VERSION ""

NS_ :

BS_:

BU_: SBZA_R_LS SBZA_L_LS VIS2_LS SDM_LS PEPS_LS UPA_LS PTM_LS MSM_LS HFP_LS EOCM_F_LS ECC_LS DCAC_LS CGM_LS BSM_LS BCM_LS AOS_LS
VAL_TABLE_ vt_BooleanValues 1 "true" 0 "false" ;
VAL_TABLE_ ValidityStates 1 "Invalid" 0 "Valid" ;

BO_ 3221225472 VECTOR__INDEPENDENT_SIG_MSG: 0 Vector__XXX
 SG_ ODIEDDIPC_Data11Value : 0|3@0+ (1,0) [0|7] "" Vector__XXX
 SG_ ODIEDDIPC_Data10Value : 0|3@0+ (1,0) [0|7] "" Vector__XXX
 SG_ ODIEDDIPC_Data9Value : 0|3@0+ (1,0) [0|7] "" Vector__XXX
 SG_ ODIEDDIPC_Data8Value : 0|3@0+ (1,0) [0|7] "" Vector__XXX
 SG_ ODIEDDIPC_Data7Value : 0|3@0+ (1,0) [0|7] "" Vector__XXX
 SG_ ODIEDDIPC_Data6Value : 0|3@0+ (1,0) [0|7] "" Vector__XXX
 SG_ ODIEDDIPC_Data5Value : 0|3@0+ (1,0) [0|7] "" Vector__XXX
 SG_ ODIEDDIPC_Data4Value : 0|3@0+ (1,0) [0|7] "" Vector__XXX
 SG_ ODIEDDIPC_Data3Value : 0|3@0+ (1,0) [0|7] "" Vector__XXX
 SG_ ODIEDDIPC_Data2Value : 0|3@0+ (1,0) [0|7] "" Vector__XXX
 SG_ ODIEDDIPC_Data1Value : 0|3@0+ (1,0) [0|7] "" Vector__XXX
 SG_ ODIEDDCS_FUCID : 0|8@0+ (1,0) [0|255] "" Vector__XXX
 SG_ ODIEDDCS_Data9Value : 0|3@0+ (1,0) [0|7] "" Vector__XXX
 SG_ ODIEDDCS_Data8Value : 0|3@0+ (1,0) [0|7] "" Vector__XXX
 SG_ ODIEDDCS_Data7Value : 0|3@0+ (1,0) [0|7] "" Vector__XXX
 SG_ ODIEDDCS_Data6Value : 0|3@0+ (1,0) [0|7] "" Vector__XXX
 SG_ ODIEDDCS_Data5Value : 0|3@0+ (1,0) [0|7] "" Vector__XXX
 SG_ ODIEDDCS_Data4Value : 0|3@0+ (1,0) [0|7] "" Vector__XXX
 SG_ ODIEDDCS_Data3Value : 0|3@0+ (1,0) [0|7] "" Vector__XXX
 SG_ ODIEDDCS_Data2Value : 0|3@0+ (1,0) [0|7] "" Vector__XXX
 SG_ ODIEDDCS_Data18Value : 0|3@0+ (1,0) [0|7] "" Vector__XXX
 SG_ ODIEDDCS_Data17Value : 0|3@0+ (1,0) [0|7] "" Vector__XXX
 SG_ ODIEDDCS_Data16Value : 0|3@0+ (1,0) [0|7] "" Vector__XXX
 SG_ ODIEDDCS_Data15Value : 0|3@0+ (1,0) [0|7] "" Vector__XXX
 SG_ ODIEDDCS_Data14Value : 0|3@0+ (1,0) [0|7] "" Vector__XXX
 SG_ ODIEDDCS_Data13Value : 0|3@0+ (1,0) [0|7] "" Vector__XXX
 SG_ ODIEDDCS_Data12Value : 0|3@0+ (1,0) [0|7] "" Vector__XXX
 SG_ ODIEDDCS_Data11Value : 0|3@0+ (1,0) [0|7] "" Vector__XXX
 SG_ ODIEDDCS_Data10Value : 0|3@0+ (1,0) [0|7] "" Vector__XXX
 SG_ ODIEDDCS_Data1Value : 0|3@0+ (1,0) [0|7] "" Vector__XXX
 SG_ ODIEDDIPC_FUCID : 0|8@0+ (1,0) [0|255] "" Vector__XXX
 SG_ ODIEDDIPC_Data18Value : 0|3@0+ (1,0) [0|7] "" Vector__XXX
 SG_ ODIEDDIPC_Data17Value : 0|3@0+ (1,0) [0|7] "" Vector__XXX
 SG_ ODIEDDIPC_Data16Value : 0|3@0+ (1,0) [0|7] "" Vector__XXX
 SG_ ODIEDDIPC_Data15Value : 0|3@0+ (1,0) [0|7] "" Vector__XXX
 SG_ ODIEDDIPC_Data14Value : 0|3@0+ (1,0) [0|7] "" Vector__XXX
 SG_ ODIEDDIPC_Data13Value : 0|3@0+ (1,0) [0|7] "" Vector__XXX
 SG_ ODIEDDIPC_Data12Value : 0|3@0+ (1,0) [0|7] "" Vector__XXX
 SG_ DrThrtlOvrrdDetProtVal : 0|2@0+ (1,0) [0|3] "" Vector__XXX
 SG_ IMUProtLonAccM : 0|1@0+ (1,0) [0|1] "" Vector__XXX
 SG_ ARSActAngl : 0|11@0- (0.01,0) [-10.24|10.23] "deg" Vector__XXX
 SG_ BPDAPS_BkPDrvApPV : 0|1@0+ (1,0) [0|1] "" Vector__XXX
 SG_ BPDAPS_BkPDrvApP : 0|8@0+ (75,0) [0|19125] "kPa" Vector__XXX
 SG_ DrvThrottlOvrrdDet : 0|1@0+ (1,0) [0|1] "" Vector__XXX
 SG_ OvrdrvDsblReqd : 0|1@0+ (1,0) [0|1] "" Vector__XXX

BO_ 599 USDT_Req_to_SBZA_R_LS: 8 CGM_LS
 SG_ DgnInf : 7|64@0+ (1,0) [0|1.84467440737096E+019] ""  SBZA_R_LS

BO_ 1367 UUDT_Resp_From_SBZA_R_LS: 8 SBZA_R_LS
 SG_ DgnInf_LS557 : 7|64@0+ (1,0) [0|1.84467440737096E+019] ""  CGM_LS

BO_ 1623 USDT_Resp_From_SBZA_R_LS: 8 SBZA_R_LS
 SG_ DgnInf : 7|64@0+ (1,0) [0|1.84467440737096E+019] ""  CGM_LS

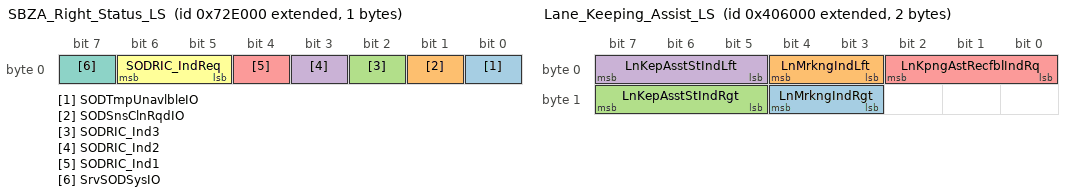
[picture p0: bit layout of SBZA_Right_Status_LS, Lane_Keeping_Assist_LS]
BO_ 2155012096 SBZA_Right_Status_LS: 1 SBZA_R_LS
 SG_ SODTmpUnavlbleIO : 0|1@0+ (1,0) [0|1] ""  SBZA_L_LS
 SG_ SODSnsClnRqdIO : 1|1@0+ (1,0) [0|1] ""  SBZA_L_LS
 SG_ SODRIC_Ind3 : 2|1@0+ (1,0) [0|1] ""  SBZA_L_LS
 SG_ SODRIC_Ind2 : 3|1@0+ (1,0) [0|1] ""  SBZA_L_LS
 SG_ SODRIC_Ind1 : 4|1@0+ (1,0) [0|1] ""  SBZA_L_LS
 SG_ SODRIC_IndReq : 6|2@0+ (1,0) [0|3] ""  SBZA_L_LS
 SG_ SrvSODSysIO : 7|1@0+ (1,0) [0|1] ""  SBZA_L_LS

BO_ 932 Temp_Diag_CAN_Resp_LS_3A4: 8 Vector__XXX
 SG_ DgnInf : 7|64@0+ (1,0) [0|1.84467440737096E+019] ""  CGM_LS

BO_ 936 Temp_Diag_CAN_Resp_LS_3A8: 8 Vector__XXX
 SG_ DgnInf : 7|64@0+ (1,0) [0|1.84467440737096E+019] ""  CGM_LS

BO_ 921 Temp_Diag_CAN_Resp_LS_399: 8 Vector__XXX
 SG_ DgnInf : 7|64@0+ (1,0) [0|1.84467440737096E+019] ""  CGM_LS

BO_ 2151702528 Lane_Keeping_Assist_LS: 2 EOCM_F_LS
 SG_ LnMrkngIndRgt : 12|2@0+ (1,0) [0|3] ""  CGM_LS
 SG_ LnMrkngIndLft : 4|2@0+ (1,0) [0|3] ""  CGM_LS
 SG_ LnKepAsstStIndRgt : 15|3@0+ (1,0) [0|7] ""  CGM_LS
 SG_ LnKepAsstStIndLft : 7|3@0+ (1,0) [0|7] ""  CGM_LS
 SG_ LnKpngAstRecfblIndRq : 2|3@0+ (1,0) [0|7] ""  CGM_LS

BO_ 2155126784 Drvr_Seat_Rearward_Movmnt_LS: 1 MSM_LS
 SG_ DrvrSetRrwrdMvmnt : 7|3@0+ (1,0) [0|7] ""  CGM_LS

BO_ 2155102208 Driver_Seat_Massage_Priority_LS: 8 MSM_LS
 SG_ DSMP_UnsdRsrvd : 56|1@0+ (1,0) [0|1] ""  CGM_LS
 SG_ DSMP_MaxDispVal : 59|3@0+ (1,0) [0|7] ""  CGM_LS
 SG_ DSMP_Type15 : 63|4@0+ (1,0) [0|15] ""  CGM_LS
 SG_ DSMP_Type14 : 51|4@0+ (1,0) [0|15] ""  CGM_LS
 SG_ DSMP_Type13 : 55|4@0+ (1,0) [0|15] ""  CGM_LS
 SG_ DSMP_Type12 : 43|4@0+ (1,0) [0|15] ""  CGM_LS
 SG_ DSMP_Type11 : 47|4@0+ (1,0) [0|15] ""  CGM_LS
 SG_ DSMP_Type10 : 35|4@0+ (1,0) [0|15] ""  CGM_LS
 SG_ DSMP_Type9 : 39|4@0+ (1,0) [0|15] ""  CGM_LS
 SG_ DSMP_Type8 : 27|4@0+ (1,0) [0|15] ""  CGM_LS
 SG_ DSMP_Type7 : 31|4@0+ (1,0) [0|15] ""  CGM_LS
 SG_ DSMP_Type6 : 19|4@0+ (1,0) [0|15] ""  CGM_LS
 SG_ DSMP_Type5 : 23|4@0+ (1,0) [0|15] ""  CGM_LS
 SG_ DSMP_Type4 : 11|4@0+ (1,0) [0|15] ""  CGM_LS
 SG_ DSMP_Type3 : 15|4@0+ (1,0) [0|15] ""  CGM_LS
 SG_ DSMP_Type2 : 3|4@0+ (1,0) [0|15] ""  CGM_LS
 SG_ DSMP_Type1 : 7|4@0+ (1,0) [0|15] ""  CGM_LS

BO_ 2155085824 Driver_Seat_Control_Disp_Stat_LS: 8 MSM_LS
 SG_ StrgColUpDwnPos : 63|8@0+ (1,0) [0|255] ""  CGM_LS
 SG_ CPMAPINFO4 : 5|1@0+ (1,0) [0|1] ""  CGM_LS
 SG_ StrgColInOutPos : 55|8@0+ (1,0) [0|255] ""  CGM_LS
 SG_ StrgColCommsFlt : 7|2@0+ (1,0) [0|3] ""  CGM_LS
 SG_ DSCDS_UnsdRsrvd : 42|3@0+ (1,0) [0|7] ""  CGM_LS
 SG_ DSCDS_DispReq : 43|1@0+ (1,0) [0|1] ""  CGM_LS
 SG_ DSCDS_DispSz : 45|2@0+ (1,0) [0|3] ""  CGM_LS
 SG_ DSCDS_CshLgAdjFdRr : 47|2@0+ (1,0) [0|3] ""  CGM_LS
 SG_ DSCDS_BkCshBlstInOt : 34|3@0+ (1,0) [0|7] ""  CGM_LS
 SG_ DSCDS_CshBlstrInOut : 36|2@0+ (1,0) [0|3] ""  CGM_LS
 SG_ DSCDS_BkBlstrInOut : 38|2@0+ (1,0) [0|3] ""  CGM_LS
 SG_ DSCDS_LmbrUDnFdRr : 25|3@0+ (1,0) [0|7] ""  CGM_LS
 SG_ DSCDS_LmbrFwdRr : 27|2@0+ (1,0) [0|3] ""  CGM_LS
 SG_ DSCDS_LmbrUpDwn : 29|2@0+ (1,0) [0|3] ""  CGM_LS
 SG_ DSCDS_UprShldrFdRr : 31|2@0+ (1,0) [0|3] ""  CGM_LS
 SG_ DSCDS_HdrstTltFwdRr : 17|2@0+ (1,0) [0|3] ""  CGM_LS
 SG_ DSCDS_HdrstWngInOt : 19|2@0+ (1,0) [0|3] ""  CGM_LS
 SG_ DSCDS_HdrstUDnFdRr : 22|3@0+ (1,0) [0|7] ""  CGM_LS
 SG_ DSCDS_HdrstFwdRrwd : 8|2@0+ (1,0) [0|3] ""  CGM_LS
 SG_ DSCDS_HdrstUpDn : 10|2@0+ (1,0) [0|3] ""  CGM_LS
 SG_ DSCDS_MassgIntsty : 13|3@0+ (1,0) [0|7] ""  CGM_LS
 SG_ DSCDS_MassgTyp : 1|4@0+ (1,0) [0|15] ""  CGM_LS
 SG_ DSCDS_Massg : 3|2@0+ (1,0) [0|3] ""  CGM_LS

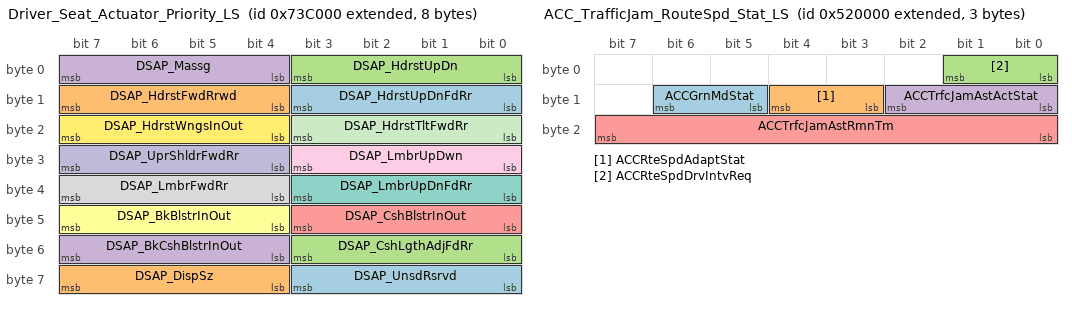
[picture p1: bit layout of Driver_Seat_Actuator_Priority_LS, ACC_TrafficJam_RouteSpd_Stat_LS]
BO_ 2155069440 Driver_Seat_Actuator_Priority_LS: 8 MSM_LS
 SG_ DSAP_UnsdRsrvd : 59|4@0+ (1,0) [0|15] ""  CGM_LS
 SG_ DSAP_DispSz : 63|4@0+ (1,0) [0|15] ""  CGM_LS
 SG_ DSAP_CshLgthAdjFdRr : 51|4@0+ (1,0) [0|15] ""  CGM_LS
 SG_ DSAP_BkCshBlstrInOut : 55|4@0+ (1,0) [0|15] ""  CGM_LS
 SG_ DSAP_CshBlstrInOut : 43|4@0+ (1,0) [0|15] ""  CGM_LS
 SG_ DSAP_BkBlstrInOut : 47|4@0+ (1,0) [0|15] ""  CGM_LS
 SG_ DSAP_LmbrUpDnFdRr : 35|4@0+ (1,0) [0|15] ""  CGM_LS
 SG_ DSAP_LmbrFwdRr : 39|4@0+ (1,0) [0|15] ""  CGM_LS
 SG_ DSAP_LmbrUpDwn : 27|4@0+ (1,0) [0|15] ""  CGM_LS
 SG_ DSAP_UprShldrFwdRr : 31|4@0+ (1,0) [0|15] ""  CGM_LS
 SG_ DSAP_HdrstTltFwdRr : 19|4@0+ (1,0) [0|15] ""  CGM_LS
 SG_ DSAP_HdrstWngsInOut : 23|4@0+ (1,0) [0|15] ""  CGM_LS
 SG_ DSAP_HdrstUpDnFdRr : 11|4@0+ (1,0) [0|15] ""  CGM_LS
 SG_ DSAP_HdrstFwdRrwd : 15|4@0+ (1,0) [0|15] ""  CGM_LS
 SG_ DSAP_HdrstUpDn : 3|4@0+ (1,0) [0|15] ""  CGM_LS
 SG_ DSAP_Massg : 7|4@0+ (1,0) [0|15] ""  CGM_LS

BO_ 2034 CCP_Data_Transmission_Object_LS: 8 VIS2_LS
 SG_ DgnInf : 7|64@0+ (1,0) [0|1.84467440737096E+019] "" Vector__XXX

BO_ 2152857600 ACC_TrafficJam_RouteSpd_Stat_LS: 3 EOCM_F_LS
 SG_ ACCGrnMdStat : 14|2@0+ (1,0) [0|3] ""  CGM_LS
 SG_ ACCRteSpdAdaptStat : 12|2@0+ (1,0) [0|3] ""  CGM_LS
 SG_ ACCRteSpdDrvIntvReq : 1|2@0+ (1,0) [0|3] ""  CGM_LS
 SG_ ACCTrfcJamAstActStat : 10|3@0+ (1,0) [0|7] ""  CGM_LS
 SG_ ACCTrfcJamAstRmnTm : 23|8@0+ (1,0) [0|255] "sec"  CGM_LS

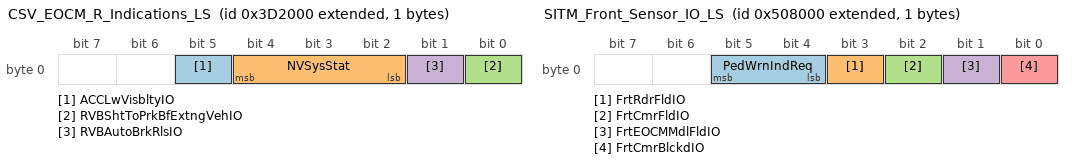
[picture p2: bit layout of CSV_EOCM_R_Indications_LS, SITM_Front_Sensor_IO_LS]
BO_ 2151489536 CSV_EOCM_R_Indications_LS: 1 EOCM_F_LS
 SG_ ACCLwVisbltyIO : 5|1@0+ (1,0) [0|1] ""  CGM_LS
 SG_ NVSysStat : 4|3@0+ (1,0) [0|7] ""  CGM_LS
 SG_ RVBShtToPrkBfExtngVehIO : 0|1@0+ (1,0) [0|1] ""  CGM_LS
 SG_ RVBAutoBrkRlsIO : 1|1@0+ (1,0) [0|1] ""  CGM_LS

BO_ 2152759296 SITM_Front_Sensor_IO_LS: 1 EOCM_F_LS
 SG_ PedWrnIndReq : 5|2@0+ (1,0) [0|3] ""  CGM_LS
 SG_ FrtRdrFldIO : 3|1@0+ (1,0) [0|1] ""  CGM_LS
 SG_ FrtCmrFldIO : 2|1@0+ (1,0) [0|1] ""  CGM_LS
 SG_ FrtEOCMMdlFldIO : 1|1@0+ (1,0) [0|1] ""  CGM_LS
 SG_ FrtCmrBlckdIO : 0|1@0+ (1,0) [0|1] ""  CGM_LS

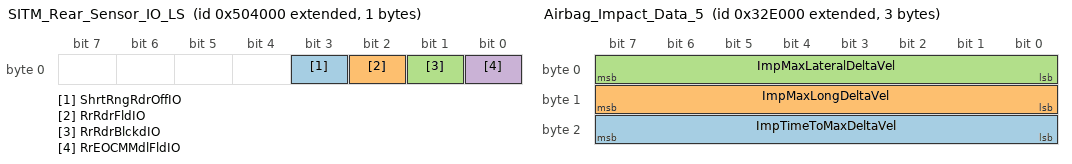
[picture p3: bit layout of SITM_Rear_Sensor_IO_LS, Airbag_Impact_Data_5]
BO_ 2152742912 SITM_Rear_Sensor_IO_LS: 1 EOCM_F_LS
 SG_ ShrtRngRdrOffIO : 3|1@0+ (1,0) [0|1] ""  CGM_LS
 SG_ RrRdrFldIO : 2|1@0+ (1,0) [0|1] ""  CGM_LS
 SG_ RrRdrBlckdIO : 1|1@0+ (1,0) [0|1] ""  CGM_LS
 SG_ RrEOCMMdlFldIO : 0|1@0+ (1,0) [0|1] ""  CGM_LS

BO_ 1591 VNMF_LS_637_SBZA_R: 8 SBZA_R_LS
 SG_ VectraSpcNWMgtD : 7|64@0+ (1,0) [0|1.84467440737096E+019] ""  SBZA_L_LS

BO_ 1355 UUDT_Resp_From_FCM_LS: 8 EOCM_F_LS
 SG_ DgnInf_LS54B : 7|64@0+ (1,0) [0|1.84467440737096E+019] ""  CGM_LS

BO_ 1611 USDT_Resp_From_FCM_LS: 8 EOCM_F_LS
 SG_ DgnInf : 7|64@0+ (1,0) [0|1.84467440737096E+019] ""  CGM_LS

BO_ 1603 USDT_Resp_From_AGC_LS: 8 DCAC_LS
 SG_ DgnInf : 7|64@0+ (1,0) [0|1.84467440737096E+019] ""  CGM_LS

BO_ 1347 UUDT_Resp_From_AGC_LS: 8 DCAC_LS
 SG_ DgnInf_LS543 : 7|64@0+ (1,0) [0|1.84467440737096E+019] ""  CGM_LS

BO_ 2154995712 Air_Conditioning_Comp_Type_LS: 1 ECC_LS
 SG_ HVHtrFldIO : 4|1@0+ (1,0) [0|1] ""  CGM_LS
 SG_ HVHtrOvrTmpIndOn : 3|1@0+ (1,0) [0|1] ""  CGM_LS

BO_ 2150817792 Airbag_Impact_Data_5: 3 SDM_LS
 SG_ ImpTimeToMaxDeltaVel : 23|8@0+ (10,0) [0|2550] "ms"  CGM_LS
 SG_ ImpMaxLongDeltaVel : 15|8@0- (1,0) [-128|127] ""  CGM_LS
 SG_ ImpMaxLateralDeltaVel : 7|8@0- (1,0) [-128|127] ""  CGM_LS

BO_ 1621 USDT_Resp_From_VIS2_LS: 8 VIS2_LS
 SG_ DgnInf : 7|64@0+ (1,0) [0|1.84467440737096E+019] ""  CGM_LS

BO_ 1365 UUDT_Resp_From_VIS2_LS: 8 VIS2_LS
 SG_ DgnInf_LS555 : 7|64@0+ (1,0) [0|1.84467440737096E+019] ""  CGM_LS

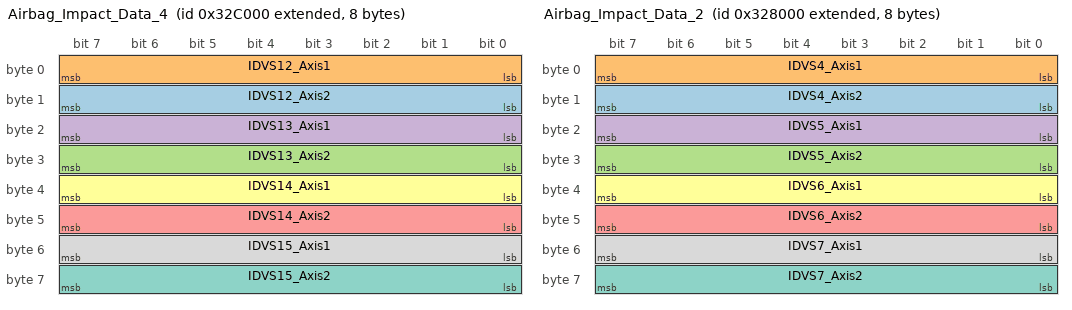
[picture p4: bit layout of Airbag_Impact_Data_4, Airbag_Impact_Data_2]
BO_ 2150809600 Airbag_Impact_Data_4: 8 SDM_LS
 SG_ IDVS12_Axis2 : 15|8@0- (1,0) [-128|127] "counts"  CGM_LS
 SG_ IDVS12_Axis1 : 7|8@0- (1,0) [-128|127] "counts"  CGM_LS
 SG_ IDVS13_Axis2 : 31|8@0- (1,0) [-128|127] "counts"  CGM_LS
 SG_ IDVS13_Axis1 : 23|8@0- (1,0) [-128|127] "counts"  CGM_LS
 SG_ IDVS14_Axis2 : 47|8@0- (1,0) [-128|127] "counts"  CGM_LS
 SG_ IDVS14_Axis1 : 39|8@0- (1,0) [-128|127] "counts"  CGM_LS
 SG_ IDVS15_Axis2 : 63|8@0- (1,0) [-128|127] "counts"  CGM_LS
 SG_ IDVS15_Axis1 : 55|8@0- (1,0) [-128|127] "counts"  CGM_LS

BO_ 2150793216 Airbag_Impact_Data_2: 8 SDM_LS
 SG_ IDVS4_Axis2 : 15|8@0- (1,0) [-128|127] "counts"  CGM_LS
 SG_ IDVS4_Axis1 : 7|8@0- (1,0) [-128|127] "counts"  CGM_LS
 SG_ IDVS5_Axis2 : 31|8@0- (1,0) [-128|127] "counts"  CGM_LS
 SG_ IDVS5_Axis1 : 23|8@0- (1,0) [-128|127] "counts"  CGM_LS
 SG_ IDVS6_Axis2 : 47|8@0- (1,0) [-128|127] "counts"  CGM_LS
 SG_ IDVS6_Axis1 : 39|8@0- (1,0) [-128|127] "counts"  CGM_LS
 SG_ IDVS7_Axis2 : 63|8@0- (1,0) [-128|127] "counts"  CGM_LS
 SG_ IDVS7_Axis1 : 55|8@0- (1,0) [-128|127] "counts"  CGM_LS

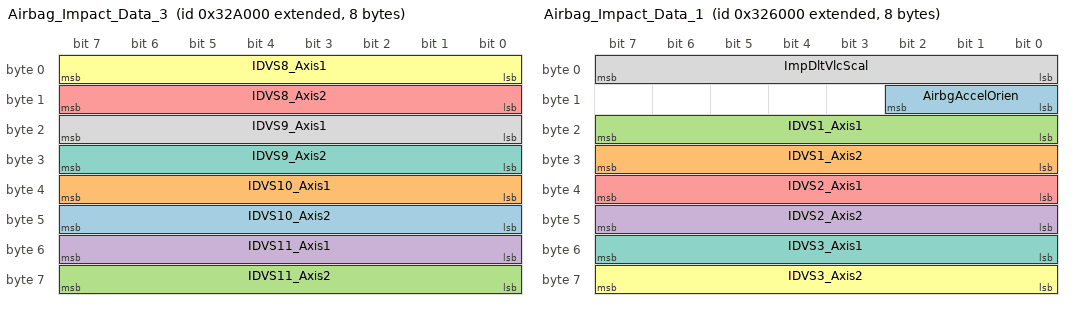
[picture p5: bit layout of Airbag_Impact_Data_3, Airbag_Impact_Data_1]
BO_ 2150801408 Airbag_Impact_Data_3: 8 SDM_LS
 SG_ IDVS10_Axis2 : 47|8@0- (1,0) [-128|127] "counts"  CGM_LS
 SG_ IDVS10_Axis1 : 39|8@0- (1,0) [-128|127] "counts"  CGM_LS
 SG_ IDVS11_Axis2 : 63|8@0- (1,0) [-128|127] "counts"  CGM_LS
 SG_ IDVS11_Axis1 : 55|8@0- (1,0) [-128|127] "counts"  CGM_LS
 SG_ IDVS8_Axis2 : 15|8@0- (1,0) [-128|127] "counts"  CGM_LS
 SG_ IDVS8_Axis1 : 7|8@0- (1,0) [-128|127] "counts"  CGM_LS
 SG_ IDVS9_Axis2 : 31|8@0- (1,0) [-128|127] "counts"  CGM_LS
 SG_ IDVS9_Axis1 : 23|8@0- (1,0) [-128|127] "counts"  CGM_LS

BO_ 2150785024 Airbag_Impact_Data_1: 8 SDM_LS
 SG_ AirbgAccelOrien : 10|3@0+ (45,0) [0|315] "deg"  CGM_LS
 SG_ IDVS1_Axis2 : 31|8@0- (1,0) [-128|127] "counts"  CGM_LS
 SG_ IDVS1_Axis1 : 23|8@0- (1,0) [-128|127] "counts"  CGM_LS
 SG_ IDVS2_Axis2 : 47|8@0- (1,0) [-128|127] "counts"  CGM_LS
 SG_ IDVS2_Axis1 : 39|8@0- (1,0) [-128|127] "counts"  CGM_LS
 SG_ IDVS3_Axis2 : 63|8@0- (1,0) [-128|127] "counts"  CGM_LS
 SG_ IDVS3_Axis1 : 55|8@0- (1,0) [-128|127] "counts"  CGM_LS
 SG_ ImpDltVlcScal : 7|8@0+ (0.00245,0.706) [0.706|1.33075] "kph/cnt"  CGM_LS

BO_ 2150825984 Airbag_Indications: 6 SDM_LS
 SG_ PdstIntdProtSysDplyd : 46|1@0+ (1,0) [0|1] ""  CGM_LS
 SG_ PdstIntdProtSysDsbld : 45|1@0+ (1,0) [0|1] ""  CGM_LS
 SG_ SrvIntdPdstProtSysIO : 44|1@0+ (1,0) [0|1] ""  CGM_LS
 SG_ FstnThrdRwRtPsStbtInR : 41|2@0+ (1,0) [0|3] ""  CGM_LS
 SG_ FstnThrdRwLtPsStbtInR : 43|2@0+ (1,0) [0|3] ""  CGM_LS
 SG_ FstnThrdRwCtPsStbtInR : 39|2@0+ (1,0) [0|3] ""  CGM_LS
 SG_ FPSIC_IndPer : 11|4@0+ (1,0) [0|15] ""  CGM_LS
 SG_ FPSIC_IO : 15|1@0+ (1,0) [0|1] ""  CGM_LS
 SG_ FPSIC_IndDtCyc : 14|3@0+ (12.5,12.5) [12.5|100] "%"  CGM_LS
 SG_ FDSIC_IndPer : 3|4@0+ (1,0) [0|15] ""  CGM_LS
 SG_ FDSIC_IO : 7|1@0+ (1,0) [0|1] ""  CGM_LS
 SG_ FDSIC_IndDC : 6|3@0+ (12.5,12.5) [12.5|100] "%"  CGM_LS
 SG_ AirbgFldIO : 35|1@0+ (1,0) [0|1] ""  CGM_LS
 SG_ SndRwStbltRdIndMd : 37|2@0+ (1,0) [0|3] ""  CGM_LS
 SG_ AirbgICIndPer : 19|4@0+ (1,0) [0|15] ""  CGM_LS
 SG_ AirbgICDutCyc : 22|3@0+ (12.5,12.5) [12.5|100] "%"  CGM_LS
 SG_ AirbgICIO : 23|1@0+ (1,0) [0|1] ""  CGM_LS
 SG_ FstnSndRwRtPsStbtInR : 29|2@0+ (1,0) [0|3] ""  CGM_LS
 SG_ FstnSndRwLtPsStbtInR : 25|2@0+ (1,0) [0|3] ""  CGM_LS
 SG_ FstnSndRwCtPsStbtInR : 27|2@0+ (1,0) [0|3] ""  CGM_LS
 SG_ FsnDrStbAuxIR : 31|2@0+ (1,0) [0|3] ""  CGM_LS
 SG_ FsnPsStbAuxIR : 34|3@0+ (1,0) [0|7] ""  CGM_LS

BO_ 1351 UUDT_Resp_From_SDM_LS: 8 SDM_LS
 SG_ DgnInf_LS547 : 7|64@0+ (1,0) [0|1.84467440737096E+019] ""  CGM_LS

BO_ 1607 USDT_Resp_From_SDM_LS: 8 SDM_LS
 SG_ DgnInf : 7|64@0+ (1,0) [0|1.84467440737096E+019] ""  CGM_LS

BO_ 1602 USDT_Resp_From_PEPS_PBSM_LS: 8 PEPS_LS
 SG_ DgnInf : 7|64@0+ (1,0) [0|1.84467440737096E+019] ""  CGM_LS

BO_ 1346 UUDT_Resp_From_PEPS_PBSM_LS: 8 PEPS_LS
 SG_ DgnInf_LS542 : 7|64@0+ (1,0) [0|1.84467440737096E+019] ""  CGM_LS

BO_ 1361 UUDT_Resp_From_ECC_HVAC_LS: 8 ECC_LS
 SG_ DgnInf_LS551 : 7|64@0+ (1,0) [0|1.84467440737096E+019] ""  CGM_LS

BO_ 1617 USDT_Resp_From_ECC_HVAC_LS: 8 ECC_LS
 SG_ DgnInf : 7|64@0+ (1,0) [0|1.84467440737096E+019] ""  CGM_LS

BO_ 1373 UUDT_Resp_From_DSM_LS: 8 MSM_LS
 SG_ DgnInf_LS55D : 7|64@0+ (1,0) [0|1.84467440737096E+019] ""  CGM_LS

BO_ 1629 USDT_Resp_From_DSM_LS: 8 MSM_LS
 SG_ DgnInf : 7|64@0+ (1,0) [0|1.84467440737096E+019] ""  CGM_LS

BO_ 602 USDT_Req_to_SBZA_L_LS: 8 CGM_LS
 SG_ DgnInf : 7|64@0+ (1,0) [0|1.84467440737096E+019] ""  SBZA_L_LS

BO_ 164 Temp_Diag_CAN_Req_LS_0A4: 8 CGM_LS
 SG_ DgnInf : 7|64@0+ (1,0) [0|1.84467440737096E+019] "" Vector__XXX

BO_ 104 Temp_Diag_CAN_Req_LS_068: 8 CGM_LS
 SG_ DgnInf : 7|64@0+ (1,0) [0|1.84467440737096E+019] "" Vector__XXX

BO_ 88 Temp_Diag_CAN_Req_LS_058: 8 CGM_LS
 SG_ DgnInf : 7|64@0+ (1,0) [0|1.84467440737096E+019] "" Vector__XXX

BO_ 168 Temp_Diag_CAN_Req_LS_0A8: 8 CGM_LS
 SG_ DgnInf : 7|64@0+ (1,0) [0|1.84467440737096E+019] "" Vector__XXX

BO_ 153 Temp_Diag_CAN_Req_LS_099: 8 CGM_LS
 SG_ DgnInf : 7|64@0+ (1,0) [0|1.84467440737096E+019] "" Vector__XXX

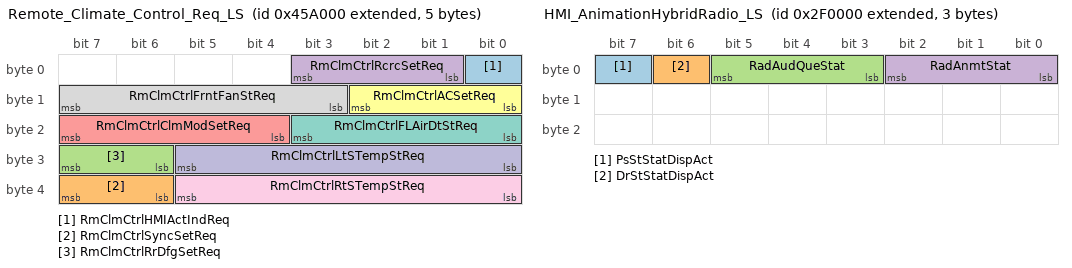
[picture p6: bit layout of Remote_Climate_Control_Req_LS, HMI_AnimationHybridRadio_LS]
BO_ 2152046592 Remote_Climate_Control_Req_LS: 5 CGM_LS
 SG_ RmClmCtrlHMIActIndReq : 0|1@0+ (1,0) [0|1] ""  ECC_LS
 SG_ RmClmCtrlSyncSetReq : 39|2@0+ (1,0) [0|3] ""  ECC_LS
 SG_ RmClmCtrlRrDfgSetReq : 31|2@0+ (1,0) [0|3] ""  ECC_LS
 SG_ RmClmCtrlRcrcSetReq : 3|3@0+ (1,0) [0|7] ""  ECC_LS
 SG_ RmClmCtrlClmModSetReq : 23|4@0+ (1,0) [0|15] ""  ECC_LS
 SG_ RmClmCtrlACSetReq : 10|3@0+ (1,0) [0|7] ""  ECC_LS
 SG_ RmClmCtrlFLAirDtStReq : 19|4@0+ (1,0) [0|15] ""  ECC_LS
 SG_ RmClmCtrlFrntFanStReq : 15|5@0+ (1,0) [0|31] ""  ECC_LS
 SG_ RmClmCtrlRtSTempStReq : 37|6@0+ (1,0) [0|63] ""  ECC_LS
 SG_ RmClmCtrlLtSTempStReq : 29|6@0+ (1,0) [0|63] ""  ECC_LS

BO_ 2032 CCP_Command_Receive_Object_LS: 8 CGM_LS
 SG_ DgnInf : 7|64@0+ (1,0) [0|1.84467440737096E+019] ""  PTM_LS,VIS2_LS

BO_ 2150563840 HMI_AnimationHybridRadio_LS: 3 CGM_LS
 SG_ PsStStatDispAct : 7|1@0+ (1,0) [0|1] "" Vector__XXX
 SG_ DrStStatDispAct : 6|1@0+ (1,0) [0|1] ""  MSM_LS
 SG_ RadAudQueStat : 5|3@0+ (1,0) [0|7] "" Vector__XXX
 SG_ RadAnmtStat : 2|3@0+ (1,0) [0|7] "" Vector__XXX

BO_ 2151948288 Driver_Drow_Det_Cst_Rqst_LS: 1 CGM_LS
 SG_ RunBrdOpMdCstStReq : 7|3@0+ (1,0) [0|7] "" Vector__XXX
 SG_ DrvDrowDetCstStRq : 2|3@0+ (1,0) [0|7] ""  VIS2_LS

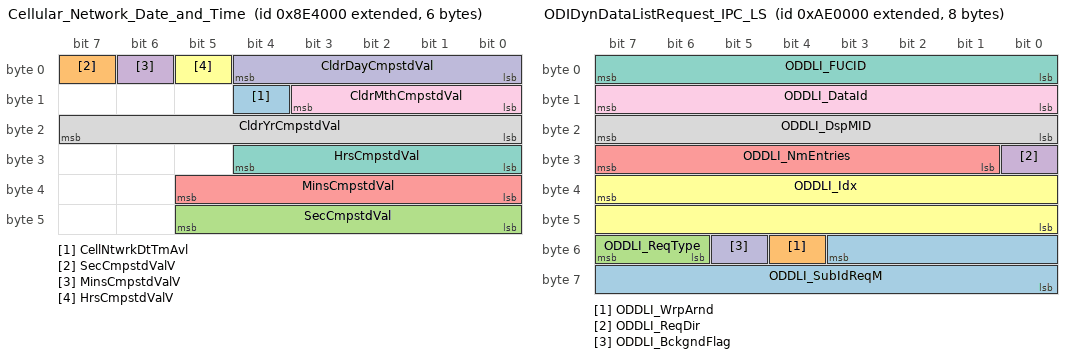
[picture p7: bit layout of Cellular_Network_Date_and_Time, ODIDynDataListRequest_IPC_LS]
BO_ 2156806144 Cellular_Network_Date_and_Time: 6 CGM_LS
 SG_ CellNtwrkDtTmAvl : 12|1@0+ (1,0) [0|1] "" Vector__XXX
 SG_ SecCmpstdValV : 7|1@0+ (1,0) [0|1] "" Vector__XXX
 SG_ SecCmpstdVal : 45|6@0+ (1,0) [0|63] "secs" Vector__XXX
 SG_ MinsCmpstdValV : 6|1@0+ (1,0) [0|1] "" Vector__XXX
 SG_ MinsCmpstdVal : 37|6@0+ (1,0) [0|63] "min" Vector__XXX
 SG_ HrsCmpstdValV : 5|1@0+ (1,0) [0|1] "" Vector__XXX
 SG_ HrsCmpstdVal : 28|5@0+ (1,0) [0|31] "h" Vector__XXX
 SG_ CldrYrCmpstdVal : 23|8@0+ (1,2000) [2000|2255] "year" Vector__XXX
 SG_ CldrMthCmpstdVal : 11|4@0+ (1,0) [0|15] ""  ECC_LS
 SG_ CldrDayCmpstdVal : 4|5@0+ (1,0) [0|31] "days"  ECC_LS

BO_ 1350 UUDT_Resp_From_ICS_LS: 8 CGM_LS
 SG_ DgnInf_LS546 : 7|64@0+ (1,0) [0|1.84467440737096E+019] ""  CGM_LS

BO_ 2158886912 ODIDynDataListRequest_IPC_LS: 8 CGM_LS
 SG_ ODDLI_SubIdReqM : 51|12@0+ (1,0) [0|4095] ""  VIS2_LS
 SG_ ODDLI_WrpArnd : 52|1@0+ (1,0) [0|1] ""  VIS2_LS
 SG_ ODDLI_ReqType : 55|2@0+ (1,0) [0|3] ""  VIS2_LS
 SG_ ODDLI_ReqDir : 24|1@0+ (1,0) [0|1] ""  VIS2_LS
 SG_ ODDLI_NmEntries : 31|7@0+ (1,0) [0|127] ""  VIS2_LS
 SG_ ODDLI_Idx : 39|16@0+ (1,0) [0|65535] ""  VIS2_LS
 SG_ ODDLI_FUCID : 7|8@0+ (1,0) [0|255] ""  VIS2_LS
 SG_ ODDLI_DspMID : 23|8@0+ (1,0) [0|255] ""  VIS2_LS
 SG_ ODDLI_DataId : 15|8@0+ (1,0) [0|255] ""  VIS2_LS
 SG_ ODDLI_BckgndFlag : 53|1@0+ (1,0) [0|1] ""  VIS2_LS

BO_ 579 USDT_Req_to_AGC_LS: 8 CGM_LS
 SG_ DgnInf : 7|64@0+ (1,0) [0|1.84467440737096E+019] ""  DCAC_LS

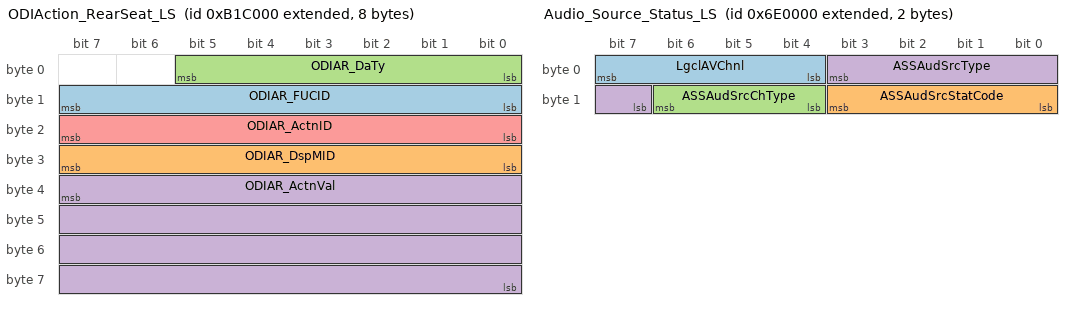
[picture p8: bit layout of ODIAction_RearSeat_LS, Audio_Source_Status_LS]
BO_ 2159132672 ODIAction_RearSeat_LS: 8 CGM_LS
 SG_ ODIAR_FUCID : 15|8@0+ (1,0) [0|255] ""  ECC_LS
 SG_ ODIAR_DspMID : 31|8@0+ (1,0) [0|255] ""  ECC_LS
 SG_ ODIAR_DaTy : 5|6@0+ (1,0) [0|63] ""  ECC_LS
 SG_ ODIAR_ActnVal : 39|32@0+ (1,0) [0|4294967295] ""  ECC_LS
 SG_ ODIAR_ActnID : 23|8@0+ (1,0) [0|255] ""  ECC_LS

BO_ 2154692608 Audio_Source_Status_LS: 2 CGM_LS
 SG_ LgclAVChnl : 7|4@0+ (1,0) [0|15] "" Vector__XXX
 SG_ ASSAudSrcStatCode : 11|4@0+ (1,0) [0|15] ""  ECC_LS
 SG_ ASSAudSrcChType : 14|3@0+ (1,0) [0|7] ""  ECC_LS
 SG_ ASSAudSrcType : 3|5@0+ (1,0) [0|31] ""  ECC_LS

BO_ 597 USDT_Req_to_VIS2_LS: 8 CGM_LS
 SG_ DgnInf : 7|64@0+ (1,0) [0|1.84467440737096E+019] ""  VIS2_LS

BO_ 1357 UUDT_Resp_From_UHP_ONS_LS: 8 CGM_LS
 SG_ DgnInf_LS54D : 7|64@0+ (1,0) [0|1.84467440737096E+019] ""  CGM_LS

BO_ 1608 USDT_Resp_From_PDIM_LS: 8 HFP_LS
 SG_ DgnInf : 7|64@0+ (1,0) [0|1.84467440737096E+019] ""  CGM_LS

BO_ 584 USDT_Req_to_PDIM_LS: 8 CGM_LS
 SG_ DgnInf : 7|64@0+ (1,0) [0|1.84467440737096E+019] ""  HFP_LS

BO_ 1352 UUDT_Resp_From_PDIM_LS: 8 CGM_LS
 SG_ DgnInf_LS548 : 7|64@0+ (1,0) [0|1.84467440737096E+019] ""  CGM_LS

BO_ 583 USDT_Req_to_SDM_LS: 8 CGM_LS
 SG_ DgnInf : 7|64@0+ (1,0) [0|1.84467440737096E+019] ""  SDM_LS

BO_ 1348 UUDT_Resp_From_RadioHead_LS: 8 CGM_LS
 SG_ DgnInf_LS544 : 7|64@0+ (1,0) [0|1.84467440737096E+019] ""  CGM_LS

BO_ 591 USDT_Req_to_PTM_STC_LS: 8 CGM_LS
 SG_ DgnInf : 7|64@0+ (1,0) [0|1.84467440737096E+019] ""  PTM_LS

BO_ 578 USDT_Req_to_PEPS_PBSM_LS: 8 CGM_LS
 SG_ DgnInf : 7|64@0+ (1,0) [0|1.84467440737096E+019] ""  PEPS_LS

BO_ 1356 UUDT_Resp_From_IPC_LS: 8 CGM_LS
 SG_ DgnInf_LS54C : 7|64@0+ (1,0) [0|1.84467440737096E+019] ""  CGM_LS

BO_ 1360 UUDT_Resp_From_HUD_LS: 8 CGM_LS
 SG_ DgnInf_LS550 : 7|64@0+ (1,0) [0|1.84467440737096E+019] ""  CGM_LS

BO_ 1616 USDT_Resp_From_HUD_LS: 8 CGM_LS
 SG_ DgnInf : 7|64@0+ (1,0) [0|1.84467440737096E+019] ""  CGM_LS

BO_ 593 USDT_Req_to_ECC_HVAC_LS: 8 CGM_LS
 SG_ DgnInf : 7|64@0+ (1,0) [0|1.84467440737096E+019] ""  ECC_LS

BO_ 605 USDT_Req_to_DSM_LS: 8 CGM_LS
 SG_ DgnInf : 7|64@0+ (1,0) [0|1.84467440737096E+019] ""  MSM_LS

BO_ 587 USDT_Req_to_FCM_LS: 8 CGM_LS
 SG_ DgnInf : 7|64@0+ (1,0) [0|1.84467440737096E+019] ""  EOCM_F_LS

BO_ 2020 USDT_Req_to_VICM_LS: 8 CGM_LS
 SG_ DgnInf : 7|64@0+ (1,0) [0|1.84467440737096E+019] ""  BSM_LS

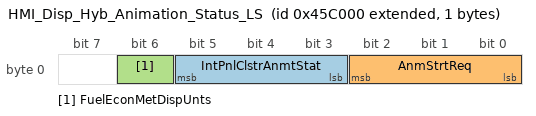
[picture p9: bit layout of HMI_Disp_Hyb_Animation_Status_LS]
BO_ 2152054784 HMI_Disp_Hyb_Animation_Status_LS: 1 CGM_LS
 SG_ IntPnlClstrAnmtStat : 5|3@0+ (1,0) [0|7] "" Vector__XXX
 SG_ AnmStrtReq : 2|3@0+ (1,0) [0|7] "" Vector__XXX
 SG_ FuelEconMetDispUnts : 6|1@0+ (1,0) [0|1] ""  BSM_LS

BO_ 2156281856 High_Volt_Bat_Time_Bsd_Req_1_LS: 7 CGM_LS
 SG_ LftmEffDtRstRqd : 18|1@0+ (1,0) [0|1] "" Vector__XXX
 SG_ HTRCsStReq : 37|3@0+ (1,0) [0|7] "" Vector__XXX
 SG_ TODCTmpImdtOvrdReq : 39|2@0+ (1,0) [0|3] ""  BSM_LS
 SG_ RtBsChrgCmplnTmPrfReq : 34|2@0+ (1,0) [0|3] ""  BSM_LS
 SG_ TONPDTR_StTmpOvrAtv : 32|2@0+ (1,0) [0|3] ""  BSM_LS
 SG_ TONPDTR_MntOfHr : 53|6@0+ (1,0) [0|63] "Minute"  BSM_LS
 SG_ TONPDTR_HrOfDy : 42|5@0+ (1,0) [0|31] "Hour"  BSM_LS
 SG_ TONPDTR_DyOfWk : 46|4@0+ (1,0) [0|15] ""  BSM_LS
 SG_ StTODChrgTmpOvrd : 7|1@0+ (1,0) [0|1] ""  BSM_LS
 SG_ HVBTBSCSR_SsnStReq : 0|2@0+ (1,0) [0|3] ""  BSM_LS
 SG_ HVBTBSCSR_SsnSlStReq : 14|3@0+ (1,0) [0|7] ""  BSM_LS
 SG_ HVBTBSCSR_SsnMthStReq : 11|4@0+ (1,0) [0|15] ""  BSM_LS
 SG_ HVBTBSCSR_SsnDayStReq : 23|5@0+ (1,0) [0|31] "day"  BSM_LS
 SG_ HVBTBCRSR_ChRtSlStReq : 27|4@0+ (1,0) [0|15] ""  BSM_LS
 SG_ HVBTBCRSR_ChRtEnblStReq : 17|2@0+ (1,0) [0|3] ""  BSM_LS
 SG_ HVBTBCRSR_ChRtDStReq : 31|4@0+ (1,0) [0|15] ""  BSM_LS
 SG_ HVBatTmBsChrgMdReq : 3|3@0+ (1,0) [0|7] ""  BSM_LS
 SG_ HVChgSyChgLvlPrfSt : 6|3@0+ (1,0) [0|7] ""  BSM_LS

BO_ 2156265472 High_Volt_Bat_Time_Bsd_Req_LS: 8 CGM_LS
 SG_ EngyUsgScrnMeasUtStat : 39|4@0+ (1,0) [0|15] ""  BSM_LS
 SG_ OffBrdHVCVehCsChRq : 35|1@0+ (1,0) [0|1] ""  BSM_LS
 SG_ PrtyChrgRq : 7|2@0+ (1,0) [0|3] ""  BSM_LS
 SG_ HVBTBRCSR_RtChSlStReq : 42|3@0+ (1,0) [0|7] ""  BSM_LS
 SG_ HVBTBRCSR_RtChSlRtStReq : 46|4@0+ (1,0) [0|15] ""  BSM_LS
 SG_ HVBTBRCSR_RtChSsnStReq : 50|2@0+ (1,0) [0|3] ""  BSM_LS
 SG_ HVBTBRCSR_RtChMHStReq : 48|6@0+ (1,0) [0|63] "min"  BSM_LS
 SG_ HVBTBRCSR_RtChHStReq : 55|5@0+ (1,0) [0|31] "hr"  BSM_LS
 SG_ HVBTBRCSR_RtChDStReq : 34|4@0+ (1,0) [0|15] ""  BSM_LS
 SG_ HVBTBRCSR_RtChSlTbRwReq : 58|3@0+ (1,0) [0|7] "rows"  BSM_LS
 SG_ HVBTBDCSRQ_DlChSlStReq : 19|4@0+ (1,0) [0|15] ""  BSM_LS
 SG_ HVBTBDCSRQ_DlChSsnStReq : 31|2@0+ (1,0) [0|3] ""  BSM_LS
 SG_ HVBTBDCSRQ_DlChMHStReq : 29|6@0+ (1,0) [0|63] "min"  BSM_LS
 SG_ HVBTBDCSRQ_DlChHStReq : 12|5@0+ (1,0) [0|31] "hr"  BSM_LS
 SG_ HVBTBDCSRQ_DlChDStReq : 23|4@0+ (1,0) [0|15] ""  BSM_LS
 SG_ ChgPwLsAlCzStRq : 5|3@0+ (1,0) [0|7] ""  BSM_LS
 SG_ ChgCdTfAlCzStRq : 2|3@0+ (1,0) [0|7] ""  BSM_LS
 SG_ ChgSysAudInCsStReq : 15|3@0+ (1,0) [0|7] ""  BSM_LS

BO_TX_BU_ 2034 : PTM_LS,VIS2_LS;
BO_TX_BU_ 1352 : HFP_LS,CGM_LS;

CM_ BU_ SBZA_R_LS "Side Blind Zone Alert Right";
CM_ BU_ SBZA_L_LS "Side Blind Zone Alert Left";
CM_ BU_ VIS2_LS "Vision Camera";
CM_ BU_ SDM_LS "Sensing Diagnostic Module";
CM_ BU_ PEPS_LS "Passive Entry Passive Start";
CM_ BU_ UPA_LS "Universal Parking Assist";
CM_ BU_ PTM_LS "Power Tailgate Module";
CM_ BU_ MSM_LS "Driver Seat Module";
CM_ BU_ HFP_LS "HVAC Faceplate";
CM_ BU_ EOCM_F_LS "External Object Control Module - Front";
CM_ BU_ ECC_LS "Electronic Climate Control";
CM_ BU_ DCAC_LS "DC-AC Power Inverter";
CM_ BU_ CGM_LS "Communication Gateway";
CM_ BU_ BSM_LS "Battery State Manager";
CM_ BU_ BCM_LS "Body Control Module and LS Side Global Architecture Gateway";
CM_ BU_ AOS_LS "Automatic Occupant Sensing";
CM_ BO_ 3221225472 "This is a message for not used signals, created by Vector CANdb++ DBC OLE DB Provider.";
CM_ SG_ 3221225472 ODIEDDIPC_Data11Value "ODI";
CM_ SG_ 3221225472 ODIEDDIPC_Data10Value "ODI";
CM_ SG_ 3221225472 ODIEDDIPC_Data9Value "ODI";
CM_ SG_ 3221225472 ODIEDDIPC_Data8Value "ODI";
CM_ SG_ 3221225472 ODIEDDIPC_Data7Value "ODI";
CM_ SG_ 3221225472 ODIEDDIPC_Data6Value "ODI";
CM_ SG_ 3221225472 ODIEDDIPC_Data5Value "ODI";
CM_ SG_ 3221225472 ODIEDDIPC_Data4Value "ODI";
CM_ SG_ 3221225472 ODIEDDIPC_Data3Value "ODI";
CM_ SG_ 3221225472 ODIEDDIPC_Data2Value "ODI";
CM_ SG_ 3221225472 ODIEDDIPC_Data1Value "ODI";
CM_ SG_ 3221225472 ODIEDDCS_FUCID "ODI - Primary ID of Functional Unit in FU Database";
CM_ SG_ 3221225472 ODIEDDCS_Data9Value "ODI";
CM_ SG_ 3221225472 ODIEDDCS_Data8Value "ODI";
CM_ SG_ 3221225472 ODIEDDCS_Data7Value "ODI";
CM_ SG_ 3221225472 ODIEDDCS_Data6Value "ODI";
CM_ SG_ 3221225472 ODIEDDCS_Data5Value "ODI";
CM_ SG_ 3221225472 ODIEDDCS_Data4Value "ODI";
CM_ SG_ 3221225472 ODIEDDCS_Data3Value "ODI";
CM_ SG_ 3221225472 ODIEDDCS_Data2Value "ODI";
CM_ SG_ 3221225472 ODIEDDCS_Data18Value "ODI";
CM_ SG_ 3221225472 ODIEDDCS_Data17Value "ODI";
CM_ SG_ 3221225472 ODIEDDCS_Data16Value "ODI";
CM_ SG_ 3221225472 ODIEDDCS_Data15Value "ODI";
CM_ SG_ 3221225472 ODIEDDCS_Data14Value "ODI";
CM_ SG_ 3221225472 ODIEDDCS_Data13Value "ODI";
CM_ SG_ 3221225472 ODIEDDCS_Data12Value "ODI";
CM_ SG_ 3221225472 ODIEDDCS_Data11Value "ODI";
CM_ SG_ 3221225472 ODIEDDCS_Data10Value "ODI";
CM_ SG_ 3221225472 ODIEDDCS_Data1Value "ODI";
CM_ SG_ 3221225472 ODIEDDIPC_FUCID "ODI - Primary ID of Functional Unit in FU Database";
CM_ SG_ 3221225472 ODIEDDIPC_Data18Value "ODI";
CM_ SG_ 3221225472 ODIEDDIPC_Data17Value "ODI";
CM_ SG_ 3221225472 ODIEDDIPC_Data16Value "ODI";
CM_ SG_ 3221225472 ODIEDDIPC_Data15Value "ODI";
CM_ SG_ 3221225472 ODIEDDIPC_Data14Value "ODI";
CM_ SG_ 3221225472 ODIEDDIPC_Data13Value "ODI";
CM_ SG_ 3221225472 ODIEDDIPC_Data12Value "ODI";
CM_ SG_ 2150785024 AirbgAccelOrien "Orientation of first accelerometer axis.  0 degrees is right side of vehicle, 90 degrees is front of vehicle.  Second axis given by adding 90 degrees to first axis.";
CM_ SG_ 2158886912 ODDLI_SubIdReqM "ODI-The number of list entries, starting at the Index, to send";
CM_ SG_ 2158886912 ODDLI_WrpArnd "ODI-Boolean that shall be set to true if the list shall wrap around.";
CM_ SG_ 2158886912 ODDLI_ReqType "ODI - Type of Request";
CM_ SG_ 2158886912 ODDLI_ReqDir "ODI-Boolean that shall be set to true if req down, set to false if set to up";
CM_ SG_ 2158886912 ODDLI_NmEntries "ODI-The number of list entries, starting at the Index, to send";
CM_ SG_ 2158886912 ODDLI_Idx "ODI-The index within the remote FU’s list at which to start sending data";
CM_ SG_ 2158886912 ODDLI_FUCID "ODI - Primary ID of Functional Unit in FU Database";
CM_ SG_ 2158886912 ODDLI_DspMID "ODI - ID that identifies the display requesting the data.  See detailed requirements in ODI GMLAN Protocol.";
CM_ SG_ 2158886912 ODDLI_DataId "ODI-Data Id for the dynamic list";
CM_ SG_ 2158886912 ODDLI_BckgndFlag "ODI-Informs FU as to priority of response.
Applies to all DataIds in the message.
$0=Immediate response required
$1=Background response";
CM_ SG_ 2159132672 ODIAR_FUCID "ODI - Primary ID of Functional Unit in FU Database";
CM_ SG_ 2159132672 ODIAR_DspMID "ODI - ID that identifies the display requesting the data.  See detailed requirements in ODI GMLAN Protocol.";
CM_ SG_ 2159132672 ODIAR_ActnVal "ODI-Integer value for Actions with values.
FUDatabase definition of Action includes ActionDataType that defines whether or not Action has a value. 
For Actions without a value, this field is always sent as 0.";
CM_ SG_ 2159132672 ODIAR_ActnID "ODI-ActionId within the FUClass";
BA_DEF_ SG_  "VNSigDiagnostic" ENUM  "No","Yes","DLCLS","DLCHS","DLCCE","DLCFO";
BA_DEF_ SG_  "VNSigUnused_4" ENUM  "No","Yes","DLCLS","DLCHS","DLCCE","DLCFO";
BA_DEF_ SG_  "VNSigIntermediate" ENUM  "No","Yes","DLCLS","DLCHS","DLCCE","DLCFO";
BA_DEF_ SG_  "VNSigParkedVehicle" ENUM  "No","Yes","DLCLS","DLCHS","DLCCE","DLCFO";
BA_DEF_ SG_  "VNSigRemoteDiagnostics" ENUM  "No","Yes","DLCLS","DLCHS","DLCCE","DLCFO";
BA_DEF_ SG_  "GenSigSendOnInit" ENUM  "Not Initialized","Application","Handler","DLCLS","DLCHS","DLCCE","DLCFO";
BA_DEF_ SG_  "GenSigSendType" ENUM  "not used","not used","not used","not used","not used","not used","not used","NoSigSendType","not used","not used","OnAnyChange","OnChangeIfActive","OnDelta","DLCLS","DLCHS","DLCCE","DLCFO";
BA_DEF_ SG_  "GenSigInactiveValue" INT 0 0;
BA_DEF_ SG_  "GenSigDeltaValue" INT 0 0;
BA_DEF_ SG_  "VNSigAllNodes" ENUM  "No","Yes","DLCLS","DLCHS","DLCCE","DLCFO";
BA_DEF_ SG_  "SignalType" STRING ;
BA_DEF_ SG_  "PacketOrder" INT 0 65535;
BA_DEF_ SG_  "SignalLongName" STRING ;
BA_DEF_ SG_  "GenSigStartValue" INT 0 65535;
BA_DEF_ SG_  "TxSignalSendOnInit" ENUM  "Not Initialized","Application","Handler";
BA_DEF_ BO_  "GenMsgILSupport" ENUM  "No","Yes","DLCLS","DLCHS","DLCCE","DLCFO";
BA_DEF_ BO_  "TpApplType" STRING ;
BA_DEF_ BO_  "Prio" INT 0 7;
BA_DEF_ BO_  "MessageSubnet" ENUM  "LS","MS","HS","CE","PE","HV","FO","S1","HE","LE","HE2","DLCLS","DLCHS","DLCCE","DLCFO","vector_leerstring";
BA_DEF_ BO_  "DiagState" ENUM  "No","Yes";
BA_DEF_ BO_  "GenMsgIlSupport" ENUM  "No","Yes";
BA_DEF_ BO_  "GenMsgStartDelayTime" INT 0 100000;
BA_DEF_ BO_  "GenMsgDelayTime" INT 0 100000;
BA_DEF_ BO_  "GenMsgCycleTime" INT 0 100000;
BA_DEF_ BO_  "GenMsgSendType" ENUM  "cyclicX","spontanX","cyclicIfActiveX","spontanWithDelay","cyclicAndSpontanX","cyclicAndSpontanWithDelay","spontanWithRepitition","cyclicIfActiveAndSpontanWD";
BA_DEF_ BO_  "DiagResponse" ENUM  "No","Yes";
BA_DEF_ BO_  "DiagRequest" ENUM  "No","Yes";
BA_DEF_ BO_  "NmMessage" ENUM  "No","Yes";
BA_DEF_ BU_  "MessageManagerUsed" ENUM  "No","Yes","DLCLS","DLCHS","DLCCE","DLCFO";
BA_DEF_ BU_  "NmNode" ENUM  "No","Yes";
BA_DEF_ BU_  "ILUsed" ENUM  "No","Yes";
BA_DEF_ BU_  "FillCharacter" HEX 0 255;
BA_DEF_ BU_  "FlashSegmentSize" INT 0 256;
BA_DEF_ BU_  "NodeLayerModules" STRING ;
BA_DEF_ BU_  "VNECURemoteDiagnostics" ENUM  "None","Activator","Remoted","Activator and Remoted","Shared Local","DLCLS","DLCHS","DLCCE","DLCFO";
BA_DEF_ BU_  "VNECUParkedVehicle" ENUM  "None","Activator","Remoted","Activator and Remoted","Shared Local","DLCLS","DLCHS","DLCCE","DLCFO";
BA_DEF_ BU_  "VNECUIntermediate" ENUM  "None","Activator","Remoted","Activator and Remoted","Shared Local","DLCLS","DLCHS","DLCCE","DLCFO";
BA_DEF_ BU_  "VNECUDiagnostic" ENUM  "None","Activator","Remoted","Activator and Remoted","Shared Local","DLCLS","DLCHS","DLCCE","DLCFO";
BA_DEF_ BU_  "VNECUAllNodes" ENUM  "None","Activator","Remoted","Activator and Remoted","Shared Local","DLCLS","DLCHS","DLCCE","DLCFO";
BA_DEF_ BU_  "VNECUPrimaryTriggering" ENUM  "None","Activated","Remoted","Activator and Remoted","Shared Local";
BA_DEF_ BU_  "VNECUInfotainment" ENUM  "None","Activator","Remoted","Activator and Remoted","Shared Local";
BA_DEF_ BU_  "ECU_Id" HEX 0 255;
BA_DEF_ BU_  "SourceId" HEX 0 253;
BA_DEF_  "VN_Diagnostic" INT 0 255;
BA_DEF_  "VN_Unused_4" INT 0 255;
BA_DEF_  "VN_Intermediate" INT 0 255;
BA_DEF_  "VN_ParkedVehicle" INT 0 255;
BA_DEF_  "VN_RemoteDiagnostics" INT 0 255;
BA_DEF_  "VN_AllNodes" INT 0 255;
BA_DEF_  "VNInitActDiagnostic" ENUM  "No","Yes","DLCLS","DLCHS","DLCCE","DLCFO";
BA_DEF_  "VNInitActPrimaryTriggering" ENUM  "No","Yes","DLCLS","DLCHS","DLCCE","DLCFO";
BA_DEF_  "VehicleArchitecture" STRING ;
BA_DEF_  "Baudrate" INT 0 1000000;
BA_DEF_  "SamplePointMin" FLOAT 0 100;
BA_DEF_  "SamplePointMax" FLOAT 0 100;
BA_DEF_  "SyncJumpWidthMin" INT 0 255;
BA_DEF_  "SyncJumpWidthMax" INT 0 255;
BA_DEF_  "VersionMonth" INT 0 255;
BA_DEF_  "BusType" STRING ;
BA_DEF_  "NmMessageCount" INT 0 32;
BA_DEF_  "NmBaseAddress" HEX 0 2032;
BA_DEF_  "NetworkType" STRING ;
BA_DEF_  "VNMFPeriodicInterval" INT 0 65535;
BA_DEF_  "BusWakeUpDelay" INT 0 65535;
BA_DEF_  "BusOffRecoveryTime" INT 0 65535;
BA_DEF_  "VN_PrimaryTriggering" INT 0 56;
BA_DEF_  "VN_Infotainment" INT 0 56;
BA_DEF_  "NodeStatusMsgID" HEX 0 536870911;
BA_DEF_  "NodeStatusMsgCycleTime" INT 0 65535;
BA_DEF_  "NodeStatusMsgTimeoutTime" INT 0 65535;
BA_DEF_  "UseGMParameterIDs" INT 0 1;
BA_DEF_  "VersionWeek" INT 0 255;
BA_DEF_  "VersionYear" INT 0 255;
BA_DEF_  "Manufacturer" ENUM  "DBAG","VAG","BMW","PAG","GM";
BA_DEF_  "NmType" STRING ;
BA_DEF_REL_ BU_SG_REL_  "GenSigSuprvResp" ENUM  "None","Notify App","Substitute Default","DLCLS","DLCHS","DLCCE","DLCFO";
BA_DEF_REL_ BU_SG_REL_  "GenSigSuprvRespSubValue" INT 0 65535;
BA_DEF_REL_ BU_SG_REL_  "GenSigRxStartValue" STRING ;
BA_DEF_REL_ BU_SG_REL_  "GenSigVDAFailResp" ENUM  "No","Yes","DLCLS","DLCHS","DLCCE","DLCFO";
BA_DEF_REL_ BU_SG_REL_  "GenSigVDAFailComment" STRING ;
BA_DEF_REL_ BU_SG_REL_  "GenSigVBitRespComment" STRING ;
BA_DEF_REL_ BU_SG_REL_  "GenSigVBitResp" ENUM  "No","Yes","DLCLS","DLCHS","DLCCE","DLCFO";
BA_DEF_REL_ BU_SG_REL_  "GenSigSuprvRespComment" STRING ;
BA_DEF_REL_ BU_SG_REL_  "GenSigTimeoutTime" INT 0 5000;
BA_DEF_DEF_  "VNSigDiagnostic" "No";
BA_DEF_DEF_  "VNSigUnused_4" "No";
BA_DEF_DEF_  "VNSigIntermediate" "No";
BA_DEF_DEF_  "VNSigParkedVehicle" "No";
BA_DEF_DEF_  "VNSigRemoteDiagnostics" "No";
BA_DEF_DEF_  "GenSigSendOnInit" "Not Initialized";
BA_DEF_DEF_  "GenSigSendType" "NoSigSendType";
BA_DEF_DEF_  "GenSigInactiveValue" 0;
BA_DEF_DEF_  "GenSigDeltaValue" 0;
BA_DEF_DEF_  "VNSigAllNodes" "No";
BA_DEF_DEF_  "SignalType" "";
BA_DEF_DEF_  "PacketOrder" 0;
BA_DEF_DEF_  "SignalLongName" "";
BA_DEF_DEF_  "GenSigStartValue" 0;
BA_DEF_DEF_  "TxSignalSendOnInit" "Not Initialized";
BA_DEF_DEF_  "GenMsgILSupport" "Yes";
BA_DEF_DEF_  "TpApplType" "";
BA_DEF_DEF_  "Prio" 0;
BA_DEF_DEF_  "MessageSubnet" "LS";
BA_DEF_DEF_  "DiagState" "No";
BA_DEF_DEF_  "GenMsgIlSupport" "Yes";
BA_DEF_DEF_  "GenMsgStartDelayTime" 0;
BA_DEF_DEF_  "GenMsgDelayTime" 0;
BA_DEF_DEF_  "GenMsgCycleTime" 0;
BA_DEF_DEF_  "GenMsgSendType" "spontanX";
BA_DEF_DEF_  "DiagResponse" "No";
BA_DEF_DEF_  "DiagRequest" "No";
BA_DEF_DEF_  "NmMessage" "No";
BA_DEF_DEF_REL_ "GenSigSuprvResp" "None";
BA_DEF_DEF_REL_ "GenSigSuprvRespSubValue" 0;
BA_DEF_DEF_REL_ "GenSigRxStartValue" "";
BA_DEF_DEF_REL_ "GenSigVDAFailResp" "No";
BA_DEF_DEF_REL_ "GenSigVDAFailComment" "";
BA_DEF_DEF_REL_ "GenSigVBitRespComment" "";
BA_DEF_DEF_REL_ "GenSigVBitResp" "No";
BA_DEF_DEF_REL_ "GenSigSuprvRespComment" "";
BA_DEF_DEF_REL_ "GenSigTimeoutTime" 0;
BA_DEF_DEF_  "MessageManagerUsed" "Yes";
BA_DEF_DEF_  "NmNode" "Yes";
BA_DEF_DEF_  "ILUsed" "Yes";
BA_DEF_DEF_  "FillCharacter" 255;
BA_DEF_DEF_  "FlashSegmentSize" 8;
BA_DEF_DEF_  "NodeLayerModules" "gmlan02.dll";
BA_DEF_DEF_  "VNECURemoteDiagnostics" "None";
BA_DEF_DEF_  "VNECUParkedVehicle" "None";
BA_DEF_DEF_  "VNECUIntermediate" "None";
BA_DEF_DEF_  "VNECUDiagnostic" "None";
BA_DEF_DEF_  "VNECUAllNodes" "None";
BA_DEF_DEF_  "VNECUPrimaryTriggering" "None";
BA_DEF_DEF_  "VNECUInfotainment" "None";
BA_DEF_DEF_  "ECU_Id" 0;
BA_DEF_DEF_  "SourceId" 0;
BA_DEF_DEF_  "VN_Diagnostic" 0;
BA_DEF_DEF_  "VN_Unused_4" 4;
BA_DEF_DEF_  "VN_Intermediate" 3;
BA_DEF_DEF_  "VN_ParkedVehicle" 6;
BA_DEF_DEF_  "VN_RemoteDiagnostics" 5;
BA_DEF_DEF_  "VN_AllNodes" 1;
BA_DEF_DEF_  "VNInitActDiagnostic" "No";
BA_DEF_DEF_  "VNInitActPrimaryTriggering" "No";
BA_DEF_DEF_  "VehicleArchitecture" "";
BA_DEF_DEF_  "Baudrate" 0;
BA_DEF_DEF_  "SamplePointMin" 0;
BA_DEF_DEF_  "SamplePointMax" 0;
BA_DEF_DEF_  "SyncJumpWidthMin" 0;
BA_DEF_DEF_  "SyncJumpWidthMax" 0;
BA_DEF_DEF_  "VersionMonth" 0;
BA_DEF_DEF_  "BusType" "";
BA_DEF_DEF_  "NmMessageCount" 32;
BA_DEF_DEF_  "NmBaseAddress" 1568;
BA_DEF_DEF_  "NetworkType" "";
BA_DEF_DEF_  "VNMFPeriodicInterval" 3000;
BA_DEF_DEF_  "BusWakeUpDelay" 100;
BA_DEF_DEF_  "BusOffRecoveryTime" 0;
BA_DEF_DEF_  "VN_PrimaryTriggering" 7;
BA_DEF_DEF_  "VN_Infotainment" 4;
BA_DEF_DEF_  "NodeStatusMsgID" 268433408;
BA_DEF_DEF_  "NodeStatusMsgCycleTime" 1200;
BA_DEF_DEF_  "NodeStatusMsgTimeoutTime" 3000;
BA_DEF_DEF_  "UseGMParameterIDs" 1;
BA_DEF_DEF_  "VersionWeek" 0;
BA_DEF_DEF_  "VersionYear" 0;
BA_DEF_DEF_  "Manufacturer" "GM";
BA_DEF_DEF_  "NmType" "GMLAN";
BA_ "VNInitActDiagnostic" 1;
BA_ "VNInitActPrimaryTriggering" 1;
BA_ "VehicleArchitecture" "GlobalA";
BA_ "Baudrate" 33333;
BA_ "SamplePointMin" 85;
BA_ "SamplePointMax" 89.48;
BA_ "SyncJumpWidthMin" 2;
BA_ "SyncJumpWidthMax" 3;
BA_ "VersionMonth" 19;
BA_ "BusType" "CAN";
BA_ "NetworkType" "Bodybus";
BA_ "BusWakeUpDelay" 70;
BA_ "BusOffRecoveryTime" 3700;
BA_ "VN_Infotainment" 2;
BA_ "NodeStatusMsgID" 335536128;
BA_ "VersionWeek" 41;
BA_ "VersionYear" 19;
BA_ "VNECUDiagnostic" BU_ SBZA_R_LS 4;
BA_ "VNECUAllNodes" BU_ SBZA_R_LS 2;
BA_ "VNECUPrimaryTriggering" BU_ SBZA_R_LS 2;
BA_ "ECU_Id" BU_ SBZA_R_LS 55;
BA_ "SourceId" BU_ SBZA_R_LS 91;
BA_ "VNECUAllNodes" BU_ SBZA_L_LS 2;
BA_ "VNECUPrimaryTriggering" BU_ SBZA_L_LS 2;
BA_ "VNECUInfotainment" BU_ SBZA_L_LS 4;
BA_ "ECU_Id" BU_ SBZA_L_LS 58;
BA_ "SourceId" BU_ SBZA_L_LS 185;
BA_ "VNECUDiagnostic" BU_ VIS2_LS 4;
BA_ "VNECUAllNodes" BU_ VIS2_LS 2;
BA_ "VNECUPrimaryTriggering" BU_ VIS2_LS 2;
BA_ "ECU_Id" BU_ VIS2_LS 53;
BA_ "SourceId" BU_ VIS2_LS 188;
BA_ "VNECUDiagnostic" BU_ SDM_LS 4;
BA_ "VNECUAllNodes" BU_ SDM_LS 2;
BA_ "VNECUPrimaryTriggering" BU_ SDM_LS 2;
BA_ "ECU_Id" BU_ SDM_LS 39;
BA_ "SourceId" BU_ SDM_LS 88;
BA_ "VNECUIntermediate" BU_ PEPS_LS 2;
BA_ "VNECUDiagnostic" BU_ PEPS_LS 4;
BA_ "VNECUAllNodes" BU_ PEPS_LS 3;
BA_ "VNECUPrimaryTriggering" BU_ PEPS_LS 2;
BA_ "ECU_Id" BU_ PEPS_LS 34;
BA_ "SourceId" BU_ PEPS_LS 175;
BA_ "VNECUDiagnostic" BU_ UPA_LS 4;
BA_ "VNECUAllNodes" BU_ UPA_LS 2;
BA_ "VNECUPrimaryTriggering" BU_ UPA_LS 2;
BA_ "ECU_Id" BU_ UPA_LS 57;
BA_ "SourceId" BU_ UPA_LS 187;
BA_ "VNECUParkedVehicle" BU_ PTM_LS 2;
BA_ "VNECUDiagnostic" BU_ PTM_LS 4;
BA_ "VNECUAllNodes" BU_ PTM_LS 3;
BA_ "VNECUPrimaryTriggering" BU_ PTM_LS 2;
BA_ "ECU_Id" BU_ PTM_LS 47;
BA_ "SourceId" BU_ PTM_LS 164;
BA_ "VNECUDiagnostic" BU_ MSM_LS 4;
BA_ "VNECUAllNodes" BU_ MSM_LS 3;
BA_ "VNECUPrimaryTriggering" BU_ MSM_LS 2;
BA_ "ECU_Id" BU_ MSM_LS 61;
BA_ "SourceId" BU_ MSM_LS 168;
BA_ "VNECUDiagnostic" BU_ HFP_LS 4;
BA_ "VNECUAllNodes" BU_ HFP_LS 2;
BA_ "VNECUPrimaryTriggering" BU_ HFP_LS 2;
BA_ "VNECUInfotainment" BU_ HFP_LS 2;
BA_ "ECU_Id" BU_ HFP_LS 40;
BA_ "SourceId" BU_ HFP_LS 104;
BA_ "VNECUDiagnostic" BU_ EOCM_F_LS 4;
BA_ "VNECUAllNodes" BU_ EOCM_F_LS 2;
BA_ "VNECUPrimaryTriggering" BU_ EOCM_F_LS 2;
BA_ "ECU_Id" BU_ EOCM_F_LS 43;
BA_ "SourceId" BU_ EOCM_F_LS 108;
BA_ "VNECUIntermediate" BU_ ECC_LS 2;
BA_ "VNECUDiagnostic" BU_ ECC_LS 4;
BA_ "VNECUAllNodes" BU_ ECC_LS 3;
BA_ "VNECUPrimaryTriggering" BU_ ECC_LS 2;
BA_ "ECU_Id" BU_ ECC_LS 49;
BA_ "SourceId" BU_ ECC_LS 153;
BA_ "VNECUDiagnostic" BU_ DCAC_LS 4;
BA_ "VNECUAllNodes" BU_ DCAC_LS 2;
BA_ "VNECUPrimaryTriggering" BU_ DCAC_LS 2;
BA_ "ECU_Id" BU_ DCAC_LS 35;
BA_ "SourceId" BU_ DCAC_LS 207;
BA_ "VNECURemoteDiagnostics" BU_ CGM_LS 2;
BA_ "VNECUParkedVehicle" BU_ CGM_LS 2;
BA_ "VNECUIntermediate" BU_ CGM_LS 2;
BA_ "VNECUDiagnostic" BU_ CGM_LS 4;
BA_ "VNECUAllNodes" BU_ CGM_LS 2;
BA_ "VNECUPrimaryTriggering" BU_ CGM_LS 2;
BA_ "VNECUInfotainment" BU_ CGM_LS 2;
BA_ "ECU_Id" BU_ CGM_LS 51;
BA_ "SourceId" BU_ CGM_LS 71;
BA_ "VNECUDiagnostic" BU_ BSM_LS 4;
BA_ "VNECUAllNodes" BU_ BSM_LS 3;
BA_ "VNECUPrimaryTriggering" BU_ BSM_LS 2;
BA_ "VNECUInfotainment" BU_ BSM_LS 2;
BA_ "ECU_Id" BU_ BSM_LS 228;
BA_ "SourceId" BU_ BSM_LS 203;
BA_ "VNECURemoteDiagnostics" BU_ BCM_LS 2;
BA_ "VNECUParkedVehicle" BU_ BCM_LS 3;
BA_ "VNECUIntermediate" BU_ BCM_LS 3;
BA_ "VNECUDiagnostic" BU_ BCM_LS 4;
BA_ "VNECUAllNodes" BU_ BCM_LS 3;
BA_ "VNECUPrimaryTriggering" BU_ BCM_LS 2;
BA_ "VNECUInfotainment" BU_ BCM_LS 2;
BA_ "ECU_Id" BU_ BCM_LS 33;
BA_ "SourceId" BU_ BCM_LS 64;
BA_ "VNECUDiagnostic" BU_ AOS_LS 4;
BA_ "VNECUAllNodes" BU_ AOS_LS 2;
BA_ "VNECUPrimaryTriggering" BU_ AOS_LS 2;
BA_ "ECU_Id" BU_ AOS_LS 37;
BA_ "SourceId" BU_ AOS_LS 89;
BA_ "DiagRequest" BO_ 599 1;
BA_ "GenMsgILSupport" BO_ 1367 0;
BA_ "TpApplType" BO_ 1367 "DiagUUDTResponse";
BA_ "DiagResponse" BO_ 1623 1;
BA_ "Prio" BO_ 2155012096 4;
BA_ "GenMsgDelayTime" BO_ 2155012096 100;
BA_ "DiagResponse" BO_ 932 1;
BA_ "DiagResponse" BO_ 936 1;
BA_ "DiagResponse" BO_ 921 1;
BA_ "Prio" BO_ 2151702528 4;
BA_ "GenMsgDelayTime" BO_ 2151702528 100;
BA_ "Prio" BO_ 2155126784 4;
BA_ "GenMsgDelayTime" BO_ 2155126784 100;
BA_ "Prio" BO_ 2155102208 4;
BA_ "GenMsgDelayTime" BO_ 2155102208 100;
BA_ "Prio" BO_ 2155085824 4;
BA_ "GenMsgDelayTime" BO_ 2155085824 100;
BA_ "Prio" BO_ 2155069440 4;
BA_ "GenMsgDelayTime" BO_ 2155069440 100;
BA_ "DiagResponse" BO_ 2034 1;
BA_ "Prio" BO_ 2152857600 4;
BA_ "GenMsgDelayTime" BO_ 2152857600 100;
BA_ "Prio" BO_ 2151489536 4;
BA_ "GenMsgDelayTime" BO_ 2151489536 100;
BA_ "Prio" BO_ 2152759296 4;
BA_ "GenMsgDelayTime" BO_ 2152759296 100;
BA_ "Prio" BO_ 2152742912 4;
BA_ "GenMsgDelayTime" BO_ 2152742912 100;
BA_ "GenMsgCycleTime" BO_ 1591 3000;
BA_ "GenMsgSendType" BO_ 1591 0;
BA_ "NmMessage" BO_ 1591 1;
BA_ "GenMsgILSupport" BO_ 1355 0;
BA_ "TpApplType" BO_ 1355 "DiagUUDTResponse";
BA_ "GenMsgILSupport" BO_ 1611 0;
BA_ "DiagResponse" BO_ 1611 1;
BA_ "DiagResponse" BO_ 1603 1;
BA_ "GenMsgILSupport" BO_ 1347 0;
BA_ "TpApplType" BO_ 1347 "DiagUUDTResponse";
BA_ "Prio" BO_ 2154995712 4;
BA_ "GenMsgDelayTime" BO_ 2154995712 100;
BA_ "Prio" BO_ 2150817792 4;
BA_ "GenMsgDelayTime" BO_ 2150817792 10;
BA_ "DiagResponse" BO_ 1621 1;
BA_ "GenMsgILSupport" BO_ 1365 0;
BA_ "TpApplType" BO_ 1365 "DiagUUDTResponse";
BA_ "Prio" BO_ 2150809600 4;
BA_ "GenMsgDelayTime" BO_ 2150809600 10;
BA_ "Prio" BO_ 2150793216 4;
BA_ "GenMsgDelayTime" BO_ 2150793216 10;
BA_ "Prio" BO_ 2150801408 4;
BA_ "GenMsgDelayTime" BO_ 2150801408 10;
BA_ "Prio" BO_ 2150785024 4;
BA_ "GenMsgDelayTime" BO_ 2150785024 10;
BA_ "Prio" BO_ 2150825984 4;
BA_ "GenMsgDelayTime" BO_ 2150825984 10;
BA_ "GenMsgILSupport" BO_ 1351 0;
BA_ "TpApplType" BO_ 1351 "DiagUUDTResponse";
BA_ "DiagResponse" BO_ 1607 1;
BA_ "DiagResponse" BO_ 1602 1;
BA_ "GenMsgILSupport" BO_ 1346 0;
BA_ "TpApplType" BO_ 1346 "DiagUUDTResponse";
BA_ "GenMsgILSupport" BO_ 1361 0;
BA_ "TpApplType" BO_ 1361 "DiagUUDTResponse";
BA_ "DiagResponse" BO_ 1617 1;
BA_ "GenMsgILSupport" BO_ 1373 0;
BA_ "TpApplType" BO_ 1373 "DiagUUDTResponse";
BA_ "DiagResponse" BO_ 1629 1;
BA_ "DiagRequest" BO_ 602 1;
BA_ "DiagRequest" BO_ 164 1;
BA_ "DiagRequest" BO_ 104 1;
BA_ "DiagRequest" BO_ 88 1;
BA_ "DiagRequest" BO_ 168 1;
BA_ "DiagRequest" BO_ 153 1;
BA_ "Prio" BO_ 2152046592 4;
BA_ "GenMsgDelayTime" BO_ 2152046592 20;
BA_ "DiagRequest" BO_ 2032 1;
BA_ "Prio" BO_ 2150563840 4;
BA_ "GenMsgDelayTime" BO_ 2150563840 100;
BA_ "Prio" BO_ 2151948288 4;
BA_ "GenMsgDelayTime" BO_ 2151948288 100;
BA_ "Prio" BO_ 2156806144 4;
BA_ "GenMsgDelayTime" BO_ 2156806144 500;
BA_ "GenMsgILSupport" BO_ 1350 0;
BA_ "TpApplType" BO_ 1350 "DiagUUDTResponse";
BA_ "Prio" BO_ 2158886912 4;
BA_ "GenMsgDelayTime" BO_ 2158886912 20;
BA_ "DiagRequest" BO_ 579 1;
BA_ "Prio" BO_ 2159132672 4;
BA_ "GenMsgDelayTime" BO_ 2159132672 20;
BA_ "Prio" BO_ 2154692608 4;
BA_ "GenMsgDelayTime" BO_ 2154692608 10;
BA_ "GenMsgCycleTime" BO_ 2154692608 1200;
BA_ "GenMsgSendType" BO_ 2154692608 0;
BA_ "DiagRequest" BO_ 597 1;
BA_ "GenMsgILSupport" BO_ 1357 0;
BA_ "TpApplType" BO_ 1357 "DiagUUDTResponse";
BA_ "DiagResponse" BO_ 1608 1;
BA_ "DiagRequest" BO_ 584 1;
BA_ "GenMsgILSupport" BO_ 1352 0;
BA_ "TpApplType" BO_ 1352 "DiagUUDTResponse";
BA_ "DiagRequest" BO_ 583 1;
BA_ "TpApplType" BO_ 1348 "DiagUUDTResponse";
BA_ "DiagRequest" BO_ 591 1;
BA_ "DiagRequest" BO_ 578 1;
BA_ "GenMsgILSupport" BO_ 1356 0;
BA_ "TpApplType" BO_ 1356 "DiagUUDTResponse";
BA_ "GenMsgILSupport" BO_ 1360 0;
BA_ "TpApplType" BO_ 1360 "DiagUUDTResponse";
BA_ "DiagResponse" BO_ 1616 1;
BA_ "DiagRequest" BO_ 593 1;
BA_ "DiagRequest" BO_ 605 1;
BA_ "GenMsgILSupport" BO_ 587 0;
BA_ "DiagRequest" BO_ 587 1;
BA_ "DiagRequest" BO_ 2020 1;
BA_ "Prio" BO_ 2152054784 4;
BA_ "GenMsgDelayTime" BO_ 2152054784 100;
BA_ "Prio" BO_ 2156281856 4;
BA_ "GenMsgDelayTime" BO_ 2156281856 100;
BA_ "Prio" BO_ 2156265472 4;
BA_ "GenMsgDelayTime" BO_ 2156265472 100;
BA_ "GenSigSendType" SG_ 3221225472 ODIEDDIPC_Data11Value 12;
BA_ "GenSigDeltaValue" SG_ 3221225472 ODIEDDIPC_Data11Value 1;
BA_ "VNSigAllNodes" SG_ 3221225472 ODIEDDIPC_Data11Value 1;
BA_ "SignalType" SG_ 3221225472 ODIEDDIPC_Data11Value "UNM";
BA_ "PacketOrder" SG_ 3221225472 ODIEDDIPC_Data11Value 11;
BA_ "SignalLongName" SG_ 3221225472 ODIEDDIPC_Data11Value "Open Display Interface Enum Dynamic Data : Data ID 11";
BA_ "GenSigSendType" SG_ 3221225472 ODIEDDIPC_Data10Value 12;
BA_ "GenSigDeltaValue" SG_ 3221225472 ODIEDDIPC_Data10Value 1;
BA_ "VNSigAllNodes" SG_ 3221225472 ODIEDDIPC_Data10Value 1;
BA_ "SignalType" SG_ 3221225472 ODIEDDIPC_Data10Value "UNM";
BA_ "PacketOrder" SG_ 3221225472 ODIEDDIPC_Data10Value 10;
BA_ "SignalLongName" SG_ 3221225472 ODIEDDIPC_Data10Value "Open Display Interface Enum Dynamic Data : Data ID 10";
BA_ "GenSigSendType" SG_ 3221225472 ODIEDDIPC_Data9Value 12;
BA_ "GenSigDeltaValue" SG_ 3221225472 ODIEDDIPC_Data9Value 1;
BA_ "VNSigAllNodes" SG_ 3221225472 ODIEDDIPC_Data9Value 1;
BA_ "SignalType" SG_ 3221225472 ODIEDDIPC_Data9Value "UNM";
BA_ "PacketOrder" SG_ 3221225472 ODIEDDIPC_Data9Value 9;
BA_ "SignalLongName" SG_ 3221225472 ODIEDDIPC_Data9Value "Open Display Interface Enum Dynamic Data : Data ID 9";
BA_ "GenSigSendType" SG_ 3221225472 ODIEDDIPC_Data8Value 12;
BA_ "GenSigDeltaValue" SG_ 3221225472 ODIEDDIPC_Data8Value 1;
BA_ "VNSigAllNodes" SG_ 3221225472 ODIEDDIPC_Data8Value 1;
BA_ "SignalType" SG_ 3221225472 ODIEDDIPC_Data8Value "UNM";
BA_ "PacketOrder" SG_ 3221225472 ODIEDDIPC_Data8Value 8;
BA_ "SignalLongName" SG_ 3221225472 ODIEDDIPC_Data8Value "Open Display Interface Enum Dynamic Data : Data ID 8";
BA_ "GenSigSendType" SG_ 3221225472 ODIEDDIPC_Data7Value 12;
BA_ "GenSigDeltaValue" SG_ 3221225472 ODIEDDIPC_Data7Value 1;
BA_ "VNSigAllNodes" SG_ 3221225472 ODIEDDIPC_Data7Value 1;
BA_ "SignalType" SG_ 3221225472 ODIEDDIPC_Data7Value "UNM";
BA_ "PacketOrder" SG_ 3221225472 ODIEDDIPC_Data7Value 7;
BA_ "SignalLongName" SG_ 3221225472 ODIEDDIPC_Data7Value "Open Display Interface Enum Dynamic Data : Data ID 7";
BA_ "GenSigSendType" SG_ 3221225472 ODIEDDIPC_Data6Value 12;
BA_ "GenSigDeltaValue" SG_ 3221225472 ODIEDDIPC_Data6Value 1;
BA_ "VNSigAllNodes" SG_ 3221225472 ODIEDDIPC_Data6Value 1;
BA_ "SignalType" SG_ 3221225472 ODIEDDIPC_Data6Value "UNM";
BA_ "PacketOrder" SG_ 3221225472 ODIEDDIPC_Data6Value 6;
BA_ "SignalLongName" SG_ 3221225472 ODIEDDIPC_Data6Value "Open Display Interface Enum Dynamic Data : Data ID 6";
BA_ "GenSigSendType" SG_ 3221225472 ODIEDDIPC_Data5Value 12;
BA_ "GenSigDeltaValue" SG_ 3221225472 ODIEDDIPC_Data5Value 1;
BA_ "VNSigAllNodes" SG_ 3221225472 ODIEDDIPC_Data5Value 1;
BA_ "SignalType" SG_ 3221225472 ODIEDDIPC_Data5Value "UNM";
BA_ "PacketOrder" SG_ 3221225472 ODIEDDIPC_Data5Value 5;
BA_ "SignalLongName" SG_ 3221225472 ODIEDDIPC_Data5Value "Open Display Interface Enum Dynamic Data : Data ID 5";
BA_ "GenSigSendType" SG_ 3221225472 ODIEDDIPC_Data4Value 12;
BA_ "GenSigDeltaValue" SG_ 3221225472 ODIEDDIPC_Data4Value 1;
BA_ "VNSigAllNodes" SG_ 3221225472 ODIEDDIPC_Data4Value 1;
BA_ "SignalType" SG_ 3221225472 ODIEDDIPC_Data4Value "UNM";
BA_ "PacketOrder" SG_ 3221225472 ODIEDDIPC_Data4Value 4;
BA_ "SignalLongName" SG_ 3221225472 ODIEDDIPC_Data4Value "Open Display Interface Enum Dynamic Data : Data ID 4";
BA_ "GenSigSendType" SG_ 3221225472 ODIEDDIPC_Data3Value 12;
BA_ "GenSigDeltaValue" SG_ 3221225472 ODIEDDIPC_Data3Value 1;
BA_ "VNSigAllNodes" SG_ 3221225472 ODIEDDIPC_Data3Value 1;
BA_ "SignalType" SG_ 3221225472 ODIEDDIPC_Data3Value "UNM";
BA_ "PacketOrder" SG_ 3221225472 ODIEDDIPC_Data3Value 3;
BA_ "SignalLongName" SG_ 3221225472 ODIEDDIPC_Data3Value "Open Display Interface Enum Dynamic Data : Data ID 3";
BA_ "GenSigSendType" SG_ 3221225472 ODIEDDIPC_Data2Value 12;
BA_ "GenSigDeltaValue" SG_ 3221225472 ODIEDDIPC_Data2Value 1;
BA_ "VNSigAllNodes" SG_ 3221225472 ODIEDDIPC_Data2Value 1;
BA_ "SignalType" SG_ 3221225472 ODIEDDIPC_Data2Value "UNM";
BA_ "PacketOrder" SG_ 3221225472 ODIEDDIPC_Data2Value 2;
BA_ "SignalLongName" SG_ 3221225472 ODIEDDIPC_Data2Value "Open Display Interface Enum Dynamic Data : Data ID 2";
BA_ "GenSigSendType" SG_ 3221225472 ODIEDDIPC_Data1Value 12;
BA_ "GenSigDeltaValue" SG_ 3221225472 ODIEDDIPC_Data1Value 1;
BA_ "VNSigAllNodes" SG_ 3221225472 ODIEDDIPC_Data1Value 1;
BA_ "SignalType" SG_ 3221225472 ODIEDDIPC_Data1Value "UNM";
BA_ "PacketOrder" SG_ 3221225472 ODIEDDIPC_Data1Value 1;
BA_ "SignalLongName" SG_ 3221225472 ODIEDDIPC_Data1Value "Open Display Interface Enum Dynamic Data : Data ID 1";
BA_ "GenSigSendOnInit" SG_ 3221225472 ODIEDDCS_FUCID 1;
BA_ "GenSigSendType" SG_ 3221225472 ODIEDDCS_FUCID 12;
BA_ "GenSigDeltaValue" SG_ 3221225472 ODIEDDCS_FUCID 1;
BA_ "VNSigAllNodes" SG_ 3221225472 ODIEDDCS_FUCID 1;
BA_ "SignalType" SG_ 3221225472 ODIEDDCS_FUCID "UNM";
BA_ "PacketOrder" SG_ 3221225472 ODIEDDCS_FUCID 19;
BA_ "SignalLongName" SG_ 3221225472 ODIEDDCS_FUCID "Open Display Interface Enum Dynamic Data : Functional Unit Class ID";
BA_ "GenSigSendOnInit" SG_ 3221225472 ODIEDDCS_Data9Value 1;
BA_ "GenSigSendType" SG_ 3221225472 ODIEDDCS_Data9Value 12;
BA_ "GenSigDeltaValue" SG_ 3221225472 ODIEDDCS_Data9Value 1;
BA_ "VNSigAllNodes" SG_ 3221225472 ODIEDDCS_Data9Value 1;
BA_ "SignalType" SG_ 3221225472 ODIEDDCS_Data9Value "UNM";
BA_ "PacketOrder" SG_ 3221225472 ODIEDDCS_Data9Value 9;
BA_ "SignalLongName" SG_ 3221225472 ODIEDDCS_Data9Value "Open Display Interface Enum Dynamic Data : Data ID 9";
BA_ "GenSigSendOnInit" SG_ 3221225472 ODIEDDCS_Data8Value 1;
BA_ "GenSigSendType" SG_ 3221225472 ODIEDDCS_Data8Value 12;
BA_ "GenSigDeltaValue" SG_ 3221225472 ODIEDDCS_Data8Value 1;
BA_ "VNSigAllNodes" SG_ 3221225472 ODIEDDCS_Data8Value 1;
BA_ "SignalType" SG_ 3221225472 ODIEDDCS_Data8Value "UNM";
BA_ "PacketOrder" SG_ 3221225472 ODIEDDCS_Data8Value 8;
BA_ "SignalLongName" SG_ 3221225472 ODIEDDCS_Data8Value "Open Display Interface Enum Dynamic Data : Data ID 8";
BA_ "GenSigSendOnInit" SG_ 3221225472 ODIEDDCS_Data7Value 1;
BA_ "GenSigSendType" SG_ 3221225472 ODIEDDCS_Data7Value 12;
BA_ "GenSigDeltaValue" SG_ 3221225472 ODIEDDCS_Data7Value 1;
BA_ "VNSigAllNodes" SG_ 3221225472 ODIEDDCS_Data7Value 1;
BA_ "SignalType" SG_ 3221225472 ODIEDDCS_Data7Value "UNM";
BA_ "PacketOrder" SG_ 3221225472 ODIEDDCS_Data7Value 7;
BA_ "SignalLongName" SG_ 3221225472 ODIEDDCS_Data7Value "Open Display Interface Enum Dynamic Data : Data ID 7";
BA_ "GenSigSendOnInit" SG_ 3221225472 ODIEDDCS_Data6Value 1;
BA_ "GenSigSendType" SG_ 3221225472 ODIEDDCS_Data6Value 12;
BA_ "GenSigDeltaValue" SG_ 3221225472 ODIEDDCS_Data6Value 1;
BA_ "VNSigAllNodes" SG_ 3221225472 ODIEDDCS_Data6Value 1;
BA_ "SignalType" SG_ 3221225472 ODIEDDCS_Data6Value "UNM";
BA_ "PacketOrder" SG_ 3221225472 ODIEDDCS_Data6Value 6;
BA_ "SignalLongName" SG_ 3221225472 ODIEDDCS_Data6Value "Open Display Interface Enum Dynamic Data : Data ID 6";
BA_ "GenSigSendOnInit" SG_ 3221225472 ODIEDDCS_Data5Value 1;
BA_ "GenSigSendType" SG_ 3221225472 ODIEDDCS_Data5Value 12;
BA_ "GenSigDeltaValue" SG_ 3221225472 ODIEDDCS_Data5Value 1;
BA_ "VNSigAllNodes" SG_ 3221225472 ODIEDDCS_Data5Value 1;
BA_ "SignalType" SG_ 3221225472 ODIEDDCS_Data5Value "UNM";
BA_ "PacketOrder" SG_ 3221225472 ODIEDDCS_Data5Value 5;
BA_ "SignalLongName" SG_ 3221225472 ODIEDDCS_Data5Value "Open Display Interface Enum Dynamic Data : Data ID 5";
BA_ "GenSigSendOnInit" SG_ 3221225472 ODIEDDCS_Data4Value 1;
BA_ "GenSigSendType" SG_ 3221225472 ODIEDDCS_Data4Value 12;
BA_ "GenSigDeltaValue" SG_ 3221225472 ODIEDDCS_Data4Value 1;
BA_ "VNSigAllNodes" SG_ 3221225472 ODIEDDCS_Data4Value 1;
BA_ "SignalType" SG_ 3221225472 ODIEDDCS_Data4Value "UNM";
BA_ "PacketOrder" SG_ 3221225472 ODIEDDCS_Data4Value 4;
BA_ "SignalLongName" SG_ 3221225472 ODIEDDCS_Data4Value "Open Display Interface Enum Dynamic Data : Data ID 4";
BA_ "GenSigSendOnInit" SG_ 3221225472 ODIEDDCS_Data3Value 1;
BA_ "GenSigSendType" SG_ 3221225472 ODIEDDCS_Data3Value 12;
BA_ "GenSigDeltaValue" SG_ 3221225472 ODIEDDCS_Data3Value 1;
BA_ "VNSigAllNodes" SG_ 3221225472 ODIEDDCS_Data3Value 1;
BA_ "SignalType" SG_ 3221225472 ODIEDDCS_Data3Value "UNM";
BA_ "PacketOrder" SG_ 3221225472 ODIEDDCS_Data3Value 3;
BA_ "SignalLongName" SG_ 3221225472 ODIEDDCS_Data3Value "Open Display Interface Enum Dynamic Data : Data ID 3";
BA_ "GenSigSendOnInit" SG_ 3221225472 ODIEDDCS_Data2Value 1;
BA_ "GenSigSendType" SG_ 3221225472 ODIEDDCS_Data2Value 12;
BA_ "GenSigDeltaValue" SG_ 3221225472 ODIEDDCS_Data2Value 1;
BA_ "VNSigAllNodes" SG_ 3221225472 ODIEDDCS_Data2Value 1;
BA_ "SignalType" SG_ 3221225472 ODIEDDCS_Data2Value "UNM";
BA_ "PacketOrder" SG_ 3221225472 ODIEDDCS_Data2Value 2;
BA_ "SignalLongName" SG_ 3221225472 ODIEDDCS_Data2Value "Open Display Interface Enum Dynamic Data : Data ID 2";
BA_ "GenSigSendOnInit" SG_ 3221225472 ODIEDDCS_Data18Value 1;
BA_ "GenSigSendType" SG_ 3221225472 ODIEDDCS_Data18Value 12;
BA_ "GenSigDeltaValue" SG_ 3221225472 ODIEDDCS_Data18Value 1;
BA_ "VNSigAllNodes" SG_ 3221225472 ODIEDDCS_Data18Value 1;
BA_ "SignalType" SG_ 3221225472 ODIEDDCS_Data18Value "UNM";
BA_ "PacketOrder" SG_ 3221225472 ODIEDDCS_Data18Value 18;
BA_ "SignalLongName" SG_ 3221225472 ODIEDDCS_Data18Value "Open Display Interface Enum Dynamic Data : Data ID 18";
BA_ "GenSigSendOnInit" SG_ 3221225472 ODIEDDCS_Data17Value 1;
BA_ "GenSigSendType" SG_ 3221225472 ODIEDDCS_Data17Value 12;
BA_ "GenSigDeltaValue" SG_ 3221225472 ODIEDDCS_Data17Value 1;
BA_ "VNSigAllNodes" SG_ 3221225472 ODIEDDCS_Data17Value 1;
BA_ "SignalType" SG_ 3221225472 ODIEDDCS_Data17Value "UNM";
BA_ "PacketOrder" SG_ 3221225472 ODIEDDCS_Data17Value 17;
BA_ "SignalLongName" SG_ 3221225472 ODIEDDCS_Data17Value "Open Display Interface Enum Dynamic Data : Data ID 17";
BA_ "GenSigSendOnInit" SG_ 3221225472 ODIEDDCS_Data16Value 1;
BA_ "GenSigSendType" SG_ 3221225472 ODIEDDCS_Data16Value 12;
BA_ "GenSigDeltaValue" SG_ 3221225472 ODIEDDCS_Data16Value 1;
BA_ "VNSigAllNodes" SG_ 3221225472 ODIEDDCS_Data16Value 1;
BA_ "SignalType" SG_ 3221225472 ODIEDDCS_Data16Value "UNM";
BA_ "PacketOrder" SG_ 3221225472 ODIEDDCS_Data16Value 16;
BA_ "SignalLongName" SG_ 3221225472 ODIEDDCS_Data16Value "Open Display Interface Enum Dynamic Data : Data ID 16";
BA_ "GenSigSendOnInit" SG_ 3221225472 ODIEDDCS_Data15Value 1;
BA_ "GenSigSendType" SG_ 3221225472 ODIEDDCS_Data15Value 12;
BA_ "GenSigDeltaValue" SG_ 3221225472 ODIEDDCS_Data15Value 1;
BA_ "VNSigAllNodes" SG_ 3221225472 ODIEDDCS_Data15Value 1;
BA_ "SignalType" SG_ 3221225472 ODIEDDCS_Data15Value "UNM";
BA_ "PacketOrder" SG_ 3221225472 ODIEDDCS_Data15Value 15;
BA_ "SignalLongName" SG_ 3221225472 ODIEDDCS_Data15Value "Open Display Interface Enum Dynamic Data : Data ID 15";
BA_ "GenSigSendOnInit" SG_ 3221225472 ODIEDDCS_Data14Value 1;
BA_ "GenSigSendType" SG_ 3221225472 ODIEDDCS_Data14Value 12;
BA_ "GenSigDeltaValue" SG_ 3221225472 ODIEDDCS_Data14Value 1;
BA_ "VNSigAllNodes" SG_ 3221225472 ODIEDDCS_Data14Value 1;
BA_ "SignalType" SG_ 3221225472 ODIEDDCS_Data14Value "UNM";
BA_ "PacketOrder" SG_ 3221225472 ODIEDDCS_Data14Value 14;
BA_ "SignalLongName" SG_ 3221225472 ODIEDDCS_Data14Value "Open Display Interface Enum Dynamic Data : Data ID 14";
BA_ "GenSigSendOnInit" SG_ 3221225472 ODIEDDCS_Data13Value 1;
BA_ "GenSigSendType" SG_ 3221225472 ODIEDDCS_Data13Value 12;
BA_ "GenSigDeltaValue" SG_ 3221225472 ODIEDDCS_Data13Value 1;
BA_ "VNSigAllNodes" SG_ 3221225472 ODIEDDCS_Data13Value 1;
BA_ "SignalType" SG_ 3221225472 ODIEDDCS_Data13Value "UNM";
BA_ "PacketOrder" SG_ 3221225472 ODIEDDCS_Data13Value 13;
BA_ "SignalLongName" SG_ 3221225472 ODIEDDCS_Data13Value "Open Display Interface Enum Dynamic Data : Data ID 13";
BA_ "GenSigSendOnInit" SG_ 3221225472 ODIEDDCS_Data12Value 1;
BA_ "GenSigSendType" SG_ 3221225472 ODIEDDCS_Data12Value 12;
BA_ "GenSigDeltaValue" SG_ 3221225472 ODIEDDCS_Data12Value 1;
BA_ "VNSigAllNodes" SG_ 3221225472 ODIEDDCS_Data12Value 1;
BA_ "SignalType" SG_ 3221225472 ODIEDDCS_Data12Value "UNM";
BA_ "PacketOrder" SG_ 3221225472 ODIEDDCS_Data12Value 12;
BA_ "SignalLongName" SG_ 3221225472 ODIEDDCS_Data12Value "Open Display Interface Enum Dynamic Data : Data ID 12";
BA_ "GenSigSendOnInit" SG_ 3221225472 ODIEDDCS_Data11Value 1;
BA_ "GenSigSendType" SG_ 3221225472 ODIEDDCS_Data11Value 12;
BA_ "GenSigDeltaValue" SG_ 3221225472 ODIEDDCS_Data11Value 1;
BA_ "VNSigAllNodes" SG_ 3221225472 ODIEDDCS_Data11Value 1;
BA_ "SignalType" SG_ 3221225472 ODIEDDCS_Data11Value "UNM";
BA_ "PacketOrder" SG_ 3221225472 ODIEDDCS_Data11Value 11;
BA_ "SignalLongName" SG_ 3221225472 ODIEDDCS_Data11Value "Open Display Interface Enum Dynamic Data : Data ID 11";
BA_ "GenSigSendOnInit" SG_ 3221225472 ODIEDDCS_Data10Value 1;
BA_ "GenSigSendType" SG_ 3221225472 ODIEDDCS_Data10Value 12;
BA_ "GenSigDeltaValue" SG_ 3221225472 ODIEDDCS_Data10Value 1;
BA_ "VNSigAllNodes" SG_ 3221225472 ODIEDDCS_Data10Value 1;
BA_ "SignalType" SG_ 3221225472 ODIEDDCS_Data10Value "UNM";
BA_ "PacketOrder" SG_ 3221225472 ODIEDDCS_Data10Value 10;
BA_ "SignalLongName" SG_ 3221225472 ODIEDDCS_Data10Value "Open Display Interface Enum Dynamic Data : Data ID 10";
BA_ "GenSigSendOnInit" SG_ 3221225472 ODIEDDCS_Data1Value 1;
BA_ "GenSigSendType" SG_ 3221225472 ODIEDDCS_Data1Value 12;
BA_ "GenSigDeltaValue" SG_ 3221225472 ODIEDDCS_Data1Value 1;
BA_ "VNSigAllNodes" SG_ 3221225472 ODIEDDCS_Data1Value 1;
BA_ "SignalType" SG_ 3221225472 ODIEDDCS_Data1Value "UNM";
BA_ "PacketOrder" SG_ 3221225472 ODIEDDCS_Data1Value 1;
BA_ "SignalLongName" SG_ 3221225472 ODIEDDCS_Data1Value "Open Display Interface Enum Dynamic Data : Data ID 1";
BA_ "GenSigSendType" SG_ 3221225472 ODIEDDIPC_FUCID 12;
BA_ "GenSigDeltaValue" SG_ 3221225472 ODIEDDIPC_FUCID 1;
BA_ "VNSigAllNodes" SG_ 3221225472 ODIEDDIPC_FUCID 1;
BA_ "SignalType" SG_ 3221225472 ODIEDDIPC_FUCID "UNM";
BA_ "PacketOrder" SG_ 3221225472 ODIEDDIPC_FUCID 19;
BA_ "SignalLongName" SG_ 3221225472 ODIEDDIPC_FUCID "Open Display Interface Enum Dynamic Data : Functional Unit Class ID";
BA_ "GenSigSendType" SG_ 3221225472 ODIEDDIPC_Data18Value 12;
BA_ "GenSigDeltaValue" SG_ 3221225472 ODIEDDIPC_Data18Value 1;
BA_ "VNSigAllNodes" SG_ 3221225472 ODIEDDIPC_Data18Value 1;
BA_ "SignalType" SG_ 3221225472 ODIEDDIPC_Data18Value "UNM";
BA_ "PacketOrder" SG_ 3221225472 ODIEDDIPC_Data18Value 18;
BA_ "SignalLongName" SG_ 3221225472 ODIEDDIPC_Data18Value "Open Display Interface Enum Dynamic Data : Data ID 18";
BA_ "GenSigSendType" SG_ 3221225472 ODIEDDIPC_Data17Value 12;
BA_ "GenSigDeltaValue" SG_ 3221225472 ODIEDDIPC_Data17Value 1;
BA_ "VNSigAllNodes" SG_ 3221225472 ODIEDDIPC_Data17Value 1;
BA_ "SignalType" SG_ 3221225472 ODIEDDIPC_Data17Value "UNM";
BA_ "PacketOrder" SG_ 3221225472 ODIEDDIPC_Data17Value 17;
BA_ "SignalLongName" SG_ 3221225472 ODIEDDIPC_Data17Value "Open Display Interface Enum Dynamic Data : Data ID 17";
BA_ "GenSigSendType" SG_ 3221225472 ODIEDDIPC_Data16Value 12;
BA_ "GenSigDeltaValue" SG_ 3221225472 ODIEDDIPC_Data16Value 1;
BA_ "VNSigAllNodes" SG_ 3221225472 ODIEDDIPC_Data16Value 1;
BA_ "SignalType" SG_ 3221225472 ODIEDDIPC_Data16Value "UNM";
BA_ "PacketOrder" SG_ 3221225472 ODIEDDIPC_Data16Value 16;
BA_ "SignalLongName" SG_ 3221225472 ODIEDDIPC_Data16Value "Open Display Interface Enum Dynamic Data : Data ID 16";
BA_ "GenSigSendType" SG_ 3221225472 ODIEDDIPC_Data15Value 12;
BA_ "GenSigDeltaValue" SG_ 3221225472 ODIEDDIPC_Data15Value 1;
BA_ "VNSigAllNodes" SG_ 3221225472 ODIEDDIPC_Data15Value 1;
BA_ "SignalType" SG_ 3221225472 ODIEDDIPC_Data15Value "UNM";
BA_ "PacketOrder" SG_ 3221225472 ODIEDDIPC_Data15Value 15;
BA_ "SignalLongName" SG_ 3221225472 ODIEDDIPC_Data15Value "Open Display Interface Enum Dynamic Data : Data ID 15";
BA_ "GenSigSendType" SG_ 3221225472 ODIEDDIPC_Data14Value 12;
BA_ "GenSigDeltaValue" SG_ 3221225472 ODIEDDIPC_Data14Value 1;
BA_ "VNSigAllNodes" SG_ 3221225472 ODIEDDIPC_Data14Value 1;
BA_ "SignalType" SG_ 3221225472 ODIEDDIPC_Data14Value "UNM";
BA_ "PacketOrder" SG_ 3221225472 ODIEDDIPC_Data14Value 14;
BA_ "SignalLongName" SG_ 3221225472 ODIEDDIPC_Data14Value "Open Display Interface Enum Dynamic Data : Data ID 14";
BA_ "GenSigSendType" SG_ 3221225472 ODIEDDIPC_Data13Value 12;
BA_ "GenSigDeltaValue" SG_ 3221225472 ODIEDDIPC_Data13Value 1;
BA_ "VNSigAllNodes" SG_ 3221225472 ODIEDDIPC_Data13Value 1;
BA_ "SignalType" SG_ 3221225472 ODIEDDIPC_Data13Value "UNM";
BA_ "PacketOrder" SG_ 3221225472 ODIEDDIPC_Data13Value 13;
BA_ "SignalLongName" SG_ 3221225472 ODIEDDIPC_Data13Value "Open Display Interface Enum Dynamic Data : Data ID 13";
BA_ "GenSigSendType" SG_ 3221225472 ODIEDDIPC_Data12Value 12;
BA_ "GenSigDeltaValue" SG_ 3221225472 ODIEDDIPC_Data12Value 1;
BA_ "VNSigAllNodes" SG_ 3221225472 ODIEDDIPC_Data12Value 1;
BA_ "SignalType" SG_ 3221225472 ODIEDDIPC_Data12Value "UNM";
BA_ "PacketOrder" SG_ 3221225472 ODIEDDIPC_Data12Value 12;
BA_ "SignalLongName" SG_ 3221225472 ODIEDDIPC_Data12Value "Open Display Interface Enum Dynamic Data : Data ID 12";
BA_ "VNSigAllNodes" SG_ 3221225472 DrThrtlOvrrdDetProtVal 1;
BA_ "SignalType" SG_ 3221225472 DrThrtlOvrrdDetProtVal "UNM";
BA_ "SignalLongName" SG_ 3221225472 DrThrtlOvrrdDetProtVal "Driver Throttle Override Detected Protection Value";
BA_ "VNSigAllNodes" SG_ 3221225472 IMUProtLonAccM 1;
BA_ "SignalType" SG_ 3221225472 IMUProtLonAccM "ENM";
BA_ "SignalLongName" SG_ 3221225472 IMUProtLonAccM "Inertial Measurement Unit Protected Longitudinal Acceleration Mask";
BA_ "VNSigAllNodes" SG_ 3221225472 ARSActAngl 1;
BA_ "SignalType" SG_ 3221225472 ARSActAngl "SNM";
BA_ "SignalLongName" SG_ 3221225472 ARSActAngl "Active Rear Steer Actual Angle";
BA_ "VNSigAllNodes" SG_ 3221225472 BPDAPS_BkPDrvApPV 1;
BA_ "SignalType" SG_ 3221225472 BPDAPS_BkPDrvApPV "ENM";
BA_ "PacketOrder" SG_ 3221225472 BPDAPS_BkPDrvApPV 2;
BA_ "SignalLongName" SG_ 3221225472 BPDAPS_BkPDrvApPV "Brake Pedal Driver Applied Pressure Status : Brake Pedal Driver Applied Pressure Validity";
BA_ "VNSigAllNodes" SG_ 3221225472 BPDAPS_BkPDrvApP 1;
BA_ "SignalType" SG_ 3221225472 BPDAPS_BkPDrvApP "UNM";
BA_ "PacketOrder" SG_ 3221225472 BPDAPS_BkPDrvApP 1;
BA_ "SignalLongName" SG_ 3221225472 BPDAPS_BkPDrvApP "Brake Pedal Driver Applied Pressure Status : Brake Pedal Driver Applied Pressure";
BA_ "VNSigAllNodes" SG_ 3221225472 DrvThrottlOvrrdDet 1;
BA_ "SignalType" SG_ 3221225472 DrvThrottlOvrrdDet "BLN";
BA_ "SignalLongName" SG_ 3221225472 DrvThrottlOvrrdDet "Driver Throttle Override Detected";
BA_ "VNSigAllNodes" SG_ 3221225472 OvrdrvDsblReqd 1;
BA_ "SignalType" SG_ 3221225472 OvrdrvDsblReqd "BLN";
BA_ "SignalLongName" SG_ 3221225472 OvrdrvDsblReqd "Overdrive Disable Requested";
BA_ "VNSigDiagnostic" SG_ 599 DgnInf 1;
BA_ "GenSigSendType" SG_ 599 DgnInf 12;
BA_ "GenSigDeltaValue" SG_ 599 DgnInf 1;
BA_ "VNSigAllNodes" SG_ 599 DgnInf 1;
BA_ "SignalType" SG_ 599 DgnInf "UNM";
BA_ "SignalLongName" SG_ 599 DgnInf "Diagnostic Information";
BA_ "VNSigDiagnostic" SG_ 1367 DgnInf_LS557 1;
BA_ "VNSigAllNodes" SG_ 1367 DgnInf_LS557 1;
BA_ "SignalType" SG_ 1367 DgnInf_LS557 "UNM";
BA_ "SignalLongName" SG_ 1367 DgnInf_LS557 "Diagnostic Information LS557";
BA_ "VNSigDiagnostic" SG_ 1623 DgnInf 1;
BA_ "GenSigSendType" SG_ 1623 DgnInf 12;
BA_ "GenSigDeltaValue" SG_ 1623 DgnInf 1;
BA_ "VNSigAllNodes" SG_ 1623 DgnInf 1;
BA_ "SignalType" SG_ 1623 DgnInf "UNM";
BA_ "SignalLongName" SG_ 1623 DgnInf "Diagnostic Information";
BA_ "GenSigSendType" SG_ 2155012096 SODTmpUnavlbleIO 10;
BA_ "VNSigAllNodes" SG_ 2155012096 SODTmpUnavlbleIO 1;
BA_ "SignalType" SG_ 2155012096 SODTmpUnavlbleIO "BLN";
BA_ "SignalLongName" SG_ 2155012096 SODTmpUnavlbleIO "Side Obstacle Detection Temporarily Unavailable Indication On";
BA_ "GenSigSendType" SG_ 2155012096 SODSnsClnRqdIO 10;
BA_ "VNSigAllNodes" SG_ 2155012096 SODSnsClnRqdIO 1;
BA_ "SignalType" SG_ 2155012096 SODSnsClnRqdIO "BLN";
BA_ "SignalLongName" SG_ 2155012096 SODSnsClnRqdIO "Side Obstacle Detection Sensor Cleaning Required Indication On";
BA_ "GenSigSendType" SG_ 2155012096 SODRIC_Ind3 11;
BA_ "GenSigInactiveValue" SG_ 2155012096 SODRIC_Ind3 1;
BA_ "VNSigAllNodes" SG_ 2155012096 SODRIC_Ind3 1;
BA_ "SignalType" SG_ 2155012096 SODRIC_Ind3 "BLN";
BA_ "PacketOrder" SG_ 2155012096 SODRIC_Ind3 4;
BA_ "SignalLongName" SG_ 2155012096 SODRIC_Ind3 "Side Obstacle Detection Right Indication Control : Indicator 3";
BA_ "GenSigSendType" SG_ 2155012096 SODRIC_Ind2 10;
BA_ "VNSigAllNodes" SG_ 2155012096 SODRIC_Ind2 1;
BA_ "SignalType" SG_ 2155012096 SODRIC_Ind2 "BLN";
BA_ "PacketOrder" SG_ 2155012096 SODRIC_Ind2 3;
BA_ "SignalLongName" SG_ 2155012096 SODRIC_Ind2 "Side Obstacle Detection Right Indication Control : Indicator 2";
BA_ "GenSigSendType" SG_ 2155012096 SODRIC_Ind1 10;
BA_ "VNSigAllNodes" SG_ 2155012096 SODRIC_Ind1 1;
BA_ "SignalType" SG_ 2155012096 SODRIC_Ind1 "BLN";
BA_ "PacketOrder" SG_ 2155012096 SODRIC_Ind1 2;
BA_ "SignalLongName" SG_ 2155012096 SODRIC_Ind1 "Side Obstacle Detection Right Indication Control : Indicator 1";
BA_ "GenSigSendType" SG_ 2155012096 SODRIC_IndReq 10;
BA_ "VNSigAllNodes" SG_ 2155012096 SODRIC_IndReq 1;
BA_ "SignalType" SG_ 2155012096 SODRIC_IndReq "ENM";
BA_ "PacketOrder" SG_ 2155012096 SODRIC_IndReq 1;
BA_ "SignalLongName" SG_ 2155012096 SODRIC_IndReq "Side Obstacle Detection Right Indication Control : Indication Request";
BA_ "GenSigSendOnInit" SG_ 2155012096 SrvSODSysIO 2;
BA_ "GenSigSendType" SG_ 2155012096 SrvSODSysIO 10;
BA_ "VNSigAllNodes" SG_ 2155012096 SrvSODSysIO 1;
BA_ "SignalType" SG_ 2155012096 SrvSODSysIO "BLN";
BA_ "SignalLongName" SG_ 2155012096 SrvSODSysIO "Service Side Obstacle Detection System Indication On";
BA_ "VNSigDiagnostic" SG_ 932 DgnInf 1;
BA_ "GenSigSendType" SG_ 932 DgnInf 12;
BA_ "GenSigDeltaValue" SG_ 932 DgnInf 1;
BA_ "VNSigAllNodes" SG_ 932 DgnInf 1;
BA_ "SignalType" SG_ 932 DgnInf "UNM";
BA_ "SignalLongName" SG_ 932 DgnInf "Diagnostic Information";
BA_ "VNSigDiagnostic" SG_ 936 DgnInf 1;
BA_ "GenSigSendType" SG_ 936 DgnInf 12;
BA_ "GenSigDeltaValue" SG_ 936 DgnInf 1;
BA_ "VNSigAllNodes" SG_ 936 DgnInf 1;
BA_ "SignalType" SG_ 936 DgnInf "UNM";
BA_ "SignalLongName" SG_ 936 DgnInf "Diagnostic Information";
BA_ "VNSigDiagnostic" SG_ 921 DgnInf 1;
BA_ "GenSigSendType" SG_ 921 DgnInf 12;
BA_ "GenSigDeltaValue" SG_ 921 DgnInf 1;
BA_ "VNSigAllNodes" SG_ 921 DgnInf 1;
BA_ "SignalType" SG_ 921 DgnInf "UNM";
BA_ "SignalLongName" SG_ 921 DgnInf "Diagnostic Information";
BA_ "GenSigSendType" SG_ 2151702528 LnMrkngIndRgt 10;
BA_ "VNSigAllNodes" SG_ 2151702528 LnMrkngIndRgt 1;
BA_ "SignalType" SG_ 2151702528 LnMrkngIndRgt "ENM";
BA_ "SignalLongName" SG_ 2151702528 LnMrkngIndRgt "Lane Marking Indication Right";
BA_ "GenSigSendType" SG_ 2151702528 LnMrkngIndLft 10;
BA_ "VNSigAllNodes" SG_ 2151702528 LnMrkngIndLft 1;
BA_ "SignalType" SG_ 2151702528 LnMrkngIndLft "ENM";
BA_ "SignalLongName" SG_ 2151702528 LnMrkngIndLft "Lane Marking Indication Left";
BA_ "GenSigSendType" SG_ 2151702528 LnKepAsstStIndRgt 10;
BA_ "VNSigAllNodes" SG_ 2151702528 LnKepAsstStIndRgt 1;
BA_ "SignalType" SG_ 2151702528 LnKepAsstStIndRgt "ENM";
BA_ "SignalLongName" SG_ 2151702528 LnKepAsstStIndRgt "Lane Keeping Assist State Indication Right";
BA_ "GenSigSendType" SG_ 2151702528 LnKepAsstStIndLft 10;
BA_ "VNSigAllNodes" SG_ 2151702528 LnKepAsstStIndLft 1;
BA_ "SignalType" SG_ 2151702528 LnKepAsstStIndLft "ENM";
BA_ "SignalLongName" SG_ 2151702528 LnKepAsstStIndLft "Lane Keeping Assist State Indication Left";
BA_ "GenSigSendType" SG_ 2151702528 LnKpngAstRecfblIndRq 10;
BA_ "VNSigAllNodes" SG_ 2151702528 LnKpngAstRecfblIndRq 1;
BA_ "SignalType" SG_ 2151702528 LnKpngAstRecfblIndRq "ENM";
BA_ "SignalLongName" SG_ 2151702528 LnKpngAstRecfblIndRq "Lane Keeping Assist Reconfigurable Icon Indication Request";
BA_ "GenSigSendOnInit" SG_ 2155126784 DrvrSetRrwrdMvmnt 2;
BA_ "GenSigSendType" SG_ 2155126784 DrvrSetRrwrdMvmnt 10;
BA_ "VNSigAllNodes" SG_ 2155126784 DrvrSetRrwrdMvmnt 1;
BA_ "SignalType" SG_ 2155126784 DrvrSetRrwrdMvmnt "ENM";
BA_ "SignalLongName" SG_ 2155126784 DrvrSetRrwrdMvmnt "Driver Seat Rearward Movement";
BA_ "GenSigSendOnInit" SG_ 2155102208 DSMP_UnsdRsrvd 2;
BA_ "GenSigSendType" SG_ 2155102208 DSMP_UnsdRsrvd 10;
BA_ "VNSigAllNodes" SG_ 2155102208 DSMP_UnsdRsrvd 1;
BA_ "SignalType" SG_ 2155102208 DSMP_UnsdRsrvd "BLN";
BA_ "PacketOrder" SG_ 2155102208 DSMP_UnsdRsrvd 17;
BA_ "SignalLongName" SG_ 2155102208 DSMP_UnsdRsrvd "Driver Seat Massage Priority : Unused and Reserved";
BA_ "GenSigSendOnInit" SG_ 2155102208 DSMP_MaxDispVal 2;
BA_ "GenSigSendType" SG_ 2155102208 DSMP_MaxDispVal 12;
BA_ "GenSigDeltaValue" SG_ 2155102208 DSMP_MaxDispVal 1;
BA_ "VNSigAllNodes" SG_ 2155102208 DSMP_MaxDispVal 1;
BA_ "SignalType" SG_ 2155102208 DSMP_MaxDispVal "UNM";
BA_ "PacketOrder" SG_ 2155102208 DSMP_MaxDispVal 16;
BA_ "SignalLongName" SG_ 2155102208 DSMP_MaxDispVal "Driver Seat Massage Priority : Maximum Display Value";
BA_ "GenSigSendOnInit" SG_ 2155102208 DSMP_Type15 2;
BA_ "GenSigSendType" SG_ 2155102208 DSMP_Type15 12;
BA_ "GenSigDeltaValue" SG_ 2155102208 DSMP_Type15 1;
BA_ "VNSigAllNodes" SG_ 2155102208 DSMP_Type15 1;
BA_ "SignalType" SG_ 2155102208 DSMP_Type15 "UNM";
BA_ "PacketOrder" SG_ 2155102208 DSMP_Type15 15;
BA_ "SignalLongName" SG_ 2155102208 DSMP_Type15 "Driver Seat Massage Priority : Type 15";
BA_ "GenSigSendOnInit" SG_ 2155102208 DSMP_Type14 2;
BA_ "GenSigSendType" SG_ 2155102208 DSMP_Type14 12;
BA_ "GenSigDeltaValue" SG_ 2155102208 DSMP_Type14 1;
BA_ "VNSigAllNodes" SG_ 2155102208 DSMP_Type14 1;
BA_ "SignalType" SG_ 2155102208 DSMP_Type14 "UNM";
BA_ "PacketOrder" SG_ 2155102208 DSMP_Type14 14;
BA_ "SignalLongName" SG_ 2155102208 DSMP_Type14 "Driver Seat Massage Priority : Type 14";
BA_ "GenSigSendOnInit" SG_ 2155102208 DSMP_Type13 2;
BA_ "GenSigSendType" SG_ 2155102208 DSMP_Type13 12;
BA_ "GenSigDeltaValue" SG_ 2155102208 DSMP_Type13 1;
BA_ "VNSigAllNodes" SG_ 2155102208 DSMP_Type13 1;
BA_ "SignalType" SG_ 2155102208 DSMP_Type13 "UNM";
BA_ "PacketOrder" SG_ 2155102208 DSMP_Type13 13;
BA_ "SignalLongName" SG_ 2155102208 DSMP_Type13 "Driver Seat Massage Priority : Type 13";
BA_ "GenSigSendOnInit" SG_ 2155102208 DSMP_Type12 2;
BA_ "GenSigSendType" SG_ 2155102208 DSMP_Type12 12;
BA_ "GenSigDeltaValue" SG_ 2155102208 DSMP_Type12 1;
BA_ "VNSigAllNodes" SG_ 2155102208 DSMP_Type12 1;
BA_ "SignalType" SG_ 2155102208 DSMP_Type12 "UNM";
BA_ "PacketOrder" SG_ 2155102208 DSMP_Type12 12;
BA_ "SignalLongName" SG_ 2155102208 DSMP_Type12 "Driver Seat Massage Priority : Type 12";
BA_ "GenSigSendOnInit" SG_ 2155102208 DSMP_Type11 2;
BA_ "GenSigSendType" SG_ 2155102208 DSMP_Type11 12;
BA_ "GenSigDeltaValue" SG_ 2155102208 DSMP_Type11 1;
BA_ "VNSigAllNodes" SG_ 2155102208 DSMP_Type11 1;
BA_ "SignalType" SG_ 2155102208 DSMP_Type11 "UNM";
BA_ "PacketOrder" SG_ 2155102208 DSMP_Type11 11;
BA_ "SignalLongName" SG_ 2155102208 DSMP_Type11 "Driver Seat Massage Priority : Type 11";
BA_ "GenSigSendOnInit" SG_ 2155102208 DSMP_Type10 2;
BA_ "GenSigSendType" SG_ 2155102208 DSMP_Type10 12;
BA_ "GenSigDeltaValue" SG_ 2155102208 DSMP_Type10 1;
BA_ "VNSigAllNodes" SG_ 2155102208 DSMP_Type10 1;
BA_ "SignalType" SG_ 2155102208 DSMP_Type10 "UNM";
BA_ "PacketOrder" SG_ 2155102208 DSMP_Type10 10;
BA_ "SignalLongName" SG_ 2155102208 DSMP_Type10 "Driver Seat Massage Priority : Type 10";
BA_ "GenSigSendOnInit" SG_ 2155102208 DSMP_Type9 2;
BA_ "GenSigSendType" SG_ 2155102208 DSMP_Type9 12;
BA_ "GenSigDeltaValue" SG_ 2155102208 DSMP_Type9 1;
BA_ "VNSigAllNodes" SG_ 2155102208 DSMP_Type9 1;
BA_ "SignalType" SG_ 2155102208 DSMP_Type9 "UNM";
BA_ "PacketOrder" SG_ 2155102208 DSMP_Type9 9;
BA_ "SignalLongName" SG_ 2155102208 DSMP_Type9 "Driver Seat Massage Priority : Type 9";
BA_ "GenSigSendOnInit" SG_ 2155102208 DSMP_Type8 2;
BA_ "GenSigSendType" SG_ 2155102208 DSMP_Type8 12;
BA_ "GenSigDeltaValue" SG_ 2155102208 DSMP_Type8 1;
BA_ "VNSigAllNodes" SG_ 2155102208 DSMP_Type8 1;
BA_ "SignalType" SG_ 2155102208 DSMP_Type8 "UNM";
BA_ "PacketOrder" SG_ 2155102208 DSMP_Type8 8;
BA_ "SignalLongName" SG_ 2155102208 DSMP_Type8 "Driver Seat Massage Priority : Type 8";
BA_ "GenSigSendOnInit" SG_ 2155102208 DSMP_Type7 2;
BA_ "GenSigSendType" SG_ 2155102208 DSMP_Type7 12;
BA_ "GenSigDeltaValue" SG_ 2155102208 DSMP_Type7 1;
BA_ "VNSigAllNodes" SG_ 2155102208 DSMP_Type7 1;
BA_ "SignalType" SG_ 2155102208 DSMP_Type7 "UNM";
BA_ "PacketOrder" SG_ 2155102208 DSMP_Type7 7;
BA_ "SignalLongName" SG_ 2155102208 DSMP_Type7 "Driver Seat Massage Priority : Type 7";
BA_ "GenSigSendOnInit" SG_ 2155102208 DSMP_Type6 2;
BA_ "GenSigSendType" SG_ 2155102208 DSMP_Type6 12;
BA_ "GenSigDeltaValue" SG_ 2155102208 DSMP_Type6 1;
BA_ "VNSigAllNodes" SG_ 2155102208 DSMP_Type6 1;
BA_ "SignalType" SG_ 2155102208 DSMP_Type6 "UNM";
BA_ "PacketOrder" SG_ 2155102208 DSMP_Type6 6;
BA_ "SignalLongName" SG_ 2155102208 DSMP_Type6 "Driver Seat Massage Priority : Type 6";
BA_ "GenSigSendOnInit" SG_ 2155102208 DSMP_Type5 2;
BA_ "GenSigSendType" SG_ 2155102208 DSMP_Type5 12;
BA_ "GenSigDeltaValue" SG_ 2155102208 DSMP_Type5 1;
BA_ "VNSigAllNodes" SG_ 2155102208 DSMP_Type5 1;
BA_ "SignalType" SG_ 2155102208 DSMP_Type5 "UNM";
BA_ "PacketOrder" SG_ 2155102208 DSMP_Type5 5;
BA_ "SignalLongName" SG_ 2155102208 DSMP_Type5 "Driver Seat Massage Priority : Type 5";
BA_ "GenSigSendOnInit" SG_ 2155102208 DSMP_Type4 2;
BA_ "GenSigSendType" SG_ 2155102208 DSMP_Type4 12;
BA_ "GenSigDeltaValue" SG_ 2155102208 DSMP_Type4 1;
BA_ "VNSigAllNodes" SG_ 2155102208 DSMP_Type4 1;
BA_ "SignalType" SG_ 2155102208 DSMP_Type4 "UNM";
BA_ "PacketOrder" SG_ 2155102208 DSMP_Type4 4;
BA_ "SignalLongName" SG_ 2155102208 DSMP_Type4 "Driver Seat Massage Priority : Type 4";
BA_ "GenSigSendOnInit" SG_ 2155102208 DSMP_Type3 2;
BA_ "GenSigSendType" SG_ 2155102208 DSMP_Type3 12;
BA_ "GenSigDeltaValue" SG_ 2155102208 DSMP_Type3 1;
BA_ "VNSigAllNodes" SG_ 2155102208 DSMP_Type3 1;
BA_ "SignalType" SG_ 2155102208 DSMP_Type3 "UNM";
BA_ "PacketOrder" SG_ 2155102208 DSMP_Type3 3;
BA_ "SignalLongName" SG_ 2155102208 DSMP_Type3 "Driver Seat Massage Priority : Type 3";
BA_ "GenSigSendOnInit" SG_ 2155102208 DSMP_Type2 2;
BA_ "GenSigSendType" SG_ 2155102208 DSMP_Type2 12;
BA_ "GenSigDeltaValue" SG_ 2155102208 DSMP_Type2 1;
BA_ "VNSigAllNodes" SG_ 2155102208 DSMP_Type2 1;
BA_ "SignalType" SG_ 2155102208 DSMP_Type2 "UNM";
BA_ "PacketOrder" SG_ 2155102208 DSMP_Type2 2;
BA_ "SignalLongName" SG_ 2155102208 DSMP_Type2 "Driver Seat Massage Priority : Type 2";
BA_ "GenSigSendOnInit" SG_ 2155102208 DSMP_Type1 2;
BA_ "GenSigSendType" SG_ 2155102208 DSMP_Type1 12;
BA_ "GenSigDeltaValue" SG_ 2155102208 DSMP_Type1 1;
BA_ "VNSigAllNodes" SG_ 2155102208 DSMP_Type1 1;
BA_ "SignalType" SG_ 2155102208 DSMP_Type1 "UNM";
BA_ "PacketOrder" SG_ 2155102208 DSMP_Type1 1;
BA_ "SignalLongName" SG_ 2155102208 DSMP_Type1 "Driver Seat Massage Priority : Type 1";
BA_ "GenSigSendOnInit" SG_ 2155085824 StrgColUpDwnPos 2;
BA_ "GenSigSendType" SG_ 2155085824 StrgColUpDwnPos 12;
BA_ "GenSigDeltaValue" SG_ 2155085824 StrgColUpDwnPos 1;
BA_ "VNSigAllNodes" SG_ 2155085824 StrgColUpDwnPos 1;
BA_ "SignalType" SG_ 2155085824 StrgColUpDwnPos "UNM";
BA_ "SignalLongName" SG_ 2155085824 StrgColUpDwnPos "Steering Column Up Down Position";
BA_ "GenSigSendOnInit" SG_ 2155085824 CPMAPINFO4 2;
BA_ "GenSigSendType" SG_ 2155085824 CPMAPINFO4 10;
BA_ "VNSigAllNodes" SG_ 2155085824 CPMAPINFO4 1;
BA_ "SignalType" SG_ 2155085824 CPMAPINFO4 "ENM";
BA_ "SignalLongName" SG_ 2155085824 CPMAPINFO4 "Steering Column Internal Fault";
BA_ "GenSigSendOnInit" SG_ 2155085824 StrgColInOutPos 2;
BA_ "GenSigSendType" SG_ 2155085824 StrgColInOutPos 12;
BA_ "GenSigDeltaValue" SG_ 2155085824 StrgColInOutPos 1;
BA_ "VNSigAllNodes" SG_ 2155085824 StrgColInOutPos 1;
BA_ "SignalType" SG_ 2155085824 StrgColInOutPos "UNM";
BA_ "SignalLongName" SG_ 2155085824 StrgColInOutPos "Steering Column In Out Position";
BA_ "GenSigSendOnInit" SG_ 2155085824 StrgColCommsFlt 2;
BA_ "GenSigSendType" SG_ 2155085824 StrgColCommsFlt 10;
BA_ "VNSigAllNodes" SG_ 2155085824 StrgColCommsFlt 1;
BA_ "SignalType" SG_ 2155085824 StrgColCommsFlt "ENM";
BA_ "SignalLongName" SG_ 2155085824 StrgColCommsFlt "Steering Column Communications Fault";
BA_ "GenSigSendOnInit" SG_ 2155085824 DSCDS_UnsdRsrvd 2;
BA_ "GenSigSendType" SG_ 2155085824 DSCDS_UnsdRsrvd 12;
BA_ "GenSigDeltaValue" SG_ 2155085824 DSCDS_UnsdRsrvd 1;
BA_ "VNSigAllNodes" SG_ 2155085824 DSCDS_UnsdRsrvd 1;
BA_ "SignalType" SG_ 2155085824 DSCDS_UnsdRsrvd "UNM";
BA_ "PacketOrder" SG_ 2155085824 DSCDS_UnsdRsrvd 19;
BA_ "SignalLongName" SG_ 2155085824 DSCDS_UnsdRsrvd "Driver Seat Control Display Status : Unused and Reserved";
BA_ "GenSigSendOnInit" SG_ 2155085824 DSCDS_DispReq 2;
BA_ "GenSigSendType" SG_ 2155085824 DSCDS_DispReq 10;
BA_ "VNSigAllNodes" SG_ 2155085824 DSCDS_DispReq 1;
BA_ "SignalType" SG_ 2155085824 DSCDS_DispReq "BLN";
BA_ "PacketOrder" SG_ 2155085824 DSCDS_DispReq 18;
BA_ "SignalLongName" SG_ 2155085824 DSCDS_DispReq "Driver Seat Control Display Status : Display Request";
BA_ "GenSigSendOnInit" SG_ 2155085824 DSCDS_DispSz 2;
BA_ "GenSigSendType" SG_ 2155085824 DSCDS_DispSz 10;
BA_ "VNSigAllNodes" SG_ 2155085824 DSCDS_DispSz 1;
BA_ "SignalType" SG_ 2155085824 DSCDS_DispSz "ENM";
BA_ "PacketOrder" SG_ 2155085824 DSCDS_DispSz 17;
BA_ "SignalLongName" SG_ 2155085824 DSCDS_DispSz "Driver Seat Control Display Status : Display Size";
BA_ "GenSigSendOnInit" SG_ 2155085824 DSCDS_CshLgAdjFdRr 2;
BA_ "GenSigSendType" SG_ 2155085824 DSCDS_CshLgAdjFdRr 10;
BA_ "VNSigAllNodes" SG_ 2155085824 DSCDS_CshLgAdjFdRr 1;
BA_ "SignalType" SG_ 2155085824 DSCDS_CshLgAdjFdRr "ENM";
BA_ "PacketOrder" SG_ 2155085824 DSCDS_CshLgAdjFdRr 16;
BA_ "SignalLongName" SG_ 2155085824 DSCDS_CshLgAdjFdRr "Driver Seat Control Display Status : Cushion Length Adjustment Forward/Rearward";
BA_ "GenSigSendOnInit" SG_ 2155085824 DSCDS_BkCshBlstInOt 2;
BA_ "GenSigSendType" SG_ 2155085824 DSCDS_BkCshBlstInOt 10;
BA_ "VNSigAllNodes" SG_ 2155085824 DSCDS_BkCshBlstInOt 1;
BA_ "SignalType" SG_ 2155085824 DSCDS_BkCshBlstInOt "ENM";
BA_ "PacketOrder" SG_ 2155085824 DSCDS_BkCshBlstInOt 15;
BA_ "SignalLongName" SG_ 2155085824 DSCDS_BkCshBlstInOt "Driver Seat Control Display Status : Back and Cushion Bolster In/Out";
BA_ "GenSigSendOnInit" SG_ 2155085824 DSCDS_CshBlstrInOut 2;
BA_ "GenSigSendType" SG_ 2155085824 DSCDS_CshBlstrInOut 10;
BA_ "VNSigAllNodes" SG_ 2155085824 DSCDS_CshBlstrInOut 1;
BA_ "SignalType" SG_ 2155085824 DSCDS_CshBlstrInOut "ENM";
BA_ "PacketOrder" SG_ 2155085824 DSCDS_CshBlstrInOut 14;
BA_ "SignalLongName" SG_ 2155085824 DSCDS_CshBlstrInOut "Driver Seat Control Display Status : Cushion Bolster In/Out";
BA_ "GenSigSendOnInit" SG_ 2155085824 DSCDS_BkBlstrInOut 2;
BA_ "GenSigSendType" SG_ 2155085824 DSCDS_BkBlstrInOut 10;
BA_ "VNSigAllNodes" SG_ 2155085824 DSCDS_BkBlstrInOut 1;
BA_ "SignalType" SG_ 2155085824 DSCDS_BkBlstrInOut "ENM";
BA_ "PacketOrder" SG_ 2155085824 DSCDS_BkBlstrInOut 13;
BA_ "SignalLongName" SG_ 2155085824 DSCDS_BkBlstrInOut "Driver Seat Control Display Status : Back Bolster In/Out";
BA_ "GenSigSendOnInit" SG_ 2155085824 DSCDS_LmbrUDnFdRr 2;
BA_ "GenSigSendType" SG_ 2155085824 DSCDS_LmbrUDnFdRr 10;
BA_ "VNSigAllNodes" SG_ 2155085824 DSCDS_LmbrUDnFdRr 1;
BA_ "SignalType" SG_ 2155085824 DSCDS_LmbrUDnFdRr "ENM";
BA_ "PacketOrder" SG_ 2155085824 DSCDS_LmbrUDnFdRr 12;
BA_ "SignalLongName" SG_ 2155085824 DSCDS_LmbrUDnFdRr "Driver Seat Control Display Status : Lumbar Up/Down and Forward/Rearward";
BA_ "GenSigSendOnInit" SG_ 2155085824 DSCDS_LmbrFwdRr 2;
BA_ "GenSigSendType" SG_ 2155085824 DSCDS_LmbrFwdRr 10;
BA_ "VNSigAllNodes" SG_ 2155085824 DSCDS_LmbrFwdRr 1;
BA_ "SignalType" SG_ 2155085824 DSCDS_LmbrFwdRr "ENM";
BA_ "PacketOrder" SG_ 2155085824 DSCDS_LmbrFwdRr 11;
BA_ "SignalLongName" SG_ 2155085824 DSCDS_LmbrFwdRr "Driver Seat Control Display Status : Lumbar Forward/Rearward";
BA_ "GenSigSendOnInit" SG_ 2155085824 DSCDS_LmbrUpDwn 2;
BA_ "GenSigSendType" SG_ 2155085824 DSCDS_LmbrUpDwn 10;
BA_ "VNSigAllNodes" SG_ 2155085824 DSCDS_LmbrUpDwn 1;
BA_ "SignalType" SG_ 2155085824 DSCDS_LmbrUpDwn "ENM";
BA_ "PacketOrder" SG_ 2155085824 DSCDS_LmbrUpDwn 10;
BA_ "SignalLongName" SG_ 2155085824 DSCDS_LmbrUpDwn "Driver Seat Control Display Status : Lumbar Up/Down";
BA_ "GenSigSendOnInit" SG_ 2155085824 DSCDS_UprShldrFdRr 2;
BA_ "GenSigSendType" SG_ 2155085824 DSCDS_UprShldrFdRr 10;
BA_ "VNSigAllNodes" SG_ 2155085824 DSCDS_UprShldrFdRr 1;
BA_ "SignalType" SG_ 2155085824 DSCDS_UprShldrFdRr "ENM";
BA_ "PacketOrder" SG_ 2155085824 DSCDS_UprShldrFdRr 9;
BA_ "SignalLongName" SG_ 2155085824 DSCDS_UprShldrFdRr "Driver Seat Control Display Status : Upper Shoulder Forward/Rearward";
BA_ "GenSigSendOnInit" SG_ 2155085824 DSCDS_HdrstTltFwdRr 2;
BA_ "GenSigSendType" SG_ 2155085824 DSCDS_HdrstTltFwdRr 10;
BA_ "VNSigAllNodes" SG_ 2155085824 DSCDS_HdrstTltFwdRr 1;
BA_ "SignalType" SG_ 2155085824 DSCDS_HdrstTltFwdRr "ENM";
BA_ "PacketOrder" SG_ 2155085824 DSCDS_HdrstTltFwdRr 8;
BA_ "SignalLongName" SG_ 2155085824 DSCDS_HdrstTltFwdRr "Driver Seat Control Display Status : Headrest Tilt Forward/Rearward";
BA_ "GenSigSendOnInit" SG_ 2155085824 DSCDS_HdrstWngInOt 2;
BA_ "GenSigSendType" SG_ 2155085824 DSCDS_HdrstWngInOt 10;
BA_ "VNSigAllNodes" SG_ 2155085824 DSCDS_HdrstWngInOt 1;
BA_ "SignalType" SG_ 2155085824 DSCDS_HdrstWngInOt "ENM";
BA_ "PacketOrder" SG_ 2155085824 DSCDS_HdrstWngInOt 7;
BA_ "SignalLongName" SG_ 2155085824 DSCDS_HdrstWngInOt "Driver Seat Control Display Status : Headrest Wings In/Out";
BA_ "GenSigSendOnInit" SG_ 2155085824 DSCDS_HdrstUDnFdRr 2;
BA_ "GenSigSendType" SG_ 2155085824 DSCDS_HdrstUDnFdRr 10;
BA_ "VNSigAllNodes" SG_ 2155085824 DSCDS_HdrstUDnFdRr 1;
BA_ "SignalType" SG_ 2155085824 DSCDS_HdrstUDnFdRr "ENM";
BA_ "PacketOrder" SG_ 2155085824 DSCDS_HdrstUDnFdRr 6;
BA_ "SignalLongName" SG_ 2155085824 DSCDS_HdrstUDnFdRr "Driver Seat Control Display Status : Headrest Forward/Rearward and Up/Down";
BA_ "GenSigSendOnInit" SG_ 2155085824 DSCDS_HdrstFwdRrwd 2;
BA_ "GenSigSendType" SG_ 2155085824 DSCDS_HdrstFwdRrwd 10;
BA_ "VNSigAllNodes" SG_ 2155085824 DSCDS_HdrstFwdRrwd 1;
BA_ "SignalType" SG_ 2155085824 DSCDS_HdrstFwdRrwd "ENM";
BA_ "PacketOrder" SG_ 2155085824 DSCDS_HdrstFwdRrwd 5;
BA_ "SignalLongName" SG_ 2155085824 DSCDS_HdrstFwdRrwd "Driver Seat Control Display Status : Headrest Forward/Rearward";
BA_ "GenSigSendOnInit" SG_ 2155085824 DSCDS_HdrstUpDn 2;
BA_ "GenSigSendType" SG_ 2155085824 DSCDS_HdrstUpDn 10;
BA_ "VNSigAllNodes" SG_ 2155085824 DSCDS_HdrstUpDn 1;
BA_ "SignalType" SG_ 2155085824 DSCDS_HdrstUpDn "ENM";
BA_ "PacketOrder" SG_ 2155085824 DSCDS_HdrstUpDn 4;
BA_ "SignalLongName" SG_ 2155085824 DSCDS_HdrstUpDn "Driver Seat Control Display Status : Headrest Up/Down";
BA_ "GenSigSendOnInit" SG_ 2155085824 DSCDS_MassgIntsty 2;
BA_ "GenSigSendType" SG_ 2155085824 DSCDS_MassgIntsty 10;
BA_ "VNSigAllNodes" SG_ 2155085824 DSCDS_MassgIntsty 1;
BA_ "SignalType" SG_ 2155085824 DSCDS_MassgIntsty "ENM";
BA_ "PacketOrder" SG_ 2155085824 DSCDS_MassgIntsty 3;
BA_ "SignalLongName" SG_ 2155085824 DSCDS_MassgIntsty "Driver Seat Control Display Status : Massage Intensity";
BA_ "GenSigSendOnInit" SG_ 2155085824 DSCDS_MassgTyp 2;
BA_ "GenSigSendType" SG_ 2155085824 DSCDS_MassgTyp 10;
BA_ "VNSigAllNodes" SG_ 2155085824 DSCDS_MassgTyp 1;
BA_ "SignalType" SG_ 2155085824 DSCDS_MassgTyp "ENM";
BA_ "PacketOrder" SG_ 2155085824 DSCDS_MassgTyp 2;
BA_ "SignalLongName" SG_ 2155085824 DSCDS_MassgTyp "Driver Seat Control Display Status : Massage Type";
BA_ "GenSigSendOnInit" SG_ 2155085824 DSCDS_Massg 2;
BA_ "GenSigSendType" SG_ 2155085824 DSCDS_Massg 10;
BA_ "VNSigAllNodes" SG_ 2155085824 DSCDS_Massg 1;
BA_ "SignalType" SG_ 2155085824 DSCDS_Massg "ENM";
BA_ "PacketOrder" SG_ 2155085824 DSCDS_Massg 1;
BA_ "SignalLongName" SG_ 2155085824 DSCDS_Massg "Driver Seat Control Display Status : Massage";
BA_ "GenSigSendOnInit" SG_ 2155069440 DSAP_UnsdRsrvd 2;
BA_ "GenSigSendType" SG_ 2155069440 DSAP_UnsdRsrvd 12;
BA_ "GenSigDeltaValue" SG_ 2155069440 DSAP_UnsdRsrvd 1;
BA_ "VNSigAllNodes" SG_ 2155069440 DSAP_UnsdRsrvd 1;
BA_ "SignalType" SG_ 2155069440 DSAP_UnsdRsrvd "UNM";
BA_ "PacketOrder" SG_ 2155069440 DSAP_UnsdRsrvd 16;
BA_ "SignalLongName" SG_ 2155069440 DSAP_UnsdRsrvd "Driver Seat Actuator Priority : Unused and Reserved";
BA_ "GenSigSendOnInit" SG_ 2155069440 DSAP_DispSz 2;
BA_ "GenSigSendType" SG_ 2155069440 DSAP_DispSz 12;
BA_ "GenSigDeltaValue" SG_ 2155069440 DSAP_DispSz 1;
BA_ "VNSigAllNodes" SG_ 2155069440 DSAP_DispSz 1;
BA_ "SignalType" SG_ 2155069440 DSAP_DispSz "UNM";
BA_ "PacketOrder" SG_ 2155069440 DSAP_DispSz 15;
BA_ "SignalLongName" SG_ 2155069440 DSAP_DispSz "Driver Seat Actuator Priority : Display Size";
BA_ "GenSigSendOnInit" SG_ 2155069440 DSAP_CshLgthAdjFdRr 2;
BA_ "GenSigSendType" SG_ 2155069440 DSAP_CshLgthAdjFdRr 12;
BA_ "GenSigDeltaValue" SG_ 2155069440 DSAP_CshLgthAdjFdRr 1;
BA_ "VNSigAllNodes" SG_ 2155069440 DSAP_CshLgthAdjFdRr 1;
BA_ "SignalType" SG_ 2155069440 DSAP_CshLgthAdjFdRr "UNM";
BA_ "PacketOrder" SG_ 2155069440 DSAP_CshLgthAdjFdRr 14;
BA_ "SignalLongName" SG_ 2155069440 DSAP_CshLgthAdjFdRr "Driver Seat Actuator Priority : Cushion Length Adjustment Forward/Rearward";
BA_ "GenSigSendOnInit" SG_ 2155069440 DSAP_BkCshBlstrInOut 2;
BA_ "GenSigSendType" SG_ 2155069440 DSAP_BkCshBlstrInOut 12;
BA_ "GenSigDeltaValue" SG_ 2155069440 DSAP_BkCshBlstrInOut 1;
BA_ "VNSigAllNodes" SG_ 2155069440 DSAP_BkCshBlstrInOut 1;
BA_ "SignalType" SG_ 2155069440 DSAP_BkCshBlstrInOut "UNM";
BA_ "PacketOrder" SG_ 2155069440 DSAP_BkCshBlstrInOut 13;
BA_ "SignalLongName" SG_ 2155069440 DSAP_BkCshBlstrInOut "Driver Seat Actuator Priority : Back and Cushion Bolster In/Out";
BA_ "GenSigSendOnInit" SG_ 2155069440 DSAP_CshBlstrInOut 2;
BA_ "GenSigSendType" SG_ 2155069440 DSAP_CshBlstrInOut 12;
BA_ "GenSigDeltaValue" SG_ 2155069440 DSAP_CshBlstrInOut 1;
BA_ "VNSigAllNodes" SG_ 2155069440 DSAP_CshBlstrInOut 1;
BA_ "SignalType" SG_ 2155069440 DSAP_CshBlstrInOut "UNM";
BA_ "PacketOrder" SG_ 2155069440 DSAP_CshBlstrInOut 12;
BA_ "SignalLongName" SG_ 2155069440 DSAP_CshBlstrInOut "Driver Seat Actuator Priority : Cushion Bolster In/Out";
BA_ "GenSigSendOnInit" SG_ 2155069440 DSAP_BkBlstrInOut 2;
BA_ "GenSigSendType" SG_ 2155069440 DSAP_BkBlstrInOut 12;
BA_ "GenSigDeltaValue" SG_ 2155069440 DSAP_BkBlstrInOut 1;
BA_ "VNSigAllNodes" SG_ 2155069440 DSAP_BkBlstrInOut 1;
BA_ "SignalType" SG_ 2155069440 DSAP_BkBlstrInOut "UNM";
BA_ "PacketOrder" SG_ 2155069440 DSAP_BkBlstrInOut 11;
BA_ "SignalLongName" SG_ 2155069440 DSAP_BkBlstrInOut "Driver Seat Actuator Priority : Back Bolster In/Out";
BA_ "GenSigSendOnInit" SG_ 2155069440 DSAP_LmbrUpDnFdRr 2;
BA_ "GenSigSendType" SG_ 2155069440 DSAP_LmbrUpDnFdRr 12;
BA_ "GenSigDeltaValue" SG_ 2155069440 DSAP_LmbrUpDnFdRr 1;
BA_ "VNSigAllNodes" SG_ 2155069440 DSAP_LmbrUpDnFdRr 1;
BA_ "SignalType" SG_ 2155069440 DSAP_LmbrUpDnFdRr "UNM";
BA_ "PacketOrder" SG_ 2155069440 DSAP_LmbrUpDnFdRr 10;
BA_ "SignalLongName" SG_ 2155069440 DSAP_LmbrUpDnFdRr "Driver Seat Actuator Priority : Lumbar Up/Down and Forward/Rearward";
BA_ "GenSigSendOnInit" SG_ 2155069440 DSAP_LmbrFwdRr 2;
BA_ "GenSigSendType" SG_ 2155069440 DSAP_LmbrFwdRr 12;
BA_ "GenSigDeltaValue" SG_ 2155069440 DSAP_LmbrFwdRr 1;
BA_ "VNSigAllNodes" SG_ 2155069440 DSAP_LmbrFwdRr 1;
BA_ "SignalType" SG_ 2155069440 DSAP_LmbrFwdRr "UNM";
BA_ "PacketOrder" SG_ 2155069440 DSAP_LmbrFwdRr 9;
BA_ "SignalLongName" SG_ 2155069440 DSAP_LmbrFwdRr "Driver Seat Actuator Priority : Lumbar Forward/Rearward";
BA_ "GenSigSendOnInit" SG_ 2155069440 DSAP_LmbrUpDwn 2;
BA_ "GenSigSendType" SG_ 2155069440 DSAP_LmbrUpDwn 12;
BA_ "GenSigDeltaValue" SG_ 2155069440 DSAP_LmbrUpDwn 1;
BA_ "VNSigAllNodes" SG_ 2155069440 DSAP_LmbrUpDwn 1;
BA_ "SignalType" SG_ 2155069440 DSAP_LmbrUpDwn "UNM";
BA_ "PacketOrder" SG_ 2155069440 DSAP_LmbrUpDwn 8;
BA_ "SignalLongName" SG_ 2155069440 DSAP_LmbrUpDwn "Driver Seat Actuator Priority : Lumbar Up/Down";
BA_ "GenSigSendOnInit" SG_ 2155069440 DSAP_UprShldrFwdRr 2;
BA_ "GenSigSendType" SG_ 2155069440 DSAP_UprShldrFwdRr 12;
BA_ "GenSigDeltaValue" SG_ 2155069440 DSAP_UprShldrFwdRr 1;
BA_ "VNSigAllNodes" SG_ 2155069440 DSAP_UprShldrFwdRr 1;
BA_ "SignalType" SG_ 2155069440 DSAP_UprShldrFwdRr "UNM";
BA_ "PacketOrder" SG_ 2155069440 DSAP_UprShldrFwdRr 7;
BA_ "SignalLongName" SG_ 2155069440 DSAP_UprShldrFwdRr "Driver Seat Actuator Priority : Upper Shoulder Forward/Rearward";
BA_ "GenSigSendOnInit" SG_ 2155069440 DSAP_HdrstTltFwdRr 2;
BA_ "GenSigSendType" SG_ 2155069440 DSAP_HdrstTltFwdRr 12;
BA_ "GenSigDeltaValue" SG_ 2155069440 DSAP_HdrstTltFwdRr 1;
BA_ "VNSigAllNodes" SG_ 2155069440 DSAP_HdrstTltFwdRr 1;
BA_ "SignalType" SG_ 2155069440 DSAP_HdrstTltFwdRr "UNM";
BA_ "PacketOrder" SG_ 2155069440 DSAP_HdrstTltFwdRr 6;
BA_ "SignalLongName" SG_ 2155069440 DSAP_HdrstTltFwdRr "Driver Seat Actuator Priority : Headrest Tilt Forward/Rearward";
BA_ "GenSigSendOnInit" SG_ 2155069440 DSAP_HdrstWngsInOut 2;
BA_ "GenSigSendType" SG_ 2155069440 DSAP_HdrstWngsInOut 12;
BA_ "GenSigDeltaValue" SG_ 2155069440 DSAP_HdrstWngsInOut 1;
BA_ "VNSigAllNodes" SG_ 2155069440 DSAP_HdrstWngsInOut 1;
BA_ "SignalType" SG_ 2155069440 DSAP_HdrstWngsInOut "UNM";
BA_ "PacketOrder" SG_ 2155069440 DSAP_HdrstWngsInOut 5;
BA_ "SignalLongName" SG_ 2155069440 DSAP_HdrstWngsInOut "Driver Seat Actuator Priority : Headrest Wings Inward/Outward";
BA_ "GenSigSendOnInit" SG_ 2155069440 DSAP_HdrstUpDnFdRr 2;
BA_ "GenSigSendType" SG_ 2155069440 DSAP_HdrstUpDnFdRr 12;
BA_ "GenSigDeltaValue" SG_ 2155069440 DSAP_HdrstUpDnFdRr 1;
BA_ "VNSigAllNodes" SG_ 2155069440 DSAP_HdrstUpDnFdRr 1;
BA_ "SignalType" SG_ 2155069440 DSAP_HdrstUpDnFdRr "UNM";
BA_ "PacketOrder" SG_ 2155069440 DSAP_HdrstUpDnFdRr 4;
BA_ "SignalLongName" SG_ 2155069440 DSAP_HdrstUpDnFdRr "Driver Seat Actuator Priority : Headrest Up/Down and Forward/Rearward";
BA_ "GenSigSendOnInit" SG_ 2155069440 DSAP_HdrstFwdRrwd 2;
BA_ "GenSigSendType" SG_ 2155069440 DSAP_HdrstFwdRrwd 12;
BA_ "GenSigDeltaValue" SG_ 2155069440 DSAP_HdrstFwdRrwd 1;
BA_ "VNSigAllNodes" SG_ 2155069440 DSAP_HdrstFwdRrwd 1;
BA_ "SignalType" SG_ 2155069440 DSAP_HdrstFwdRrwd "UNM";
BA_ "PacketOrder" SG_ 2155069440 DSAP_HdrstFwdRrwd 3;
BA_ "SignalLongName" SG_ 2155069440 DSAP_HdrstFwdRrwd "Driver Seat Actuator Priority : Headrest Forward/Rearward";
BA_ "GenSigSendOnInit" SG_ 2155069440 DSAP_HdrstUpDn 2;
BA_ "GenSigSendType" SG_ 2155069440 DSAP_HdrstUpDn 12;
BA_ "GenSigDeltaValue" SG_ 2155069440 DSAP_HdrstUpDn 1;
BA_ "VNSigAllNodes" SG_ 2155069440 DSAP_HdrstUpDn 1;
BA_ "SignalType" SG_ 2155069440 DSAP_HdrstUpDn "UNM";
BA_ "PacketOrder" SG_ 2155069440 DSAP_HdrstUpDn 2;
BA_ "SignalLongName" SG_ 2155069440 DSAP_HdrstUpDn "Driver Seat Actuator Priority : Headrest Up/Down";
BA_ "GenSigSendOnInit" SG_ 2155069440 DSAP_Massg 2;
BA_ "GenSigSendType" SG_ 2155069440 DSAP_Massg 12;
BA_ "GenSigDeltaValue" SG_ 2155069440 DSAP_Massg 1;
BA_ "VNSigAllNodes" SG_ 2155069440 DSAP_Massg 1;
BA_ "SignalType" SG_ 2155069440 DSAP_Massg "UNM";
BA_ "PacketOrder" SG_ 2155069440 DSAP_Massg 1;
BA_ "SignalLongName" SG_ 2155069440 DSAP_Massg "Driver Seat Actuator Priority : Massage";
BA_ "VNSigDiagnostic" SG_ 2034 DgnInf 1;
BA_ "GenSigSendType" SG_ 2034 DgnInf 12;
BA_ "GenSigDeltaValue" SG_ 2034 DgnInf 1;
BA_ "VNSigAllNodes" SG_ 2034 DgnInf 1;
BA_ "SignalType" SG_ 2034 DgnInf "UNM";
BA_ "SignalLongName" SG_ 2034 DgnInf "Diagnostic Information";
BA_ "GenSigSendType" SG_ 2152857600 ACCGrnMdStat 10;
BA_ "VNSigAllNodes" SG_ 2152857600 ACCGrnMdStat 1;
BA_ "SignalType" SG_ 2152857600 ACCGrnMdStat "ENM";
BA_ "SignalLongName" SG_ 2152857600 ACCGrnMdStat "Adaptive Cruise Control Green Mode Status";
BA_ "GenSigSendType" SG_ 2152857600 ACCRteSpdAdaptStat 10;
BA_ "VNSigAllNodes" SG_ 2152857600 ACCRteSpdAdaptStat 1;
BA_ "SignalType" SG_ 2152857600 ACCRteSpdAdaptStat "ENM";
BA_ "SignalLongName" SG_ 2152857600 ACCRteSpdAdaptStat "Adaptive Cruise Control Route Speed Adaption Status";
BA_ "GenSigSendType" SG_ 2152857600 ACCRteSpdDrvIntvReq 10;
BA_ "VNSigAllNodes" SG_ 2152857600 ACCRteSpdDrvIntvReq 1;
BA_ "SignalType" SG_ 2152857600 ACCRteSpdDrvIntvReq "ENM";
BA_ "SignalLongName" SG_ 2152857600 ACCRteSpdDrvIntvReq "Adaptive Cruise Control Route Speed Driver Intervention Request";
BA_ "GenSigSendType" SG_ 2152857600 ACCTrfcJamAstActStat 10;
BA_ "VNSigAllNodes" SG_ 2152857600 ACCTrfcJamAstActStat 1;
BA_ "SignalType" SG_ 2152857600 ACCTrfcJamAstActStat "ENM";
BA_ "SignalLongName" SG_ 2152857600 ACCTrfcJamAstActStat "Adaptive Cruise Control Traffic Jam Assist Activation Status";
BA_ "GenSigSendType" SG_ 2152857600 ACCTrfcJamAstRmnTm 12;
BA_ "GenSigDeltaValue" SG_ 2152857600 ACCTrfcJamAstRmnTm 1;
BA_ "VNSigAllNodes" SG_ 2152857600 ACCTrfcJamAstRmnTm 1;
BA_ "SignalType" SG_ 2152857600 ACCTrfcJamAstRmnTm "UNM";
BA_ "SignalLongName" SG_ 2152857600 ACCTrfcJamAstRmnTm "Adaptive Cruise Control Traffic Jam Assist Remaining Time";
BA_ "GenSigSendType" SG_ 2151489536 ACCLwVisbltyIO 10;
BA_ "VNSigAllNodes" SG_ 2151489536 ACCLwVisbltyIO 1;
BA_ "SignalType" SG_ 2151489536 ACCLwVisbltyIO "BLN";
BA_ "SignalLongName" SG_ 2151489536 ACCLwVisbltyIO "Adaptive Cruise Control Low Visibility Indication On";
BA_ "GenSigSendType" SG_ 2151489536 NVSysStat 10;
BA_ "VNSigAllNodes" SG_ 2151489536 NVSysStat 1;
BA_ "SignalType" SG_ 2151489536 NVSysStat "ENM";
BA_ "SignalLongName" SG_ 2151489536 NVSysStat "Night Vision System Status";
BA_ "GenSigSendOnInit" SG_ 2151489536 RVBShtToPrkBfExtngVehIO 2;
BA_ "GenSigSendType" SG_ 2151489536 RVBShtToPrkBfExtngVehIO 10;
BA_ "VNSigAllNodes" SG_ 2151489536 RVBShtToPrkBfExtngVehIO 1;
BA_ "SignalType" SG_ 2151489536 RVBShtToPrkBfExtngVehIO "BLN";
BA_ "SignalLongName" SG_ 2151489536 RVBShtToPrkBfExtngVehIO "RVB Shift to Park Before Exiting Vehicle Indication On";
BA_ "GenSigSendType" SG_ 2151489536 RVBAutoBrkRlsIO 10;
BA_ "VNSigAllNodes" SG_ 2151489536 RVBAutoBrkRlsIO 1;
BA_ "SignalType" SG_ 2151489536 RVBAutoBrkRlsIO "BLN";
BA_ "SignalLongName" SG_ 2151489536 RVBAutoBrkRlsIO "RVB Autonomous Brake Release Indication On";
BA_ "GenSigSendType" SG_ 2152759296 PedWrnIndReq 10;
BA_ "VNSigAllNodes" SG_ 2152759296 PedWrnIndReq 1;
BA_ "SignalType" SG_ 2152759296 PedWrnIndReq "ENM";
BA_ "SignalLongName" SG_ 2152759296 PedWrnIndReq "Pedestrian Warning Indication Request";
BA_ "GenSigSendType" SG_ 2152759296 FrtRdrFldIO 10;
BA_ "VNSigAllNodes" SG_ 2152759296 FrtRdrFldIO 1;
BA_ "SignalType" SG_ 2152759296 FrtRdrFldIO "BLN";
BA_ "SignalLongName" SG_ 2152759296 FrtRdrFldIO "Front Radar Failed Indication On";
BA_ "GenSigSendType" SG_ 2152759296 FrtCmrFldIO 10;
BA_ "VNSigAllNodes" SG_ 2152759296 FrtCmrFldIO 1;
BA_ "SignalType" SG_ 2152759296 FrtCmrFldIO "BLN";
BA_ "SignalLongName" SG_ 2152759296 FrtCmrFldIO "Front Camera Failed Indication on";
BA_ "GenSigSendType" SG_ 2152759296 FrtEOCMMdlFldIO 10;
BA_ "VNSigAllNodes" SG_ 2152759296 FrtEOCMMdlFldIO 1;
BA_ "SignalType" SG_ 2152759296 FrtEOCMMdlFldIO "BLN";
BA_ "SignalLongName" SG_ 2152759296 FrtEOCMMdlFldIO "Front External Object Calculating Module Failed Indication On";
BA_ "GenSigSendOnInit" SG_ 2152759296 FrtCmrBlckdIO 2;
BA_ "GenSigSendType" SG_ 2152759296 FrtCmrBlckdIO 10;
BA_ "VNSigAllNodes" SG_ 2152759296 FrtCmrBlckdIO 1;
BA_ "SignalType" SG_ 2152759296 FrtCmrBlckdIO "BLN";
BA_ "SignalLongName" SG_ 2152759296 FrtCmrBlckdIO "Front Camera Block Indication On";
BA_ "GenSigSendType" SG_ 2152742912 ShrtRngRdrOffIO 10;
BA_ "VNSigAllNodes" SG_ 2152742912 ShrtRngRdrOffIO 1;
BA_ "SignalType" SG_ 2152742912 ShrtRngRdrOffIO "BLN";
BA_ "SignalLongName" SG_ 2152742912 ShrtRngRdrOffIO "Short Range Radar Off Indication On";
BA_ "GenSigSendType" SG_ 2152742912 RrRdrFldIO 10;
BA_ "VNSigAllNodes" SG_ 2152742912 RrRdrFldIO 1;
BA_ "SignalType" SG_ 2152742912 RrRdrFldIO "BLN";
BA_ "SignalLongName" SG_ 2152742912 RrRdrFldIO "Rear Radar Failed Indication On";
BA_ "GenSigSendOnInit" SG_ 2152742912 RrRdrBlckdIO 2;
BA_ "GenSigSendType" SG_ 2152742912 RrRdrBlckdIO 10;
BA_ "VNSigAllNodes" SG_ 2152742912 RrRdrBlckdIO 1;
BA_ "SignalType" SG_ 2152742912 RrRdrBlckdIO "BLN";
BA_ "SignalLongName" SG_ 2152742912 RrRdrBlckdIO "Rear Radar Blocked Indication On";
BA_ "GenSigSendType" SG_ 2152742912 RrEOCMMdlFldIO 10;
BA_ "VNSigAllNodes" SG_ 2152742912 RrEOCMMdlFldIO 1;
BA_ "SignalType" SG_ 2152742912 RrEOCMMdlFldIO "BLN";
BA_ "SignalLongName" SG_ 2152742912 RrEOCMMdlFldIO "Rear External Object Calculating Module Failed Indication On";
BA_ "VNSigDiagnostic" SG_ 1591 VectraSpcNWMgtD 1;
BA_ "VNSigUnused_4" SG_ 1591 VectraSpcNWMgtD 1;
BA_ "VNSigIntermediate" SG_ 1591 VectraSpcNWMgtD 1;
BA_ "VNSigParkedVehicle" SG_ 1591 VectraSpcNWMgtD 1;
BA_ "VNSigRemoteDiagnostics" SG_ 1591 VectraSpcNWMgtD 1;
BA_ "VNSigAllNodes" SG_ 1591 VectraSpcNWMgtD 1;
BA_ "SignalType" SG_ 1591 VectraSpcNWMgtD "UNM";
BA_ "SignalLongName" SG_ 1591 VectraSpcNWMgtD "Vectra Specific Network Management Data";
BA_ "VNSigDiagnostic" SG_ 1355 DgnInf_LS54B 1;
BA_ "VNSigAllNodes" SG_ 1355 DgnInf_LS54B 1;
BA_ "SignalType" SG_ 1355 DgnInf_LS54B "UNM";
BA_ "SignalLongName" SG_ 1355 DgnInf_LS54B "Diagnostic Information LS54B";
BA_ "VNSigDiagnostic" SG_ 1611 DgnInf 1;
BA_ "GenSigSendType" SG_ 1611 DgnInf 12;
BA_ "GenSigDeltaValue" SG_ 1611 DgnInf 1;
BA_ "VNSigAllNodes" SG_ 1611 DgnInf 1;
BA_ "SignalType" SG_ 1611 DgnInf "UNM";
BA_ "SignalLongName" SG_ 1611 DgnInf "Diagnostic Information";
BA_ "VNSigDiagnostic" SG_ 1603 DgnInf 1;
BA_ "GenSigSendType" SG_ 1603 DgnInf 12;
BA_ "GenSigDeltaValue" SG_ 1603 DgnInf 1;
BA_ "VNSigAllNodes" SG_ 1603 DgnInf 1;
BA_ "SignalType" SG_ 1603 DgnInf "UNM";
BA_ "SignalLongName" SG_ 1603 DgnInf "Diagnostic Information";
BA_ "VNSigDiagnostic" SG_ 1347 DgnInf_LS543 1;
BA_ "VNSigAllNodes" SG_ 1347 DgnInf_LS543 1;
BA_ "SignalType" SG_ 1347 DgnInf_LS543 "UNM";
BA_ "SignalLongName" SG_ 1347 DgnInf_LS543 "Diagnostic Information LS543";
BA_ "GenSigSendType" SG_ 2154995712 HVHtrFldIO 10;
BA_ "VNSigAllNodes" SG_ 2154995712 HVHtrFldIO 1;
BA_ "SignalType" SG_ 2154995712 HVHtrFldIO "BLN";
BA_ "SignalLongName" SG_ 2154995712 HVHtrFldIO "High Voltage Heater Failed Indication On";
BA_ "GenSigSendType" SG_ 2154995712 HVHtrOvrTmpIndOn 10;
BA_ "VNSigAllNodes" SG_ 2154995712 HVHtrOvrTmpIndOn 1;
BA_ "SignalType" SG_ 2154995712 HVHtrOvrTmpIndOn "BLN";
BA_ "SignalLongName" SG_ 2154995712 HVHtrOvrTmpIndOn "High Voltage Heater Over Temperature Indication On";
BA_ "GenSigSendType" SG_ 2150817792 ImpTimeToMaxDeltaVel 12;
BA_ "GenSigDeltaValue" SG_ 2150817792 ImpTimeToMaxDeltaVel 1;
BA_ "VNSigAllNodes" SG_ 2150817792 ImpTimeToMaxDeltaVel 1;
BA_ "SignalType" SG_ 2150817792 ImpTimeToMaxDeltaVel "UNM";
BA_ "SignalLongName" SG_ 2150817792 ImpTimeToMaxDeltaVel "Impact Time to Maximum Delta Velocity";
BA_ "GenSigSendType" SG_ 2150817792 ImpMaxLongDeltaVel 12;
BA_ "GenSigDeltaValue" SG_ 2150817792 ImpMaxLongDeltaVel 1;
BA_ "VNSigAllNodes" SG_ 2150817792 ImpMaxLongDeltaVel 1;
BA_ "SignalType" SG_ 2150817792 ImpMaxLongDeltaVel "SNM";
BA_ "SignalLongName" SG_ 2150817792 ImpMaxLongDeltaVel "Impact Maximum Longitudinal Delta Velocity";
BA_ "GenSigSendType" SG_ 2150817792 ImpMaxLateralDeltaVel 12;
BA_ "GenSigDeltaValue" SG_ 2150817792 ImpMaxLateralDeltaVel 1;
BA_ "VNSigAllNodes" SG_ 2150817792 ImpMaxLateralDeltaVel 1;
BA_ "SignalType" SG_ 2150817792 ImpMaxLateralDeltaVel "SNM";
BA_ "SignalLongName" SG_ 2150817792 ImpMaxLateralDeltaVel "Impact Maximum Lateral Delta Velocity";
BA_ "VNSigDiagnostic" SG_ 1621 DgnInf 1;
BA_ "GenSigSendType" SG_ 1621 DgnInf 12;
BA_ "GenSigDeltaValue" SG_ 1621 DgnInf 1;
BA_ "VNSigAllNodes" SG_ 1621 DgnInf 1;
BA_ "SignalType" SG_ 1621 DgnInf "UNM";
BA_ "SignalLongName" SG_ 1621 DgnInf "Diagnostic Information";
BA_ "VNSigDiagnostic" SG_ 1365 DgnInf_LS555 1;
BA_ "VNSigAllNodes" SG_ 1365 DgnInf_LS555 1;
BA_ "SignalType" SG_ 1365 DgnInf_LS555 "UNM";
BA_ "SignalLongName" SG_ 1365 DgnInf_LS555 "Diagnostic Information LS555";
BA_ "GenSigSendType" SG_ 2150809600 IDVS12_Axis2 12;
BA_ "GenSigDeltaValue" SG_ 2150809600 IDVS12_Axis2 1;
BA_ "VNSigAllNodes" SG_ 2150809600 IDVS12_Axis2 1;
BA_ "SignalType" SG_ 2150809600 IDVS12_Axis2 "SNM";
BA_ "PacketOrder" SG_ 2150809600 IDVS12_Axis2 2;
BA_ "SignalLongName" SG_ 2150809600 IDVS12_Axis2 "Impact Delta Velocity Sample 12 : Axis 2";
BA_ "GenSigSendType" SG_ 2150809600 IDVS12_Axis1 12;
BA_ "GenSigDeltaValue" SG_ 2150809600 IDVS12_Axis1 1;
BA_ "VNSigAllNodes" SG_ 2150809600 IDVS12_Axis1 1;
BA_ "SignalType" SG_ 2150809600 IDVS12_Axis1 "SNM";
BA_ "PacketOrder" SG_ 2150809600 IDVS12_Axis1 1;
BA_ "SignalLongName" SG_ 2150809600 IDVS12_Axis1 "Impact Delta Velocity Sample 12 : Axis 1";
BA_ "GenSigSendType" SG_ 2150809600 IDVS13_Axis2 12;
BA_ "GenSigDeltaValue" SG_ 2150809600 IDVS13_Axis2 1;
BA_ "VNSigAllNodes" SG_ 2150809600 IDVS13_Axis2 1;
BA_ "SignalType" SG_ 2150809600 IDVS13_Axis2 "SNM";
BA_ "PacketOrder" SG_ 2150809600 IDVS13_Axis2 2;
BA_ "SignalLongName" SG_ 2150809600 IDVS13_Axis2 "Impact Delta Velocity Sample 13 : Axis 2";
BA_ "GenSigSendType" SG_ 2150809600 IDVS13_Axis1 12;
BA_ "GenSigDeltaValue" SG_ 2150809600 IDVS13_Axis1 1;
BA_ "VNSigAllNodes" SG_ 2150809600 IDVS13_Axis1 1;
BA_ "SignalType" SG_ 2150809600 IDVS13_Axis1 "SNM";
BA_ "PacketOrder" SG_ 2150809600 IDVS13_Axis1 1;
BA_ "SignalLongName" SG_ 2150809600 IDVS13_Axis1 "Impact Delta Velocity Sample 13 : Axis 1";
BA_ "GenSigSendType" SG_ 2150809600 IDVS14_Axis2 12;
BA_ "GenSigDeltaValue" SG_ 2150809600 IDVS14_Axis2 1;
BA_ "VNSigAllNodes" SG_ 2150809600 IDVS14_Axis2 1;
BA_ "SignalType" SG_ 2150809600 IDVS14_Axis2 "SNM";
BA_ "PacketOrder" SG_ 2150809600 IDVS14_Axis2 2;
BA_ "SignalLongName" SG_ 2150809600 IDVS14_Axis2 "Impact Delta Velocity Sample 14 : Axis 2";
BA_ "GenSigSendType" SG_ 2150809600 IDVS14_Axis1 12;
BA_ "GenSigDeltaValue" SG_ 2150809600 IDVS14_Axis1 1;
BA_ "VNSigAllNodes" SG_ 2150809600 IDVS14_Axis1 1;
BA_ "SignalType" SG_ 2150809600 IDVS14_Axis1 "SNM";
BA_ "PacketOrder" SG_ 2150809600 IDVS14_Axis1 1;
BA_ "SignalLongName" SG_ 2150809600 IDVS14_Axis1 "Impact Delta Velocity Sample 14 : Axis 1";
BA_ "GenSigSendType" SG_ 2150809600 IDVS15_Axis2 12;
BA_ "GenSigDeltaValue" SG_ 2150809600 IDVS15_Axis2 1;
BA_ "VNSigAllNodes" SG_ 2150809600 IDVS15_Axis2 1;
BA_ "SignalType" SG_ 2150809600 IDVS15_Axis2 "SNM";
BA_ "PacketOrder" SG_ 2150809600 IDVS15_Axis2 2;
BA_ "SignalLongName" SG_ 2150809600 IDVS15_Axis2 "Impact Delta Velocity Sample 15 : Axis 2";
BA_ "GenSigSendType" SG_ 2150809600 IDVS15_Axis1 12;
BA_ "GenSigDeltaValue" SG_ 2150809600 IDVS15_Axis1 1;
BA_ "VNSigAllNodes" SG_ 2150809600 IDVS15_Axis1 1;
BA_ "SignalType" SG_ 2150809600 IDVS15_Axis1 "SNM";
BA_ "PacketOrder" SG_ 2150809600 IDVS15_Axis1 1;
BA_ "SignalLongName" SG_ 2150809600 IDVS15_Axis1 "Impact Delta Velocity Sample 15 : Axis 1";
BA_ "GenSigSendType" SG_ 2150793216 IDVS4_Axis2 12;
BA_ "GenSigDeltaValue" SG_ 2150793216 IDVS4_Axis2 1;
BA_ "VNSigAllNodes" SG_ 2150793216 IDVS4_Axis2 1;
BA_ "SignalType" SG_ 2150793216 IDVS4_Axis2 "SNM";
BA_ "PacketOrder" SG_ 2150793216 IDVS4_Axis2 2;
BA_ "SignalLongName" SG_ 2150793216 IDVS4_Axis2 "Impact Delta Velocity Sample 4 : Axis 2";
BA_ "GenSigSendType" SG_ 2150793216 IDVS4_Axis1 12;
BA_ "GenSigDeltaValue" SG_ 2150793216 IDVS4_Axis1 1;
BA_ "VNSigAllNodes" SG_ 2150793216 IDVS4_Axis1 1;
BA_ "SignalType" SG_ 2150793216 IDVS4_Axis1 "SNM";
BA_ "PacketOrder" SG_ 2150793216 IDVS4_Axis1 1;
BA_ "SignalLongName" SG_ 2150793216 IDVS4_Axis1 "Impact Delta Velocity Sample 4 : Axis 1";
BA_ "GenSigSendType" SG_ 2150793216 IDVS5_Axis2 12;
BA_ "GenSigDeltaValue" SG_ 2150793216 IDVS5_Axis2 1;
BA_ "VNSigAllNodes" SG_ 2150793216 IDVS5_Axis2 1;
BA_ "SignalType" SG_ 2150793216 IDVS5_Axis2 "SNM";
BA_ "PacketOrder" SG_ 2150793216 IDVS5_Axis2 2;
BA_ "SignalLongName" SG_ 2150793216 IDVS5_Axis2 "Impact Delta Velocity Sample 5 : Axis 2";
BA_ "GenSigSendType" SG_ 2150793216 IDVS5_Axis1 12;
BA_ "GenSigDeltaValue" SG_ 2150793216 IDVS5_Axis1 1;
BA_ "VNSigAllNodes" SG_ 2150793216 IDVS5_Axis1 1;
BA_ "SignalType" SG_ 2150793216 IDVS5_Axis1 "SNM";
BA_ "PacketOrder" SG_ 2150793216 IDVS5_Axis1 1;
BA_ "SignalLongName" SG_ 2150793216 IDVS5_Axis1 "Impact Delta Velocity Sample 5 : Axis 1";
BA_ "GenSigSendType" SG_ 2150793216 IDVS6_Axis2 12;
BA_ "GenSigDeltaValue" SG_ 2150793216 IDVS6_Axis2 1;
BA_ "VNSigAllNodes" SG_ 2150793216 IDVS6_Axis2 1;
BA_ "SignalType" SG_ 2150793216 IDVS6_Axis2 "SNM";
BA_ "PacketOrder" SG_ 2150793216 IDVS6_Axis2 2;
BA_ "SignalLongName" SG_ 2150793216 IDVS6_Axis2 "Impact Delta Velocity Sample 6 : Axis 2";
BA_ "GenSigSendType" SG_ 2150793216 IDVS6_Axis1 12;
BA_ "GenSigDeltaValue" SG_ 2150793216 IDVS6_Axis1 1;
BA_ "VNSigAllNodes" SG_ 2150793216 IDVS6_Axis1 1;
BA_ "SignalType" SG_ 2150793216 IDVS6_Axis1 "SNM";
BA_ "PacketOrder" SG_ 2150793216 IDVS6_Axis1 1;
BA_ "SignalLongName" SG_ 2150793216 IDVS6_Axis1 "Impact Delta Velocity Sample 6 : Axis 1";
BA_ "GenSigSendType" SG_ 2150793216 IDVS7_Axis2 12;
BA_ "GenSigDeltaValue" SG_ 2150793216 IDVS7_Axis2 1;
BA_ "VNSigAllNodes" SG_ 2150793216 IDVS7_Axis2 1;
BA_ "SignalType" SG_ 2150793216 IDVS7_Axis2 "SNM";
BA_ "PacketOrder" SG_ 2150793216 IDVS7_Axis2 2;
BA_ "SignalLongName" SG_ 2150793216 IDVS7_Axis2 "Impact Delta Velocity Sample 7 : Axis 2";
BA_ "GenSigSendType" SG_ 2150793216 IDVS7_Axis1 12;
BA_ "GenSigDeltaValue" SG_ 2150793216 IDVS7_Axis1 1;
BA_ "VNSigAllNodes" SG_ 2150793216 IDVS7_Axis1 1;
BA_ "SignalType" SG_ 2150793216 IDVS7_Axis1 "SNM";
BA_ "PacketOrder" SG_ 2150793216 IDVS7_Axis1 1;
BA_ "SignalLongName" SG_ 2150793216 IDVS7_Axis1 "Impact Delta Velocity Sample 7 : Axis 1";
BA_ "GenSigSendType" SG_ 2150801408 IDVS10_Axis2 12;
BA_ "GenSigDeltaValue" SG_ 2150801408 IDVS10_Axis2 1;
BA_ "VNSigAllNodes" SG_ 2150801408 IDVS10_Axis2 1;
BA_ "SignalType" SG_ 2150801408 IDVS10_Axis2 "SNM";
BA_ "PacketOrder" SG_ 2150801408 IDVS10_Axis2 2;
BA_ "SignalLongName" SG_ 2150801408 IDVS10_Axis2 "Impact Delta Velocity Sample 10 : Axis 2";
BA_ "GenSigSendType" SG_ 2150801408 IDVS10_Axis1 12;
BA_ "GenSigDeltaValue" SG_ 2150801408 IDVS10_Axis1 1;
BA_ "VNSigAllNodes" SG_ 2150801408 IDVS10_Axis1 1;
BA_ "SignalType" SG_ 2150801408 IDVS10_Axis1 "SNM";
BA_ "PacketOrder" SG_ 2150801408 IDVS10_Axis1 1;
BA_ "SignalLongName" SG_ 2150801408 IDVS10_Axis1 "Impact Delta Velocity Sample 10 : Axis 1";
BA_ "GenSigSendType" SG_ 2150801408 IDVS11_Axis2 12;
BA_ "GenSigDeltaValue" SG_ 2150801408 IDVS11_Axis2 1;
BA_ "VNSigAllNodes" SG_ 2150801408 IDVS11_Axis2 1;
BA_ "SignalType" SG_ 2150801408 IDVS11_Axis2 "SNM";
BA_ "PacketOrder" SG_ 2150801408 IDVS11_Axis2 2;
BA_ "SignalLongName" SG_ 2150801408 IDVS11_Axis2 "Impact Delta Velocity Sample 11 : Axis 2";
BA_ "GenSigSendType" SG_ 2150801408 IDVS11_Axis1 12;
BA_ "GenSigDeltaValue" SG_ 2150801408 IDVS11_Axis1 1;
BA_ "VNSigAllNodes" SG_ 2150801408 IDVS11_Axis1 1;
BA_ "SignalType" SG_ 2150801408 IDVS11_Axis1 "SNM";
BA_ "PacketOrder" SG_ 2150801408 IDVS11_Axis1 1;
BA_ "SignalLongName" SG_ 2150801408 IDVS11_Axis1 "Impact Delta Velocity Sample 11 : Axis 1";
BA_ "GenSigSendType" SG_ 2150801408 IDVS8_Axis2 12;
BA_ "GenSigDeltaValue" SG_ 2150801408 IDVS8_Axis2 1;
BA_ "VNSigAllNodes" SG_ 2150801408 IDVS8_Axis2 1;
BA_ "SignalType" SG_ 2150801408 IDVS8_Axis2 "SNM";
BA_ "PacketOrder" SG_ 2150801408 IDVS8_Axis2 2;
BA_ "SignalLongName" SG_ 2150801408 IDVS8_Axis2 "Impact Delta Velocity Sample 8 : Axis 2";
BA_ "GenSigSendType" SG_ 2150801408 IDVS8_Axis1 12;
BA_ "GenSigDeltaValue" SG_ 2150801408 IDVS8_Axis1 1;
BA_ "VNSigAllNodes" SG_ 2150801408 IDVS8_Axis1 1;
BA_ "SignalType" SG_ 2150801408 IDVS8_Axis1 "SNM";
BA_ "PacketOrder" SG_ 2150801408 IDVS8_Axis1 1;
BA_ "SignalLongName" SG_ 2150801408 IDVS8_Axis1 "Impact Delta Velocity Sample 8 : Axis 1";
BA_ "GenSigSendType" SG_ 2150801408 IDVS9_Axis2 12;
BA_ "GenSigDeltaValue" SG_ 2150801408 IDVS9_Axis2 1;
BA_ "VNSigAllNodes" SG_ 2150801408 IDVS9_Axis2 1;
BA_ "SignalType" SG_ 2150801408 IDVS9_Axis2 "SNM";
BA_ "PacketOrder" SG_ 2150801408 IDVS9_Axis2 2;
BA_ "SignalLongName" SG_ 2150801408 IDVS9_Axis2 "Impact Delta Velocity Sample 9 : Axis 2";
BA_ "GenSigSendType" SG_ 2150801408 IDVS9_Axis1 12;
BA_ "GenSigDeltaValue" SG_ 2150801408 IDVS9_Axis1 1;
BA_ "VNSigAllNodes" SG_ 2150801408 IDVS9_Axis1 1;
BA_ "SignalType" SG_ 2150801408 IDVS9_Axis1 "SNM";
BA_ "PacketOrder" SG_ 2150801408 IDVS9_Axis1 1;
BA_ "SignalLongName" SG_ 2150801408 IDVS9_Axis1 "Impact Delta Velocity Sample 9 : Axis 1";
BA_ "GenSigSendType" SG_ 2150785024 AirbgAccelOrien 12;
BA_ "GenSigDeltaValue" SG_ 2150785024 AirbgAccelOrien 1;
BA_ "VNSigAllNodes" SG_ 2150785024 AirbgAccelOrien 1;
BA_ "SignalType" SG_ 2150785024 AirbgAccelOrien "UNM";
BA_ "SignalLongName" SG_ 2150785024 AirbgAccelOrien "Airbag Accelerometer Orientation";
BA_ "GenSigSendType" SG_ 2150785024 IDVS1_Axis2 12;
BA_ "GenSigDeltaValue" SG_ 2150785024 IDVS1_Axis2 1;
BA_ "VNSigAllNodes" SG_ 2150785024 IDVS1_Axis2 1;
BA_ "SignalType" SG_ 2150785024 IDVS1_Axis2 "SNM";
BA_ "PacketOrder" SG_ 2150785024 IDVS1_Axis2 2;
BA_ "SignalLongName" SG_ 2150785024 IDVS1_Axis2 "Impact Delta Velocity Sample 1 : Axis 2";
BA_ "GenSigSendType" SG_ 2150785024 IDVS1_Axis1 12;
BA_ "GenSigDeltaValue" SG_ 2150785024 IDVS1_Axis1 1;
BA_ "VNSigAllNodes" SG_ 2150785024 IDVS1_Axis1 1;
BA_ "SignalType" SG_ 2150785024 IDVS1_Axis1 "SNM";
BA_ "PacketOrder" SG_ 2150785024 IDVS1_Axis1 1;
BA_ "SignalLongName" SG_ 2150785024 IDVS1_Axis1 "Impact Delta Velocity Sample 1 : Axis 1";
BA_ "GenSigSendType" SG_ 2150785024 IDVS2_Axis2 12;
BA_ "GenSigDeltaValue" SG_ 2150785024 IDVS2_Axis2 1;
BA_ "VNSigAllNodes" SG_ 2150785024 IDVS2_Axis2 1;
BA_ "SignalType" SG_ 2150785024 IDVS2_Axis2 "SNM";
BA_ "PacketOrder" SG_ 2150785024 IDVS2_Axis2 2;
BA_ "SignalLongName" SG_ 2150785024 IDVS2_Axis2 "Impact Delta Velocity Sample 2 : Axis 2";
BA_ "GenSigSendType" SG_ 2150785024 IDVS2_Axis1 12;
BA_ "GenSigDeltaValue" SG_ 2150785024 IDVS2_Axis1 1;
BA_ "VNSigAllNodes" SG_ 2150785024 IDVS2_Axis1 1;
BA_ "SignalType" SG_ 2150785024 IDVS2_Axis1 "SNM";
BA_ "PacketOrder" SG_ 2150785024 IDVS2_Axis1 1;
BA_ "SignalLongName" SG_ 2150785024 IDVS2_Axis1 "Impact Delta Velocity Sample 2 : Axis 1";
BA_ "GenSigSendType" SG_ 2150785024 IDVS3_Axis2 12;
BA_ "GenSigDeltaValue" SG_ 2150785024 IDVS3_Axis2 1;
BA_ "VNSigAllNodes" SG_ 2150785024 IDVS3_Axis2 1;
BA_ "SignalType" SG_ 2150785024 IDVS3_Axis2 "SNM";
BA_ "PacketOrder" SG_ 2150785024 IDVS3_Axis2 2;
BA_ "SignalLongName" SG_ 2150785024 IDVS3_Axis2 "Impact Delta Velocity Sample 3 : Axis 2";
BA_ "GenSigSendType" SG_ 2150785024 IDVS3_Axis1 12;
BA_ "GenSigDeltaValue" SG_ 2150785024 IDVS3_Axis1 1;
BA_ "VNSigAllNodes" SG_ 2150785024 IDVS3_Axis1 1;
BA_ "SignalType" SG_ 2150785024 IDVS3_Axis1 "SNM";
BA_ "PacketOrder" SG_ 2150785024 IDVS3_Axis1 1;
BA_ "SignalLongName" SG_ 2150785024 IDVS3_Axis1 "Impact Delta Velocity Sample 3 : Axis 1";
BA_ "GenSigSendType" SG_ 2150785024 ImpDltVlcScal 12;
BA_ "GenSigDeltaValue" SG_ 2150785024 ImpDltVlcScal 1;
BA_ "VNSigAllNodes" SG_ 2150785024 ImpDltVlcScal 1;
BA_ "SignalType" SG_ 2150785024 ImpDltVlcScal "UNM";
BA_ "SignalLongName" SG_ 2150785024 ImpDltVlcScal "Impact Delta Velocity Scaling";
BA_ "GenSigSendType" SG_ 2150825984 PdstIntdProtSysDplyd 10;
BA_ "VNSigAllNodes" SG_ 2150825984 PdstIntdProtSysDplyd 1;
BA_ "SignalType" SG_ 2150825984 PdstIntdProtSysDplyd "BLN";
BA_ "SignalLongName" SG_ 2150825984 PdstIntdProtSysDplyd "Pedestrian Integrated Protection System Deployed";
BA_ "GenSigSendType" SG_ 2150825984 PdstIntdProtSysDsbld 10;
BA_ "VNSigAllNodes" SG_ 2150825984 PdstIntdProtSysDsbld 1;
BA_ "SignalType" SG_ 2150825984 PdstIntdProtSysDsbld "BLN";
BA_ "SignalLongName" SG_ 2150825984 PdstIntdProtSysDsbld "Pedestrian Integrated Protection System Disabled";
BA_ "GenSigSendType" SG_ 2150825984 SrvIntdPdstProtSysIO 10;
BA_ "VNSigAllNodes" SG_ 2150825984 SrvIntdPdstProtSysIO 1;
BA_ "SignalType" SG_ 2150825984 SrvIntdPdstProtSysIO "BLN";
BA_ "SignalLongName" SG_ 2150825984 SrvIntdPdstProtSysIO "Service Integrated Pedestrian Protection System Indication On";
BA_ "GenSigSendType" SG_ 2150825984 FstnThrdRwRtPsStbtInR 10;
BA_ "VNSigAllNodes" SG_ 2150825984 FstnThrdRwRtPsStbtInR 1;
BA_ "SignalType" SG_ 2150825984 FstnThrdRwRtPsStbtInR "ENM";
BA_ "SignalLongName" SG_ 2150825984 FstnThrdRwRtPsStbtInR "Fasten Third Row Right Passenger Seatbelt Indication Request";
BA_ "GenSigSendType" SG_ 2150825984 FstnThrdRwLtPsStbtInR 10;
BA_ "VNSigAllNodes" SG_ 2150825984 FstnThrdRwLtPsStbtInR 1;
BA_ "SignalType" SG_ 2150825984 FstnThrdRwLtPsStbtInR "ENM";
BA_ "SignalLongName" SG_ 2150825984 FstnThrdRwLtPsStbtInR "Fasten Third Row Left Passenger Seatbelt Indication Request";
BA_ "GenSigSendType" SG_ 2150825984 FstnThrdRwCtPsStbtInR 10;
BA_ "VNSigAllNodes" SG_ 2150825984 FstnThrdRwCtPsStbtInR 1;
BA_ "SignalType" SG_ 2150825984 FstnThrdRwCtPsStbtInR "ENM";
BA_ "SignalLongName" SG_ 2150825984 FstnThrdRwCtPsStbtInR "Fasten Third Row Center Passenger Seatbelt Indication Request";
BA_ "GenSigSendOnInit" SG_ 2150825984 FPSIC_IndPer 1;
BA_ "GenSigSendType" SG_ 2150825984 FPSIC_IndPer 10;
BA_ "VNSigAllNodes" SG_ 2150825984 FPSIC_IndPer 1;
BA_ "SignalType" SG_ 2150825984 FPSIC_IndPer "ENM";
BA_ "PacketOrder" SG_ 2150825984 FPSIC_IndPer 3;
BA_ "SignalLongName" SG_ 2150825984 FPSIC_IndPer "Fasten Passenger Seatbelt Indication Control : Indication Period";
BA_ "GenSigStartValue" SG_ 2150825984 FPSIC_IndPer 3;
BA_ "GenSigSendOnInit" SG_ 2150825984 FPSIC_IO 1;
BA_ "GenSigSendType" SG_ 2150825984 FPSIC_IO 10;
BA_ "VNSigAllNodes" SG_ 2150825984 FPSIC_IO 1;
BA_ "SignalType" SG_ 2150825984 FPSIC_IO "BLN";
BA_ "PacketOrder" SG_ 2150825984 FPSIC_IO 1;
BA_ "SignalLongName" SG_ 2150825984 FPSIC_IO "Fasten Passenger Seatbelt Indication Control : Indication On";
BA_ "GenSigSendOnInit" SG_ 2150825984 FPSIC_IndDtCyc 1;
BA_ "GenSigSendType" SG_ 2150825984 FPSIC_IndDtCyc 12;
BA_ "GenSigDeltaValue" SG_ 2150825984 FPSIC_IndDtCyc 1;
BA_ "VNSigAllNodes" SG_ 2150825984 FPSIC_IndDtCyc 1;
BA_ "SignalType" SG_ 2150825984 FPSIC_IndDtCyc "UNM";
BA_ "PacketOrder" SG_ 2150825984 FPSIC_IndDtCyc 2;
BA_ "SignalLongName" SG_ 2150825984 FPSIC_IndDtCyc "Fasten Passenger Seatbelt Indication Control : Indication Duty Cycle";
BA_ "GenSigStartValue" SG_ 2150825984 FPSIC_IndDtCyc 7;
BA_ "GenSigSendOnInit" SG_ 2150825984 FDSIC_IndPer 1;
BA_ "GenSigSendType" SG_ 2150825984 FDSIC_IndPer 10;
BA_ "VNSigAllNodes" SG_ 2150825984 FDSIC_IndPer 1;
BA_ "SignalType" SG_ 2150825984 FDSIC_IndPer "ENM";
BA_ "PacketOrder" SG_ 2150825984 FDSIC_IndPer 3;
BA_ "SignalLongName" SG_ 2150825984 FDSIC_IndPer "Fasten Driver Seatbelt Indication Control : Indication Period";
BA_ "GenSigStartValue" SG_ 2150825984 FDSIC_IndPer 3;
BA_ "GenSigSendOnInit" SG_ 2150825984 FDSIC_IO 1;
BA_ "GenSigSendType" SG_ 2150825984 FDSIC_IO 10;
BA_ "VNSigAllNodes" SG_ 2150825984 FDSIC_IO 1;
BA_ "SignalType" SG_ 2150825984 FDSIC_IO "BLN";
BA_ "PacketOrder" SG_ 2150825984 FDSIC_IO 1;
BA_ "SignalLongName" SG_ 2150825984 FDSIC_IO "Fasten Driver Seatbelt Indication Control : Indication On";
BA_ "GenSigSendOnInit" SG_ 2150825984 FDSIC_IndDC 1;
BA_ "GenSigSendType" SG_ 2150825984 FDSIC_IndDC 12;
BA_ "GenSigDeltaValue" SG_ 2150825984 FDSIC_IndDC 1;
BA_ "VNSigAllNodes" SG_ 2150825984 FDSIC_IndDC 1;
BA_ "SignalType" SG_ 2150825984 FDSIC_IndDC "UNM";
BA_ "PacketOrder" SG_ 2150825984 FDSIC_IndDC 2;
BA_ "SignalLongName" SG_ 2150825984 FDSIC_IndDC "Fasten Driver Seatbelt Indication Control : Indication Duty Cycle";
BA_ "GenSigStartValue" SG_ 2150825984 FDSIC_IndDC 7;
BA_ "GenSigSendOnInit" SG_ 2150825984 AirbgFldIO 1;
BA_ "GenSigSendType" SG_ 2150825984 AirbgFldIO 10;
BA_ "VNSigAllNodes" SG_ 2150825984 AirbgFldIO 1;
BA_ "SignalType" SG_ 2150825984 AirbgFldIO "BLN";
BA_ "SignalLongName" SG_ 2150825984 AirbgFldIO "Airbag Failed Indication On";
BA_ "GenSigSendType" SG_ 2150825984 SndRwStbltRdIndMd 10;
BA_ "VNSigAllNodes" SG_ 2150825984 SndRwStbltRdIndMd 1;
BA_ "SignalType" SG_ 2150825984 SndRwStbltRdIndMd "ENM";
BA_ "SignalLongName" SG_ 2150825984 SndRwStbltRdIndMd "Second Row Seatbelt Reminder Indication Mode";
BA_ "GenSigSendType" SG_ 2150825984 AirbgICIndPer 10;
BA_ "VNSigAllNodes" SG_ 2150825984 AirbgICIndPer 1;
BA_ "SignalType" SG_ 2150825984 AirbgICIndPer "ENM";
BA_ "PacketOrder" SG_ 2150825984 AirbgICIndPer 3;
BA_ "SignalLongName" SG_ 2150825984 AirbgICIndPer "Airbag Indication Control : Indication Period";
BA_ "GenSigSendType" SG_ 2150825984 AirbgICDutCyc 12;
BA_ "GenSigDeltaValue" SG_ 2150825984 AirbgICDutCyc 1;
BA_ "VNSigAllNodes" SG_ 2150825984 AirbgICDutCyc 1;
BA_ "SignalType" SG_ 2150825984 AirbgICDutCyc "UNM";
BA_ "PacketOrder" SG_ 2150825984 AirbgICDutCyc 2;
BA_ "SignalLongName" SG_ 2150825984 AirbgICDutCyc "Airbag Indication Control : Indication Duty Cycle";
BA_ "GenSigSendType" SG_ 2150825984 AirbgICIO 10;
BA_ "VNSigAllNodes" SG_ 2150825984 AirbgICIO 1;
BA_ "SignalType" SG_ 2150825984 AirbgICIO "BLN";
BA_ "PacketOrder" SG_ 2150825984 AirbgICIO 1;
BA_ "SignalLongName" SG_ 2150825984 AirbgICIO "Airbag Indication Control : Indication On";
BA_ "GenSigSendType" SG_ 2150825984 FstnSndRwRtPsStbtInR 10;
BA_ "VNSigAllNodes" SG_ 2150825984 FstnSndRwRtPsStbtInR 1;
BA_ "SignalType" SG_ 2150825984 FstnSndRwRtPsStbtInR "ENM";
BA_ "SignalLongName" SG_ 2150825984 FstnSndRwRtPsStbtInR "Fasten Second Row Right Passenger Seatbelt Indication Request";
BA_ "GenSigSendType" SG_ 2150825984 FstnSndRwLtPsStbtInR 10;
BA_ "VNSigAllNodes" SG_ 2150825984 FstnSndRwLtPsStbtInR 1;
BA_ "SignalType" SG_ 2150825984 FstnSndRwLtPsStbtInR "ENM";
BA_ "SignalLongName" SG_ 2150825984 FstnSndRwLtPsStbtInR "Fasten Second Row Left Passenger Seatbelt Indication Request";
BA_ "GenSigSendType" SG_ 2150825984 FstnSndRwCtPsStbtInR 10;
BA_ "VNSigAllNodes" SG_ 2150825984 FstnSndRwCtPsStbtInR 1;
BA_ "SignalType" SG_ 2150825984 FstnSndRwCtPsStbtInR "ENM";
BA_ "SignalLongName" SG_ 2150825984 FstnSndRwCtPsStbtInR "Fasten Second Row Center Passenger Seatbelt Indication Request";
BA_ "GenSigSendOnInit" SG_ 2150825984 FsnDrStbAuxIR 1;
BA_ "GenSigSendType" SG_ 2150825984 FsnDrStbAuxIR 10;
BA_ "VNSigAllNodes" SG_ 2150825984 FsnDrStbAuxIR 1;
BA_ "SignalType" SG_ 2150825984 FsnDrStbAuxIR "ENM";
BA_ "SignalLongName" SG_ 2150825984 FsnDrStbAuxIR "Fasten Driver Seatbelt Auxiliary Indication Request";
BA_ "GenSigSendOnInit" SG_ 2150825984 FsnPsStbAuxIR 1;
BA_ "GenSigSendType" SG_ 2150825984 FsnPsStbAuxIR 10;
BA_ "VNSigAllNodes" SG_ 2150825984 FsnPsStbAuxIR 1;
BA_ "SignalType" SG_ 2150825984 FsnPsStbAuxIR "ENM";
BA_ "SignalLongName" SG_ 2150825984 FsnPsStbAuxIR "Fasten Passenger Seatbelt Auxiliary Indication Request";
BA_ "VNSigDiagnostic" SG_ 1351 DgnInf_LS547 1;
BA_ "VNSigAllNodes" SG_ 1351 DgnInf_LS547 1;
BA_ "SignalType" SG_ 1351 DgnInf_LS547 "UNM";
BA_ "SignalLongName" SG_ 1351 DgnInf_LS547 "Diagnostic Information LS547";
BA_ "VNSigDiagnostic" SG_ 1607 DgnInf 1;
BA_ "GenSigSendType" SG_ 1607 DgnInf 12;
BA_ "GenSigDeltaValue" SG_ 1607 DgnInf 1;
BA_ "VNSigAllNodes" SG_ 1607 DgnInf 1;
BA_ "SignalType" SG_ 1607 DgnInf "UNM";
BA_ "SignalLongName" SG_ 1607 DgnInf "Diagnostic Information";
BA_ "VNSigDiagnostic" SG_ 1602 DgnInf 1;
BA_ "GenSigSendType" SG_ 1602 DgnInf 12;
BA_ "GenSigDeltaValue" SG_ 1602 DgnInf 1;
BA_ "VNSigAllNodes" SG_ 1602 DgnInf 1;
BA_ "SignalType" SG_ 1602 DgnInf "UNM";
BA_ "SignalLongName" SG_ 1602 DgnInf "Diagnostic Information";
BA_ "VNSigDiagnostic" SG_ 1346 DgnInf_LS542 1;
BA_ "VNSigAllNodes" SG_ 1346 DgnInf_LS542 1;
BA_ "SignalType" SG_ 1346 DgnInf_LS542 "UNM";
BA_ "SignalLongName" SG_ 1346 DgnInf_LS542 "Diagnostic Information LS542";
BA_ "VNSigDiagnostic" SG_ 1361 DgnInf_LS551 1;
BA_ "VNSigAllNodes" SG_ 1361 DgnInf_LS551 1;
BA_ "SignalType" SG_ 1361 DgnInf_LS551 "UNM";
BA_ "SignalLongName" SG_ 1361 DgnInf_LS551 "Diagnostic Information LS551";
BA_ "VNSigDiagnostic" SG_ 1617 DgnInf 1;
BA_ "GenSigSendType" SG_ 1617 DgnInf 12;
BA_ "GenSigDeltaValue" SG_ 1617 DgnInf 1;
BA_ "VNSigAllNodes" SG_ 1617 DgnInf 1;
BA_ "SignalType" SG_ 1617 DgnInf "UNM";
BA_ "SignalLongName" SG_ 1617 DgnInf "Diagnostic Information";
BA_ "VNSigDiagnostic" SG_ 1373 DgnInf_LS55D 1;
BA_ "VNSigAllNodes" SG_ 1373 DgnInf_LS55D 1;
BA_ "SignalType" SG_ 1373 DgnInf_LS55D "UNM";
BA_ "SignalLongName" SG_ 1373 DgnInf_LS55D "Diagnostic Information LS55D";
BA_ "VNSigDiagnostic" SG_ 1629 DgnInf 1;
BA_ "GenSigSendType" SG_ 1629 DgnInf 12;
BA_ "GenSigDeltaValue" SG_ 1629 DgnInf 1;
BA_ "VNSigAllNodes" SG_ 1629 DgnInf 1;
BA_ "SignalType" SG_ 1629 DgnInf "UNM";
BA_ "SignalLongName" SG_ 1629 DgnInf "Diagnostic Information";
BA_ "VNSigDiagnostic" SG_ 602 DgnInf 1;
BA_ "GenSigSendType" SG_ 602 DgnInf 12;
BA_ "GenSigDeltaValue" SG_ 602 DgnInf 1;
BA_ "VNSigAllNodes" SG_ 602 DgnInf 1;
BA_ "SignalType" SG_ 602 DgnInf "UNM";
BA_ "SignalLongName" SG_ 602 DgnInf "Diagnostic Information";
BA_ "VNSigDiagnostic" SG_ 164 DgnInf 1;
BA_ "GenSigSendType" SG_ 164 DgnInf 12;
BA_ "GenSigDeltaValue" SG_ 164 DgnInf 1;
BA_ "VNSigAllNodes" SG_ 164 DgnInf 1;
BA_ "SignalType" SG_ 164 DgnInf "UNM";
BA_ "SignalLongName" SG_ 164 DgnInf "Diagnostic Information";
BA_ "VNSigDiagnostic" SG_ 104 DgnInf 1;
BA_ "GenSigSendType" SG_ 104 DgnInf 12;
BA_ "GenSigDeltaValue" SG_ 104 DgnInf 1;
BA_ "VNSigAllNodes" SG_ 104 DgnInf 1;
BA_ "SignalType" SG_ 104 DgnInf "UNM";
BA_ "SignalLongName" SG_ 104 DgnInf "Diagnostic Information";
BA_ "VNSigDiagnostic" SG_ 88 DgnInf 1;
BA_ "GenSigSendType" SG_ 88 DgnInf 12;
BA_ "GenSigDeltaValue" SG_ 88 DgnInf 1;
BA_ "VNSigAllNodes" SG_ 88 DgnInf 1;
BA_ "SignalType" SG_ 88 DgnInf "UNM";
BA_ "SignalLongName" SG_ 88 DgnInf "Diagnostic Information";
BA_ "VNSigDiagnostic" SG_ 168 DgnInf 1;
BA_ "GenSigSendType" SG_ 168 DgnInf 12;
BA_ "GenSigDeltaValue" SG_ 168 DgnInf 1;
BA_ "VNSigAllNodes" SG_ 168 DgnInf 1;
BA_ "SignalType" SG_ 168 DgnInf "UNM";
BA_ "SignalLongName" SG_ 168 DgnInf "Diagnostic Information";
BA_ "VNSigDiagnostic" SG_ 153 DgnInf 1;
BA_ "GenSigSendType" SG_ 153 DgnInf 12;
BA_ "GenSigDeltaValue" SG_ 153 DgnInf 1;
BA_ "VNSigAllNodes" SG_ 153 DgnInf 1;
BA_ "SignalType" SG_ 153 DgnInf "UNM";
BA_ "SignalLongName" SG_ 153 DgnInf "Diagnostic Information";
BA_ "VNSigIntermediate" SG_ 2152046592 RmClmCtrlHMIActIndReq 1;
BA_ "GenSigSendType" SG_ 2152046592 RmClmCtrlHMIActIndReq 10;
BA_ "SignalType" SG_ 2152046592 RmClmCtrlHMIActIndReq "ENM";
BA_ "SignalLongName" SG_ 2152046592 RmClmCtrlHMIActIndReq "Remote Climate Control HMI Active Indication Request";
BA_ "VNSigIntermediate" SG_ 2152046592 RmClmCtrlSyncSetReq 1;
BA_ "GenSigSendType" SG_ 2152046592 RmClmCtrlSyncSetReq 10;
BA_ "SignalType" SG_ 2152046592 RmClmCtrlSyncSetReq "ENM";
BA_ "SignalLongName" SG_ 2152046592 RmClmCtrlSyncSetReq "Remote Climate Control Sync Setting Request";
BA_ "VNSigIntermediate" SG_ 2152046592 RmClmCtrlRrDfgSetReq 1;
BA_ "GenSigSendType" SG_ 2152046592 RmClmCtrlRrDfgSetReq 10;
BA_ "SignalType" SG_ 2152046592 RmClmCtrlRrDfgSetReq "ENM";
BA_ "SignalLongName" SG_ 2152046592 RmClmCtrlRrDfgSetReq "Remote Climate Control Rear Defog Setting Request";
BA_ "VNSigIntermediate" SG_ 2152046592 RmClmCtrlRcrcSetReq 1;
BA_ "GenSigSendType" SG_ 2152046592 RmClmCtrlRcrcSetReq 10;
BA_ "SignalType" SG_ 2152046592 RmClmCtrlRcrcSetReq "ENM";
BA_ "SignalLongName" SG_ 2152046592 RmClmCtrlRcrcSetReq "Remote Climate Control Recirculation Setting Request";
BA_ "VNSigIntermediate" SG_ 2152046592 RmClmCtrlClmModSetReq 1;
BA_ "GenSigSendType" SG_ 2152046592 RmClmCtrlClmModSetReq 10;
BA_ "SignalType" SG_ 2152046592 RmClmCtrlClmModSetReq "ENM";
BA_ "SignalLongName" SG_ 2152046592 RmClmCtrlClmModSetReq "Remote Climate Control Climate Mode Setting Request";
BA_ "VNSigIntermediate" SG_ 2152046592 RmClmCtrlACSetReq 1;
BA_ "GenSigSendType" SG_ 2152046592 RmClmCtrlACSetReq 10;
BA_ "SignalType" SG_ 2152046592 RmClmCtrlACSetReq "ENM";
BA_ "SignalLongName" SG_ 2152046592 RmClmCtrlACSetReq "Remote Climate Control Air Conditioning Setting Request";
BA_ "VNSigIntermediate" SG_ 2152046592 RmClmCtrlFLAirDtStReq 1;
BA_ "GenSigSendType" SG_ 2152046592 RmClmCtrlFLAirDtStReq 10;
BA_ "SignalType" SG_ 2152046592 RmClmCtrlFLAirDtStReq "ENM";
BA_ "SignalLongName" SG_ 2152046592 RmClmCtrlFLAirDtStReq "Remote Climate Control Front Left Air Distribution Setting Request";
BA_ "VNSigIntermediate" SG_ 2152046592 RmClmCtrlFrntFanStReq 1;
BA_ "GenSigSendType" SG_ 2152046592 RmClmCtrlFrntFanStReq 10;
BA_ "SignalType" SG_ 2152046592 RmClmCtrlFrntFanStReq "ENM";
BA_ "SignalLongName" SG_ 2152046592 RmClmCtrlFrntFanStReq "Remote Climate Control Front Fan Setting Request";
BA_ "VNSigIntermediate" SG_ 2152046592 RmClmCtrlRtSTempStReq 1;
BA_ "GenSigSendType" SG_ 2152046592 RmClmCtrlRtSTempStReq 10;
BA_ "SignalType" SG_ 2152046592 RmClmCtrlRtSTempStReq "ENM";
BA_ "SignalLongName" SG_ 2152046592 RmClmCtrlRtSTempStReq "Remote Climate Control Right Set Temperature Setting Request";
BA_ "VNSigIntermediate" SG_ 2152046592 RmClmCtrlLtSTempStReq 1;
BA_ "GenSigSendType" SG_ 2152046592 RmClmCtrlLtSTempStReq 10;
BA_ "SignalType" SG_ 2152046592 RmClmCtrlLtSTempStReq "ENM";
BA_ "SignalLongName" SG_ 2152046592 RmClmCtrlLtSTempStReq "Remote Climate Control Left Set Temperature Setting Request";
BA_ "VNSigDiagnostic" SG_ 2032 DgnInf 1;
BA_ "GenSigSendType" SG_ 2032 DgnInf 12;
BA_ "GenSigDeltaValue" SG_ 2032 DgnInf 1;
BA_ "VNSigAllNodes" SG_ 2032 DgnInf 1;
BA_ "SignalType" SG_ 2032 DgnInf "UNM";
BA_ "SignalLongName" SG_ 2032 DgnInf "Diagnostic Information";
BA_ "GenSigSendOnInit" SG_ 2150563840 PsStStatDispAct 2;
BA_ "GenSigSendType" SG_ 2150563840 PsStStatDispAct 10;
BA_ "VNSigAllNodes" SG_ 2150563840 PsStStatDispAct 1;
BA_ "SignalType" SG_ 2150563840 PsStStatDispAct "BLN";
BA_ "SignalLongName" SG_ 2150563840 PsStStatDispAct "Passenger Seat Status Display Active";
BA_ "GenSigSendOnInit" SG_ 2150563840 DrStStatDispAct 2;
BA_ "GenSigSendType" SG_ 2150563840 DrStStatDispAct 10;
BA_ "VNSigAllNodes" SG_ 2150563840 DrStStatDispAct 1;
BA_ "SignalType" SG_ 2150563840 DrStStatDispAct "BLN";
BA_ "SignalLongName" SG_ 2150563840 DrStStatDispAct "Driver Seat Status Display Active";
BA_ "GenSigSendOnInit" SG_ 2150563840 RadAudQueStat 2;
BA_ "GenSigSendType" SG_ 2150563840 RadAudQueStat 10;
BA_ "VNSigAllNodes" SG_ 2150563840 RadAudQueStat 1;
BA_ "SignalType" SG_ 2150563840 RadAudQueStat "ENM";
BA_ "SignalLongName" SG_ 2150563840 RadAudQueStat "Radio Audio Queue Status";
BA_ "GenSigSendOnInit" SG_ 2150563840 RadAnmtStat 2;
BA_ "GenSigSendType" SG_ 2150563840 RadAnmtStat 10;
BA_ "VNSigAllNodes" SG_ 2150563840 RadAnmtStat 1;
BA_ "SignalType" SG_ 2150563840 RadAnmtStat "ENM";
BA_ "SignalLongName" SG_ 2150563840 RadAnmtStat "Radio Animation Status";
BA_ "GenSigSendType" SG_ 2151948288 RunBrdOpMdCstStReq 10;
BA_ "VNSigAllNodes" SG_ 2151948288 RunBrdOpMdCstStReq 1;
BA_ "SignalType" SG_ 2151948288 RunBrdOpMdCstStReq "ENM";
BA_ "SignalLongName" SG_ 2151948288 RunBrdOpMdCstStReq "Running Boards Operating Mode Customization Setting Request";
BA_ "GenSigSendType" SG_ 2151948288 DrvDrowDetCstStRq 10;
BA_ "VNSigAllNodes" SG_ 2151948288 DrvDrowDetCstStRq 1;
BA_ "SignalType" SG_ 2151948288 DrvDrowDetCstStRq "ENM";
BA_ "SignalLongName" SG_ 2151948288 DrvDrowDetCstStRq "Driver Drowsiness Detection Customization Setting Request";
BA_ "GenSigSendOnInit" SG_ 2156806144 CellNtwrkDtTmAvl 2;
BA_ "GenSigSendType" SG_ 2156806144 CellNtwrkDtTmAvl 10;
BA_ "VNSigAllNodes" SG_ 2156806144 CellNtwrkDtTmAvl 1;
BA_ "SignalType" SG_ 2156806144 CellNtwrkDtTmAvl "BLN";
BA_ "SignalLongName" SG_ 2156806144 CellNtwrkDtTmAvl "Cellular Network Date and Time Available";
BA_ "GenSigSendType" SG_ 2156806144 SecCmpstdValV 10;
BA_ "VNSigAllNodes" SG_ 2156806144 SecCmpstdValV 1;
BA_ "SignalType" SG_ 2156806144 SecCmpstdValV "ENM";
BA_ "SignalLongName" SG_ 2156806144 SecCmpstdValV "Seconds Compensated Value Validity";
BA_ "GenSigSendType" SG_ 2156806144 SecCmpstdVal 12;
BA_ "GenSigDeltaValue" SG_ 2156806144 SecCmpstdVal 1;
BA_ "VNSigAllNodes" SG_ 2156806144 SecCmpstdVal 1;
BA_ "SignalType" SG_ 2156806144 SecCmpstdVal "UNM";
BA_ "SignalLongName" SG_ 2156806144 SecCmpstdVal "Seconds Compensated Value";
BA_ "GenSigSendType" SG_ 2156806144 MinsCmpstdValV 10;
BA_ "VNSigAllNodes" SG_ 2156806144 MinsCmpstdValV 1;
BA_ "SignalType" SG_ 2156806144 MinsCmpstdValV "ENM";
BA_ "SignalLongName" SG_ 2156806144 MinsCmpstdValV "Minutes Compensated Value Validity";
BA_ "GenSigSendType" SG_ 2156806144 MinsCmpstdVal 12;
BA_ "GenSigDeltaValue" SG_ 2156806144 MinsCmpstdVal 1;
BA_ "VNSigAllNodes" SG_ 2156806144 MinsCmpstdVal 1;
BA_ "SignalType" SG_ 2156806144 MinsCmpstdVal "UNM";
BA_ "SignalLongName" SG_ 2156806144 MinsCmpstdVal "Minutes Compensated Value";
BA_ "GenSigSendType" SG_ 2156806144 HrsCmpstdValV 10;
BA_ "VNSigAllNodes" SG_ 2156806144 HrsCmpstdValV 1;
BA_ "SignalType" SG_ 2156806144 HrsCmpstdValV "ENM";
BA_ "SignalLongName" SG_ 2156806144 HrsCmpstdValV "Hours Compensated Value Validity";
BA_ "GenSigSendType" SG_ 2156806144 HrsCmpstdVal 12;
BA_ "GenSigDeltaValue" SG_ 2156806144 HrsCmpstdVal 1;
BA_ "VNSigAllNodes" SG_ 2156806144 HrsCmpstdVal 1;
BA_ "SignalType" SG_ 2156806144 HrsCmpstdVal "UNM";
BA_ "SignalLongName" SG_ 2156806144 HrsCmpstdVal "Hours Compensated Value";
BA_ "GenSigSendType" SG_ 2156806144 CldrYrCmpstdVal 12;
BA_ "GenSigDeltaValue" SG_ 2156806144 CldrYrCmpstdVal 1;
BA_ "VNSigAllNodes" SG_ 2156806144 CldrYrCmpstdVal 1;
BA_ "SignalType" SG_ 2156806144 CldrYrCmpstdVal "UNM";
BA_ "SignalLongName" SG_ 2156806144 CldrYrCmpstdVal "Calendar Year Compensated Value";
BA_ "GenSigSendType" SG_ 2156806144 CldrMthCmpstdVal 10;
BA_ "VNSigAllNodes" SG_ 2156806144 CldrMthCmpstdVal 1;
BA_ "SignalType" SG_ 2156806144 CldrMthCmpstdVal "ENM";
BA_ "SignalLongName" SG_ 2156806144 CldrMthCmpstdVal "Calendar Month Compensated Value";
BA_ "GenSigSendType" SG_ 2156806144 CldrDayCmpstdVal 12;
BA_ "GenSigDeltaValue" SG_ 2156806144 CldrDayCmpstdVal 1;
BA_ "VNSigAllNodes" SG_ 2156806144 CldrDayCmpstdVal 1;
BA_ "SignalType" SG_ 2156806144 CldrDayCmpstdVal "UNM";
BA_ "SignalLongName" SG_ 2156806144 CldrDayCmpstdVal "Calendar Day Compensated Value";
BA_ "VNSigDiagnostic" SG_ 1350 DgnInf_LS546 1;
BA_ "GenSigSendType" SG_ 1350 DgnInf_LS546 12;
BA_ "GenSigDeltaValue" SG_ 1350 DgnInf_LS546 1;
BA_ "VNSigAllNodes" SG_ 1350 DgnInf_LS546 1;
BA_ "SignalType" SG_ 1350 DgnInf_LS546 "UNM";
BA_ "SignalLongName" SG_ 1350 DgnInf_LS546 "Diagnostic Information LS546";
BA_ "GenSigSendType" SG_ 2158886912 ODDLI_SubIdReqM 12;
BA_ "GenSigDeltaValue" SG_ 2158886912 ODDLI_SubIdReqM 1;
BA_ "VNSigAllNodes" SG_ 2158886912 ODDLI_SubIdReqM 1;
BA_ "SignalType" SG_ 2158886912 ODDLI_SubIdReqM "UNM";
BA_ "PacketOrder" SG_ 2158886912 ODDLI_SubIdReqM 10;
BA_ "SignalLongName" SG_ 2158886912 ODDLI_SubIdReqM "Open Display Interface Dynamic Data List Request IPC : Sub Id Request Mask";
BA_ "GenSigSendType" SG_ 2158886912 ODDLI_WrpArnd 10;
BA_ "VNSigAllNodes" SG_ 2158886912 ODDLI_WrpArnd 1;
BA_ "SignalType" SG_ 2158886912 ODDLI_WrpArnd "BLN";
BA_ "PacketOrder" SG_ 2158886912 ODDLI_WrpArnd 9;
BA_ "SignalLongName" SG_ 2158886912 ODDLI_WrpArnd "Open Display Interface Dynamic Data List Request IPC : Wrap Around";
BA_ "GenSigSendType" SG_ 2158886912 ODDLI_ReqType 10;
BA_ "VNSigAllNodes" SG_ 2158886912 ODDLI_ReqType 1;
BA_ "SignalType" SG_ 2158886912 ODDLI_ReqType "ENM";
BA_ "PacketOrder" SG_ 2158886912 ODDLI_ReqType 7;
BA_ "SignalLongName" SG_ 2158886912 ODDLI_ReqType "Open Display Interface Dynamic Data List Request IPC : Request Type";
BA_ "GenSigSendType" SG_ 2158886912 ODDLI_ReqDir 10;
BA_ "VNSigAllNodes" SG_ 2158886912 ODDLI_ReqDir 1;
BA_ "SignalType" SG_ 2158886912 ODDLI_ReqDir "BLN";
BA_ "PacketOrder" SG_ 2158886912 ODDLI_ReqDir 5;
BA_ "SignalLongName" SG_ 2158886912 ODDLI_ReqDir "Open Display Interface Dynamic Data List Request IPC : Req Direction";
BA_ "GenSigSendType" SG_ 2158886912 ODDLI_NmEntries 12;
BA_ "GenSigDeltaValue" SG_ 2158886912 ODDLI_NmEntries 1;
BA_ "VNSigAllNodes" SG_ 2158886912 ODDLI_NmEntries 1;
BA_ "SignalType" SG_ 2158886912 ODDLI_NmEntries "UNM";
BA_ "PacketOrder" SG_ 2158886912 ODDLI_NmEntries 4;
BA_ "SignalLongName" SG_ 2158886912 ODDLI_NmEntries "Open Display Interface Dynamic Data List Request IPC : Num Entries";
BA_ "GenSigSendType" SG_ 2158886912 ODDLI_Idx 12;
BA_ "GenSigDeltaValue" SG_ 2158886912 ODDLI_Idx 1;
BA_ "VNSigAllNodes" SG_ 2158886912 ODDLI_Idx 1;
BA_ "SignalType" SG_ 2158886912 ODDLI_Idx "UNM";
BA_ "PacketOrder" SG_ 2158886912 ODDLI_Idx 6;
BA_ "SignalLongName" SG_ 2158886912 ODDLI_Idx "Open Display Interface Dynamic Data List Request IPC : Index";
BA_ "GenSigSendType" SG_ 2158886912 ODDLI_FUCID 12;
BA_ "GenSigDeltaValue" SG_ 2158886912 ODDLI_FUCID 1;
BA_ "VNSigAllNodes" SG_ 2158886912 ODDLI_FUCID 1;
BA_ "SignalType" SG_ 2158886912 ODDLI_FUCID "UNM";
BA_ "PacketOrder" SG_ 2158886912 ODDLI_FUCID 1;
BA_ "SignalLongName" SG_ 2158886912 ODDLI_FUCID "Open Display Interface Dynamic Data List Request IPC : Functional Unit Class ID";
BA_ "GenSigSendType" SG_ 2158886912 ODDLI_DspMID 10;
BA_ "VNSigAllNodes" SG_ 2158886912 ODDLI_DspMID 1;
BA_ "SignalType" SG_ 2158886912 ODDLI_DspMID "ENM";
BA_ "PacketOrder" SG_ 2158886912 ODDLI_DspMID 3;
BA_ "SignalLongName" SG_ 2158886912 ODDLI_DspMID "Open Display Interface Dynamic Data List Request IPC : Display Mask Id";
BA_ "GenSigSendType" SG_ 2158886912 ODDLI_DataId 12;
BA_ "GenSigDeltaValue" SG_ 2158886912 ODDLI_DataId 1;
BA_ "VNSigAllNodes" SG_ 2158886912 ODDLI_DataId 1;
BA_ "SignalType" SG_ 2158886912 ODDLI_DataId "UNM";
BA_ "PacketOrder" SG_ 2158886912 ODDLI_DataId 2;
BA_ "SignalLongName" SG_ 2158886912 ODDLI_DataId "Open Display Interface Dynamic Data List Request IPC : Data Id";
BA_ "GenSigSendType" SG_ 2158886912 ODDLI_BckgndFlag 10;
BA_ "VNSigAllNodes" SG_ 2158886912 ODDLI_BckgndFlag 1;
BA_ "SignalType" SG_ 2158886912 ODDLI_BckgndFlag "ENM";
BA_ "PacketOrder" SG_ 2158886912 ODDLI_BckgndFlag 8;
BA_ "SignalLongName" SG_ 2158886912 ODDLI_BckgndFlag "Open Display Interface Dynamic Data List Request IPC : Background Flag";
BA_ "VNSigDiagnostic" SG_ 579 DgnInf 1;
BA_ "GenSigSendType" SG_ 579 DgnInf 12;
BA_ "GenSigDeltaValue" SG_ 579 DgnInf 1;
BA_ "VNSigAllNodes" SG_ 579 DgnInf 1;
BA_ "SignalType" SG_ 579 DgnInf "UNM";
BA_ "SignalLongName" SG_ 579 DgnInf "Diagnostic Information";
BA_ "GenSigSendType" SG_ 2159132672 ODIAR_FUCID 12;
BA_ "GenSigDeltaValue" SG_ 2159132672 ODIAR_FUCID 1;
BA_ "VNSigAllNodes" SG_ 2159132672 ODIAR_FUCID 1;
BA_ "SignalType" SG_ 2159132672 ODIAR_FUCID "UNM";
BA_ "PacketOrder" SG_ 2159132672 ODIAR_FUCID 2;
BA_ "SignalLongName" SG_ 2159132672 ODIAR_FUCID "Open Display Interface Action Rear Seat Display : FU Class ID";
BA_ "GenSigSendType" SG_ 2159132672 ODIAR_DspMID 10;
BA_ "VNSigAllNodes" SG_ 2159132672 ODIAR_DspMID 1;
BA_ "SignalType" SG_ 2159132672 ODIAR_DspMID "ENM";
BA_ "PacketOrder" SG_ 2159132672 ODIAR_DspMID 4;
BA_ "SignalLongName" SG_ 2159132672 ODIAR_DspMID "Open Display Interface Action Rear Seat Display : Display Mask ID";
BA_ "GenSigSendType" SG_ 2159132672 ODIAR_DaTy 10;
BA_ "GenSigDeltaValue" SG_ 2159132672 ODIAR_DaTy 1;
BA_ "VNSigAllNodes" SG_ 2159132672 ODIAR_DaTy 1;
BA_ "SignalType" SG_ 2159132672 ODIAR_DaTy "ENM";
BA_ "PacketOrder" SG_ 2159132672 ODIAR_DaTy 1;
BA_ "SignalLongName" SG_ 2159132672 ODIAR_DaTy "Open Display Interface Action Rear Seat Display : DataType";
BA_ "GenSigSendType" SG_ 2159132672 ODIAR_ActnVal 12;
BA_ "GenSigDeltaValue" SG_ 2159132672 ODIAR_ActnVal 1;
BA_ "VNSigAllNodes" SG_ 2159132672 ODIAR_ActnVal 1;
BA_ "SignalType" SG_ 2159132672 ODIAR_ActnVal "UNM";
BA_ "PacketOrder" SG_ 2159132672 ODIAR_ActnVal 5;
BA_ "SignalLongName" SG_ 2159132672 ODIAR_ActnVal "Open Display Interface Action Rear Seat Display : Action Value";
BA_ "GenSigSendType" SG_ 2159132672 ODIAR_ActnID 12;
BA_ "GenSigDeltaValue" SG_ 2159132672 ODIAR_ActnID 1;
BA_ "VNSigAllNodes" SG_ 2159132672 ODIAR_ActnID 1;
BA_ "SignalType" SG_ 2159132672 ODIAR_ActnID "UNM";
BA_ "PacketOrder" SG_ 2159132672 ODIAR_ActnID 3;
BA_ "SignalLongName" SG_ 2159132672 ODIAR_ActnID "Open Display Interface Action Rear Seat Display : Action ID";
BA_ "GenSigSendType" SG_ 2154692608 LgclAVChnl 10;
BA_ "VNSigAllNodes" SG_ 2154692608 LgclAVChnl 1;
BA_ "SignalType" SG_ 2154692608 LgclAVChnl "ENM";
BA_ "SignalLongName" SG_ 2154692608 LgclAVChnl "Logical AV Channel";
BA_ "GenSigSendType" SG_ 2154692608 ASSAudSrcStatCode 10;
BA_ "VNSigAllNodes" SG_ 2154692608 ASSAudSrcStatCode 1;
BA_ "SignalType" SG_ 2154692608 ASSAudSrcStatCode "ENM";
BA_ "PacketOrder" SG_ 2154692608 ASSAudSrcStatCode 3;
BA_ "SignalLongName" SG_ 2154692608 ASSAudSrcStatCode "Audio Source Status : Audio Source Status Code";
BA_ "GenSigSendType" SG_ 2154692608 ASSAudSrcChType 10;
BA_ "VNSigAllNodes" SG_ 2154692608 ASSAudSrcChType 1;
BA_ "SignalType" SG_ 2154692608 ASSAudSrcChType "ENM";
BA_ "PacketOrder" SG_ 2154692608 ASSAudSrcChType 2;
BA_ "SignalLongName" SG_ 2154692608 ASSAudSrcChType "Audio Source Status : Audio Source Channel Type";
BA_ "GenSigSendType" SG_ 2154692608 ASSAudSrcType 10;
BA_ "VNSigAllNodes" SG_ 2154692608 ASSAudSrcType 1;
BA_ "SignalType" SG_ 2154692608 ASSAudSrcType "ENM";
BA_ "PacketOrder" SG_ 2154692608 ASSAudSrcType 1;
BA_ "SignalLongName" SG_ 2154692608 ASSAudSrcType "Audio Source Status : Audio Source Type";
BA_ "VNSigDiagnostic" SG_ 597 DgnInf 1;
BA_ "GenSigSendType" SG_ 597 DgnInf 12;
BA_ "GenSigDeltaValue" SG_ 597 DgnInf 1;
BA_ "VNSigAllNodes" SG_ 597 DgnInf 1;
BA_ "SignalType" SG_ 597 DgnInf "UNM";
BA_ "SignalLongName" SG_ 597 DgnInf "Diagnostic Information";
BA_ "VNSigDiagnostic" SG_ 1357 DgnInf_LS54D 1;
BA_ "GenSigSendType" SG_ 1357 DgnInf_LS54D 12;
BA_ "GenSigDeltaValue" SG_ 1357 DgnInf_LS54D 1;
BA_ "VNSigAllNodes" SG_ 1357 DgnInf_LS54D 1;
BA_ "SignalType" SG_ 1357 DgnInf_LS54D "UNM";
BA_ "SignalLongName" SG_ 1357 DgnInf_LS54D "Diagnostic Information LS54D";
BA_ "VNSigDiagnostic" SG_ 1608 DgnInf 1;
BA_ "GenSigSendType" SG_ 1608 DgnInf 12;
BA_ "GenSigDeltaValue" SG_ 1608 DgnInf 1;
BA_ "VNSigAllNodes" SG_ 1608 DgnInf 1;
BA_ "SignalType" SG_ 1608 DgnInf "UNM";
BA_ "SignalLongName" SG_ 1608 DgnInf "Diagnostic Information";
BA_ "VNSigDiagnostic" SG_ 584 DgnInf 1;
BA_ "GenSigSendType" SG_ 584 DgnInf 12;
BA_ "GenSigDeltaValue" SG_ 584 DgnInf 1;
BA_ "VNSigAllNodes" SG_ 584 DgnInf 1;
BA_ "SignalType" SG_ 584 DgnInf "UNM";
BA_ "SignalLongName" SG_ 584 DgnInf "Diagnostic Information";
BA_ "VNSigDiagnostic" SG_ 1352 DgnInf_LS548 1;
BA_ "GenSigSendType" SG_ 1352 DgnInf_LS548 12;
BA_ "GenSigDeltaValue" SG_ 1352 DgnInf_LS548 1;
BA_ "VNSigAllNodes" SG_ 1352 DgnInf_LS548 1;
BA_ "SignalType" SG_ 1352 DgnInf_LS548 "UNM";
BA_ "SignalLongName" SG_ 1352 DgnInf_LS548 "Diagnostic Information LS548";
BA_ "VNSigDiagnostic" SG_ 583 DgnInf 1;
BA_ "GenSigSendType" SG_ 583 DgnInf 12;
BA_ "GenSigDeltaValue" SG_ 583 DgnInf 1;
BA_ "VNSigAllNodes" SG_ 583 DgnInf 1;
BA_ "SignalType" SG_ 583 DgnInf "UNM";
BA_ "SignalLongName" SG_ 583 DgnInf "Diagnostic Information";
BA_ "VNSigDiagnostic" SG_ 1348 DgnInf_LS544 1;
BA_ "GenSigSendType" SG_ 1348 DgnInf_LS544 12;
BA_ "GenSigDeltaValue" SG_ 1348 DgnInf_LS544 1;
BA_ "VNSigAllNodes" SG_ 1348 DgnInf_LS544 1;
BA_ "SignalType" SG_ 1348 DgnInf_LS544 "UNM";
BA_ "SignalLongName" SG_ 1348 DgnInf_LS544 "Diagnostic Information LS544";
BA_ "VNSigDiagnostic" SG_ 591 DgnInf 1;
BA_ "GenSigSendType" SG_ 591 DgnInf 12;
BA_ "GenSigDeltaValue" SG_ 591 DgnInf 1;
BA_ "VNSigAllNodes" SG_ 591 DgnInf 1;
BA_ "SignalType" SG_ 591 DgnInf "UNM";
BA_ "SignalLongName" SG_ 591 DgnInf "Diagnostic Information";
BA_ "VNSigDiagnostic" SG_ 578 DgnInf 1;
BA_ "GenSigSendType" SG_ 578 DgnInf 12;
BA_ "GenSigDeltaValue" SG_ 578 DgnInf 1;
BA_ "VNSigAllNodes" SG_ 578 DgnInf 1;
BA_ "SignalType" SG_ 578 DgnInf "UNM";
BA_ "SignalLongName" SG_ 578 DgnInf "Diagnostic Information";
BA_ "VNSigDiagnostic" SG_ 1356 DgnInf_LS54C 1;
BA_ "GenSigSendType" SG_ 1356 DgnInf_LS54C 12;
BA_ "GenSigDeltaValue" SG_ 1356 DgnInf_LS54C 1;
BA_ "VNSigAllNodes" SG_ 1356 DgnInf_LS54C 1;
BA_ "SignalType" SG_ 1356 DgnInf_LS54C "UNM";
BA_ "SignalLongName" SG_ 1356 DgnInf_LS54C "Diagnostic Information LS54C";
BA_ "VNSigDiagnostic" SG_ 1360 DgnInf_LS550 1;
BA_ "GenSigSendType" SG_ 1360 DgnInf_LS550 12;
BA_ "GenSigDeltaValue" SG_ 1360 DgnInf_LS550 1;
BA_ "VNSigAllNodes" SG_ 1360 DgnInf_LS550 1;
BA_ "SignalType" SG_ 1360 DgnInf_LS550 "UNM";
BA_ "SignalLongName" SG_ 1360 DgnInf_LS550 "Diagnostic Information LS550";
BA_ "VNSigDiagnostic" SG_ 1616 DgnInf 1;
BA_ "GenSigSendType" SG_ 1616 DgnInf 12;
BA_ "GenSigDeltaValue" SG_ 1616 DgnInf 1;
BA_ "VNSigAllNodes" SG_ 1616 DgnInf 1;
BA_ "SignalType" SG_ 1616 DgnInf "UNM";
BA_ "SignalLongName" SG_ 1616 DgnInf "Diagnostic Information";
BA_ "VNSigDiagnostic" SG_ 593 DgnInf 1;
BA_ "GenSigSendType" SG_ 593 DgnInf 12;
BA_ "GenSigDeltaValue" SG_ 593 DgnInf 1;
BA_ "VNSigAllNodes" SG_ 593 DgnInf 1;
BA_ "SignalType" SG_ 593 DgnInf "UNM";
BA_ "SignalLongName" SG_ 593 DgnInf "Diagnostic Information";
BA_ "VNSigDiagnostic" SG_ 605 DgnInf 1;
BA_ "GenSigSendType" SG_ 605 DgnInf 12;
BA_ "GenSigDeltaValue" SG_ 605 DgnInf 1;
BA_ "VNSigAllNodes" SG_ 605 DgnInf 1;
BA_ "SignalType" SG_ 605 DgnInf "UNM";
BA_ "SignalLongName" SG_ 605 DgnInf "Diagnostic Information";
BA_ "VNSigDiagnostic" SG_ 587 DgnInf 1;
BA_ "GenSigSendType" SG_ 587 DgnInf 12;
BA_ "GenSigDeltaValue" SG_ 587 DgnInf 1;
BA_ "VNSigAllNodes" SG_ 587 DgnInf 1;
BA_ "SignalType" SG_ 587 DgnInf "UNM";
BA_ "SignalLongName" SG_ 587 DgnInf "Diagnostic Information";
BA_ "VNSigDiagnostic" SG_ 2020 DgnInf 1;
BA_ "GenSigSendType" SG_ 2020 DgnInf 12;
BA_ "GenSigDeltaValue" SG_ 2020 DgnInf 1;
BA_ "VNSigAllNodes" SG_ 2020 DgnInf 1;
BA_ "SignalType" SG_ 2020 DgnInf "UNM";
BA_ "SignalLongName" SG_ 2020 DgnInf "Diagnostic Information";
BA_ "GenSigSendType" SG_ 2152054784 IntPnlClstrAnmtStat 10;
BA_ "VNSigAllNodes" SG_ 2152054784 IntPnlClstrAnmtStat 1;
BA_ "SignalType" SG_ 2152054784 IntPnlClstrAnmtStat "ENM";
BA_ "SignalLongName" SG_ 2152054784 IntPnlClstrAnmtStat "Instrument Panel Cluster Animation Status";
BA_ "GenSigSendType" SG_ 2152054784 AnmStrtReq 10;
BA_ "VNSigAllNodes" SG_ 2152054784 AnmStrtReq 1;
BA_ "SignalType" SG_ 2152054784 AnmStrtReq "ENM";
BA_ "SignalLongName" SG_ 2152054784 AnmStrtReq "Animation Start Request";
BA_ "GenSigSendOnInit" SG_ 2152054784 FuelEconMetDispUnts 1;
BA_ "GenSigSendType" SG_ 2152054784 FuelEconMetDispUnts 10;
BA_ "VNSigAllNodes" SG_ 2152054784 FuelEconMetDispUnts 1;
BA_ "SignalType" SG_ 2152054784 FuelEconMetDispUnts "ENM";
BA_ "SignalLongName" SG_ 2152054784 FuelEconMetDispUnts "Fuel Economy Metric Display Units";
BA_ "GenSigSendOnInit" SG_ 2156281856 LftmEffDtRstRqd 1;
BA_ "GenSigSendType" SG_ 2156281856 LftmEffDtRstRqd 10;
BA_ "VNSigAllNodes" SG_ 2156281856 LftmEffDtRstRqd 1;
BA_ "SignalType" SG_ 2156281856 LftmEffDtRstRqd "BLN";
BA_ "SignalLongName" SG_ 2156281856 LftmEffDtRstRqd "Lifetime Efficiency Data Reset Requested";
BA_ "GenSigSendType" SG_ 2156281856 HTRCsStReq 10;
BA_ "VNSigAllNodes" SG_ 2156281856 HTRCsStReq 1;
BA_ "SignalType" SG_ 2156281856 HTRCsStReq "ENM";
BA_ "SignalLongName" SG_ 2156281856 HTRCsStReq "Hill Top Reserve Customization Setting Request";
BA_ "GenSigSendType" SG_ 2156281856 TODCTmpImdtOvrdReq 10;
BA_ "VNSigAllNodes" SG_ 2156281856 TODCTmpImdtOvrdReq 1;
BA_ "SignalType" SG_ 2156281856 TODCTmpImdtOvrdReq "ENM";
BA_ "SignalLongName" SG_ 2156281856 TODCTmpImdtOvrdReq "Time Of Day Charge Temporary Immediate Override Request";
BA_ "GenSigSendType" SG_ 2156281856 RtBsChrgCmplnTmPrfReq 10;
BA_ "VNSigAllNodes" SG_ 2156281856 RtBsChrgCmplnTmPrfReq 1;
BA_ "SignalType" SG_ 2156281856 RtBsChrgCmplnTmPrfReq "ENM";
BA_ "SignalLongName" SG_ 2156281856 RtBsChrgCmplnTmPrfReq "Rate Based Charge Completion Time Preference Request";
BA_ "GenSigSendType" SG_ 2156281856 TONPDTR_StTmpOvrAtv 10;
BA_ "VNSigAllNodes" SG_ 2156281856 TONPDTR_StTmpOvrAtv 1;
BA_ "SignalType" SG_ 2156281856 TONPDTR_StTmpOvrAtv "ENM";
BA_ "PacketOrder" SG_ 2156281856 TONPDTR_StTmpOvrAtv 1;
BA_ "SignalLongName" SG_ 2156281856 TONPDTR_StTmpOvrAtv "Temporary Override Next Planned Departure Time Requested : Set Temporary Override Next Planned Departure Time Active";
BA_ "GenSigSendType" SG_ 2156281856 TONPDTR_MntOfHr 12;
BA_ "GenSigDeltaValue" SG_ 2156281856 TONPDTR_MntOfHr 1;
BA_ "VNSigAllNodes" SG_ 2156281856 TONPDTR_MntOfHr 1;
BA_ "SignalType" SG_ 2156281856 TONPDTR_MntOfHr "UNM";
BA_ "PacketOrder" SG_ 2156281856 TONPDTR_MntOfHr 4;
BA_ "SignalLongName" SG_ 2156281856 TONPDTR_MntOfHr "Temporary Override Next Planned Departure Time Requested : Minute of Hour";
BA_ "GenSigSendType" SG_ 2156281856 TONPDTR_HrOfDy 12;
BA_ "GenSigDeltaValue" SG_ 2156281856 TONPDTR_HrOfDy 1;
BA_ "VNSigAllNodes" SG_ 2156281856 TONPDTR_HrOfDy 1;
BA_ "SignalType" SG_ 2156281856 TONPDTR_HrOfDy "UNM";
BA_ "PacketOrder" SG_ 2156281856 TONPDTR_HrOfDy 3;
BA_ "SignalLongName" SG_ 2156281856 TONPDTR_HrOfDy "Temporary Override Next Planned Departure Time Requested : Hour of Day";
BA_ "GenSigSendType" SG_ 2156281856 TONPDTR_DyOfWk 10;
BA_ "VNSigAllNodes" SG_ 2156281856 TONPDTR_DyOfWk 1;
BA_ "SignalType" SG_ 2156281856 TONPDTR_DyOfWk "ENM";
BA_ "PacketOrder" SG_ 2156281856 TONPDTR_DyOfWk 2;
BA_ "SignalLongName" SG_ 2156281856 TONPDTR_DyOfWk "Temporary Override Next Planned Departure Time Requested : Day of Week";
BA_ "GenSigSendType" SG_ 2156281856 StTODChrgTmpOvrd 10;
BA_ "VNSigAllNodes" SG_ 2156281856 StTODChrgTmpOvrd 1;
BA_ "SignalType" SG_ 2156281856 StTODChrgTmpOvrd "BLN";
BA_ "SignalLongName" SG_ 2156281856 StTODChrgTmpOvrd "Set Time of Day Charge Temporary Override";
BA_ "GenSigSendType" SG_ 2156281856 HVBTBSCSR_SsnStReq 10;
BA_ "VNSigAllNodes" SG_ 2156281856 HVBTBSCSR_SsnStReq 1;
BA_ "SignalType" SG_ 2156281856 HVBTBSCSR_SsnStReq "ENM";
BA_ "PacketOrder" SG_ 2156281856 HVBTBSCSR_SsnStReq 1;
BA_ "SignalLongName" SG_ 2156281856 HVBTBSCSR_SsnStReq "High Voltage Battery Time Based Season Charging Set Request : Season Set Request";
BA_ "GenSigSendType" SG_ 2156281856 HVBTBSCSR_SsnSlStReq 10;
BA_ "VNSigAllNodes" SG_ 2156281856 HVBTBSCSR_SsnSlStReq 1;
BA_ "SignalType" SG_ 2156281856 HVBTBSCSR_SsnSlStReq "ENM";
BA_ "PacketOrder" SG_ 2156281856 HVBTBSCSR_SsnSlStReq 2;
BA_ "SignalLongName" SG_ 2156281856 HVBTBSCSR_SsnSlStReq "High Voltage Battery Time Based Season Charging Set Request : Season Selected Set Requset";
BA_ "GenSigSendType" SG_ 2156281856 HVBTBSCSR_SsnMthStReq 10;
BA_ "VNSigAllNodes" SG_ 2156281856 HVBTBSCSR_SsnMthStReq 1;
BA_ "SignalType" SG_ 2156281856 HVBTBSCSR_SsnMthStReq "ENM";
BA_ "PacketOrder" SG_ 2156281856 HVBTBSCSR_SsnMthStReq 3;
BA_ "SignalLongName" SG_ 2156281856 HVBTBSCSR_SsnMthStReq "High Voltage Battery Time Based Season Charging Set Request : Season Month Set Request";
BA_ "GenSigSendType" SG_ 2156281856 HVBTBSCSR_SsnDayStReq 12;
BA_ "GenSigDeltaValue" SG_ 2156281856 HVBTBSCSR_SsnDayStReq 1;
BA_ "VNSigAllNodes" SG_ 2156281856 HVBTBSCSR_SsnDayStReq 1;
BA_ "SignalType" SG_ 2156281856 HVBTBSCSR_SsnDayStReq "UNM";
BA_ "PacketOrder" SG_ 2156281856 HVBTBSCSR_SsnDayStReq 4;
BA_ "SignalLongName" SG_ 2156281856 HVBTBSCSR_SsnDayStReq "High Voltage Battery Time Based Season Charging Set Request : Season Day Set Request";
BA_ "GenSigSendType" SG_ 2156281856 HVBTBCRSR_ChRtSlStReq 10;
BA_ "VNSigAllNodes" SG_ 2156281856 HVBTBCRSR_ChRtSlStReq 1;
BA_ "SignalType" SG_ 2156281856 HVBTBCRSR_ChRtSlStReq "ENM";
BA_ "PacketOrder" SG_ 2156281856 HVBTBCRSR_ChRtSlStReq 3;
BA_ "SignalLongName" SG_ 2156281856 HVBTBCRSR_ChRtSlStReq "High Voltage Battery Time Based Charge Rate Set Request : Charge Rate Selected Set Request";
BA_ "GenSigSendType" SG_ 2156281856 HVBTBCRSR_ChRtEnblStReq 10;
BA_ "VNSigAllNodes" SG_ 2156281856 HVBTBCRSR_ChRtEnblStReq 1;
BA_ "SignalType" SG_ 2156281856 HVBTBCRSR_ChRtEnblStReq "ENM";
BA_ "PacketOrder" SG_ 2156281856 HVBTBCRSR_ChRtEnblStReq 1;
BA_ "SignalLongName" SG_ 2156281856 HVBTBCRSR_ChRtEnblStReq "High Voltage Battery Time Based Charge Rate Set Request : Charge Rate Enable Set Request";
BA_ "GenSigSendType" SG_ 2156281856 HVBTBCRSR_ChRtDStReq 10;
BA_ "VNSigAllNodes" SG_ 2156281856 HVBTBCRSR_ChRtDStReq 1;
BA_ "SignalType" SG_ 2156281856 HVBTBCRSR_ChRtDStReq "ENM";
BA_ "PacketOrder" SG_ 2156281856 HVBTBCRSR_ChRtDStReq 2;
BA_ "SignalLongName" SG_ 2156281856 HVBTBCRSR_ChRtDStReq "High Voltage Battery Time Based Charge Rate Set Request : Charge Rate Day Set Request";
BA_ "GenSigSendType" SG_ 2156281856 HVBatTmBsChrgMdReq 10;
BA_ "VNSigAllNodes" SG_ 2156281856 HVBatTmBsChrgMdReq 1;
BA_ "SignalType" SG_ 2156281856 HVBatTmBsChrgMdReq "ENM";
BA_ "SignalLongName" SG_ 2156281856 HVBatTmBsChrgMdReq "High Voltage Battery Time Based Charging Mode Request";
BA_ "GenSigSendType" SG_ 2156281856 HVChgSyChgLvlPrfSt 10;
BA_ "VNSigAllNodes" SG_ 2156281856 HVChgSyChgLvlPrfSt 1;
BA_ "SignalType" SG_ 2156281856 HVChgSyChgLvlPrfSt "ENM";
BA_ "SignalLongName" SG_ 2156281856 HVChgSyChgLvlPrfSt "High Voltage Charging System Charge Level Preference Setting";
BA_ "GenSigSendOnInit" SG_ 2156265472 EngyUsgScrnMeasUtStat 1;
BA_ "GenSigSendType" SG_ 2156265472 EngyUsgScrnMeasUtStat 10;
BA_ "VNSigAllNodes" SG_ 2156265472 EngyUsgScrnMeasUtStat 1;
BA_ "SignalType" SG_ 2156265472 EngyUsgScrnMeasUtStat "ENM";
BA_ "SignalLongName" SG_ 2156265472 EngyUsgScrnMeasUtStat "Energy Usage Screen Measurement Unit Status";
BA_ "GenSigSendType" SG_ 2156265472 OffBrdHVCVehCsChRq 10;
BA_ "VNSigAllNodes" SG_ 2156265472 OffBrdHVCVehCsChRq 1;
BA_ "SignalType" SG_ 2156265472 OffBrdHVCVehCsChRq "BLN";
BA_ "SignalLongName" SG_ 2156265472 OffBrdHVCVehCsChRq "Off Board High Voltage Charging Vehicle Cease Charging Requested";
BA_ "GenSigSendType" SG_ 2156265472 PrtyChrgRq 10;
BA_ "VNSigAllNodes" SG_ 2156265472 PrtyChrgRq 1;
BA_ "SignalType" SG_ 2156265472 PrtyChrgRq "ENM";
BA_ "SignalLongName" SG_ 2156265472 PrtyChrgRq "Priority Charging Request";
BA_ "GenSigSendType" SG_ 2156265472 HVBTBRCSR_RtChSlStReq 10;
BA_ "VNSigAllNodes" SG_ 2156265472 HVBTBRCSR_RtChSlStReq 1;
BA_ "SignalType" SG_ 2156265472 HVBTBRCSR_RtChSlStReq "ENM";
BA_ "PacketOrder" SG_ 2156265472 HVBTBRCSR_RtChSlStReq 3;
BA_ "SignalLongName" SG_ 2156265472 HVBTBRCSR_RtChSlStReq "High Voltage Battery Time Based Rate Charging Set Request : Rate Charging Selected Set Request";
BA_ "GenSigSendType" SG_ 2156265472 HVBTBRCSR_RtChSlRtStReq 10;
BA_ "VNSigAllNodes" SG_ 2156265472 HVBTBRCSR_RtChSlRtStReq 1;
BA_ "SignalType" SG_ 2156265472 HVBTBRCSR_RtChSlRtStReq "ENM";
BA_ "PacketOrder" SG_ 2156265472 HVBTBRCSR_RtChSlRtStReq 2;
BA_ "SignalLongName" SG_ 2156265472 HVBTBRCSR_RtChSlRtStReq "High Voltage Battery Time Based Rate Charging Set Request : Rate Charging Selected Rate Set Request";
BA_ "GenSigSendType" SG_ 2156265472 HVBTBRCSR_RtChSsnStReq 10;
BA_ "VNSigAllNodes" SG_ 2156265472 HVBTBRCSR_RtChSsnStReq 1;
BA_ "SignalType" SG_ 2156265472 HVBTBRCSR_RtChSsnStReq "ENM";
BA_ "PacketOrder" SG_ 2156265472 HVBTBRCSR_RtChSsnStReq 5;
BA_ "SignalLongName" SG_ 2156265472 HVBTBRCSR_RtChSsnStReq "High Voltage Battery Time Based Rate Charging Set Request : Rate Charging Season Set Request";
BA_ "GenSigSendType" SG_ 2156265472 HVBTBRCSR_RtChMHStReq 12;
BA_ "GenSigDeltaValue" SG_ 2156265472 HVBTBRCSR_RtChMHStReq 1;
BA_ "VNSigAllNodes" SG_ 2156265472 HVBTBRCSR_RtChMHStReq 1;
BA_ "SignalType" SG_ 2156265472 HVBTBRCSR_RtChMHStReq "UNM";
BA_ "PacketOrder" SG_ 2156265472 HVBTBRCSR_RtChMHStReq 6;
BA_ "SignalLongName" SG_ 2156265472 HVBTBRCSR_RtChMHStReq "High Voltage Battery Time Based Rate Charging Set Request : Rate Charging Minute of Hour Set Request";
BA_ "GenSigSendType" SG_ 2156265472 HVBTBRCSR_RtChHStReq 12;
BA_ "GenSigDeltaValue" SG_ 2156265472 HVBTBRCSR_RtChHStReq 1;
BA_ "VNSigAllNodes" SG_ 2156265472 HVBTBRCSR_RtChHStReq 1;
BA_ "SignalType" SG_ 2156265472 HVBTBRCSR_RtChHStReq "UNM";
BA_ "PacketOrder" SG_ 2156265472 HVBTBRCSR_RtChHStReq 4;
BA_ "SignalLongName" SG_ 2156265472 HVBTBRCSR_RtChHStReq "High Voltage Battery Time Based Rate Charging Set Request : Rate Charging Hour Set Request";
BA_ "GenSigSendType" SG_ 2156265472 HVBTBRCSR_RtChDStReq 10;
BA_ "VNSigAllNodes" SG_ 2156265472 HVBTBRCSR_RtChDStReq 1;
BA_ "SignalType" SG_ 2156265472 HVBTBRCSR_RtChDStReq "ENM";
BA_ "PacketOrder" SG_ 2156265472 HVBTBRCSR_RtChDStReq 1;
BA_ "SignalLongName" SG_ 2156265472 HVBTBRCSR_RtChDStReq "High Voltage Battery Time Based Rate Charging Set Request : Rate Charging Day Set Request";
BA_ "GenSigSendType" SG_ 2156265472 HVBTBRCSR_RtChSlTbRwReq 12;
BA_ "GenSigDeltaValue" SG_ 2156265472 HVBTBRCSR_RtChSlTbRwReq 1;
BA_ "VNSigAllNodes" SG_ 2156265472 HVBTBRCSR_RtChSlTbRwReq 1;
BA_ "SignalType" SG_ 2156265472 HVBTBRCSR_RtChSlTbRwReq "UNM";
BA_ "PacketOrder" SG_ 2156265472 HVBTBRCSR_RtChSlTbRwReq 7;
BA_ "SignalLongName" SG_ 2156265472 HVBTBRCSR_RtChSlTbRwReq "High Voltage Battery Time Based Rate Charging Set Request : Rate Charging Selected Table Row Set Request";
BA_ "GenSigSendType" SG_ 2156265472 HVBTBDCSRQ_DlChSlStReq 10;
BA_ "VNSigAllNodes" SG_ 2156265472 HVBTBDCSRQ_DlChSlStReq 1;
BA_ "SignalType" SG_ 2156265472 HVBTBDCSRQ_DlChSlStReq "ENM";
BA_ "PacketOrder" SG_ 2156265472 HVBTBDCSRQ_DlChSlStReq 3;
BA_ "SignalLongName" SG_ 2156265472 HVBTBDCSRQ_DlChSlStReq "High Voltage Battery Time Based Delayed Charging Set Request : Delayed Charging Selected Set Request";
BA_ "GenSigSendType" SG_ 2156265472 HVBTBDCSRQ_DlChSsnStReq 10;
BA_ "VNSigAllNodes" SG_ 2156265472 HVBTBDCSRQ_DlChSsnStReq 1;
BA_ "SignalType" SG_ 2156265472 HVBTBDCSRQ_DlChSsnStReq "ENM";
BA_ "PacketOrder" SG_ 2156265472 HVBTBDCSRQ_DlChSsnStReq 4;
BA_ "SignalLongName" SG_ 2156265472 HVBTBDCSRQ_DlChSsnStReq "High Voltage Battery Time Based Delayed Charging Set Request : Delayed Charging Season Set Request";
BA_ "GenSigSendType" SG_ 2156265472 HVBTBDCSRQ_DlChMHStReq 12;
BA_ "GenSigDeltaValue" SG_ 2156265472 HVBTBDCSRQ_DlChMHStReq 1;
BA_ "VNSigAllNodes" SG_ 2156265472 HVBTBDCSRQ_DlChMHStReq 1;
BA_ "SignalType" SG_ 2156265472 HVBTBDCSRQ_DlChMHStReq "UNM";
BA_ "PacketOrder" SG_ 2156265472 HVBTBDCSRQ_DlChMHStReq 5;
BA_ "SignalLongName" SG_ 2156265472 HVBTBDCSRQ_DlChMHStReq "High Voltage Battery Time Based Delayed Charging Set Request : Delayed Charging Minute of Hour Set Request";
BA_ "GenSigSendType" SG_ 2156265472 HVBTBDCSRQ_DlChHStReq 12;
BA_ "GenSigDeltaValue" SG_ 2156265472 HVBTBDCSRQ_DlChHStReq 1;
BA_ "VNSigAllNodes" SG_ 2156265472 HVBTBDCSRQ_DlChHStReq 1;
BA_ "SignalType" SG_ 2156265472 HVBTBDCSRQ_DlChHStReq "UNM";
BA_ "PacketOrder" SG_ 2156265472 HVBTBDCSRQ_DlChHStReq 1;
BA_ "SignalLongName" SG_ 2156265472 HVBTBDCSRQ_DlChHStReq "High Voltage Battery Time Based Delayed Charging Set Request : Delayed Charging Hour Set Request";
BA_ "GenSigSendType" SG_ 2156265472 HVBTBDCSRQ_DlChDStReq 10;
BA_ "VNSigAllNodes" SG_ 2156265472 HVBTBDCSRQ_DlChDStReq 1;
BA_ "SignalType" SG_ 2156265472 HVBTBDCSRQ_DlChDStReq "ENM";
BA_ "PacketOrder" SG_ 2156265472 HVBTBDCSRQ_DlChDStReq 2;
BA_ "SignalLongName" SG_ 2156265472 HVBTBDCSRQ_DlChDStReq "High Voltage Battery Time Based Delayed Charging Set Request : Delayed Charging Day Set Request";
BA_ "GenSigSendType" SG_ 2156265472 ChgPwLsAlCzStRq 10;
BA_ "VNSigAllNodes" SG_ 2156265472 ChgPwLsAlCzStRq 1;
BA_ "SignalType" SG_ 2156265472 ChgPwLsAlCzStRq "ENM";
BA_ "SignalLongName" SG_ 2156265472 ChgPwLsAlCzStRq "Charge Power Loss Alert Customization Setting Request";
BA_ "GenSigSendType" SG_ 2156265472 ChgCdTfAlCzStRq 10;
BA_ "VNSigAllNodes" SG_ 2156265472 ChgCdTfAlCzStRq 1;
BA_ "SignalType" SG_ 2156265472 ChgCdTfAlCzStRq "ENM";
BA_ "SignalLongName" SG_ 2156265472 ChgCdTfAlCzStRq "Charge Cord Theft Alert Customization Setting Request";
BA_ "GenSigSendType" SG_ 2156265472 ChgSysAudInCsStReq 10;
BA_ "VNSigAllNodes" SG_ 2156265472 ChgSysAudInCsStReq 1;
BA_ "SignalType" SG_ 2156265472 ChgSysAudInCsStReq "ENM";
BA_ "SignalLongName" SG_ 2156265472 ChgSysAudInCsStReq "Charger System Audible Indication Customization Setting Request";
BA_REL_ "GenSigSuprvResp" BU_SG_REL_ MSM_LS SG_ 2150563840 DrStStatDispAct 1;
BA_REL_ "GenSigSuprvResp" BU_SG_REL_ VIS2_LS SG_ 2151948288 DrvDrowDetCstStRq 1;
BA_REL_ "GenSigSuprvResp" BU_SG_REL_ BSM_LS SG_ 2152054784 FuelEconMetDispUnts 1;
BA_REL_ "GenSigSuprvResp" BU_SG_REL_ BSM_LS SG_ 2156281856 TONPDTR_StTmpOvrAtv 1;
BA_REL_ "GenSigSuprvResp" BU_SG_REL_ BSM_LS SG_ 2156281856 TONPDTR_MntOfHr 1;
BA_REL_ "GenSigSuprvResp" BU_SG_REL_ BSM_LS SG_ 2156281856 TONPDTR_HrOfDy 1;
BA_REL_ "GenSigSuprvResp" BU_SG_REL_ BSM_LS SG_ 2156281856 TONPDTR_DyOfWk 1;
BA_REL_ "GenSigSuprvResp" BU_SG_REL_ BSM_LS SG_ 2156265472 EngyUsgScrnMeasUtStat 1;
BA_REL_ "GenSigSuprvResp" BU_SG_REL_ BSM_LS SG_ 2156265472 ChgPwLsAlCzStRq 1;
BA_REL_ "GenSigSuprvResp" BU_SG_REL_ BSM_LS SG_ 2156265472 ChgCdTfAlCzStRq 1;
VAL_ 3221225472 IMUProtLonAccM 0 "Don't Use Data" 1 "Use Data" ;
VAL_ 3221225472 BPDAPS_BkPDrvApPV 1 "Invalid" 0 "Valid" ;
VAL_ 3221225472 DrvThrottlOvrrdDet 1 "true" 0 "false" ;
VAL_ 3221225472 OvrdrvDsblReqd 1 "true" 0 "false" ;
VAL_ 2155012096 SODTmpUnavlbleIO 1 "true" 0 "false" ;
VAL_ 2155012096 SODSnsClnRqdIO 1 "true" 0 "false" ;
VAL_ 2155012096 SODRIC_Ind3 1 "true" 0 "false" ;
VAL_ 2155012096 SODRIC_Ind2 1 "true" 0 "false" ;
VAL_ 2155012096 SODRIC_Ind1 1 "true" 0 "false" ;
VAL_ 2155012096 SODRIC_IndReq 2 "Flashing Indication" 1 "Continuous Indication" 0 "Off" ;
VAL_ 2155012096 SrvSODSysIO 1 "true" 0 "false" ;
VAL_ 2151702528 LnMrkngIndRgt 3 "Unused and Reserved 1" 2 "Green Indicator" 1 "White Indicator" 0 "Indicator Off" ;
VAL_ 2151702528 LnMrkngIndLft 3 "Unused and Reserved 1" 2 "Green Indicator" 1 "White Indicator" 0 "Indicator Off" ;
VAL_ 2151702528 LnKepAsstStIndRgt 7 "Unused and Reserved 2" 6 "Unused and Reserved 1" 5 "Yellow Indicator" 4 "Red Indicator" 3 "Blue Indicator" 2 "Green Indicator" 1 "White Indicator" 0 "Indicator Off" ;
VAL_ 2151702528 LnKepAsstStIndLft 7 "Unused and Reserved 2" 6 "Unused and Reserved 1" 5 "Yellow Indicator" 4 "Red Indicator" 3 "Blue Indicator" 2 "Green Indicator" 1 "White Indicator" 0 "Indicator Off" ;
VAL_ 2151702528 LnKpngAstRecfblIndRq 7 "Unused and Reserved 2" 6 "Unused and Reserved 1" 5 "Yellow Solid Indicator" 4 "Yellow Flashing Indicator" 3 "Blue Solid Indicator" 2 "Green Solid Indicator" 1 "White Solid Indicator" 0 "Indicator Off" ;
VAL_ 2155126784 DrvrSetRrwrdMvmnt 7 "Supervised Seat Recline Rearward" 6 "Supervised Seat Rear Down" 5 "Supervised Seat Rearward" 4 "Button Memory 1 and 2 EXIT Recall" ;
VAL_ 2155102208 DSMP_UnsdRsrvd 1 "true" 0 "false" ;
VAL_ 2155085824 CPMAPINFO4 1 "Hardware Or Software Error" 0 "No Hardware Or Software Error" ;
VAL_ 2155085824 StrgColCommsFlt 2 "Disabled Communications DTC" 1 "No Communications Fault" 0 "Communications Fault" ;
VAL_ 2155085824 DSCDS_DispReq 1 "true" 0 "false" ;
VAL_ 2155085824 DSCDS_DispSz 3 "Reserved" 2 "Small Size" 1 "Medium Size" 0 "Full Size" ;
VAL_ 2155085824 DSCDS_CshLgAdjFdRr 3 "Rearward" 2 "Forward" 1 "Selected - No Movement" 0 "Not Selected" ;
VAL_ 2155085824 DSCDS_BkCshBlstInOt 5 "Cushion Bolster Out" 4 "Cushion Bolster In" 3 "Back Bolster Out" 2 "Back Bolster In" 1 "Selected - No Movement" 0 "Not Selected" ;
VAL_ 2155085824 DSCDS_CshBlstrInOut 3 "Out" 2 "In" 1 "Selected - No Movement" 0 "Not Selected" ;
VAL_ 2155085824 DSCDS_BkBlstrInOut 3 "Out" 2 "In" 1 "Selected - No Movement" 0 "Not Selected" ;
VAL_ 2155085824 DSCDS_LmbrUDnFdRr 5 "Rearward" 4 "Forward" 3 "Down" 2 "Up" 1 "Selected - No Movement" 0 "Not Selected" ;
VAL_ 2155085824 DSCDS_LmbrFwdRr 3 "Rearward" 2 "Forward" 1 "Selected - No Movement" 0 "Not Selected" ;
VAL_ 2155085824 DSCDS_LmbrUpDwn 3 "Down" 2 "Up" 1 "Selected - No Movement" 0 "Not Selected" ;
VAL_ 2155085824 DSCDS_UprShldrFdRr 3 "Rearward" 2 "Forward" 1 "Selected - No Movement" 0 "Not Selected" ;
VAL_ 2155085824 DSCDS_HdrstTltFwdRr 0 "Not Selected" 3 "Rearward" 2 "Forward" 1 "Selected - No Movement" ;
VAL_ 2155085824 DSCDS_HdrstWngInOt 3 "Out" 2 "In" 1 "Selected - No Movement" 0 "Not Selected" ;
VAL_ 2155085824 DSCDS_HdrstUDnFdRr 5 "Rearward" 4 "Forward" 3 "Down" 2 "Up" 1 "Selected - No Movement" 0 "Not Selected" ;
VAL_ 2155085824 DSCDS_HdrstFwdRrwd 3 "Rearward" 2 "Forward" 1 "Selected - No Movement" 0 "Not Selected" ;
VAL_ 2155085824 DSCDS_HdrstUpDn 3 "Down" 2 "Up" 1 "Selected - No Movement" 0 "Not Selected" ;
VAL_ 2155085824 DSCDS_MassgIntsty 7 "Massage Intensity 7" 6 "Massage Intensity 6" 5 "Massage Intensity 5" 4 "Massage Intensity 4" 3 "Massage Intensity 3" 2 "Massage Intensity 2" 1 "Massage Intensity 1" 0 "Massage Off" ;
VAL_ 2155085824 DSCDS_MassgTyp 15 "Massage Type 15" 14 "Massage Type 14" 13 "Massage Type 13" 12 "Massage Type 12" 11 "Massage Type 11" 10 "Massage Type 10" 9 "Massage Type 9" 8 "Massage Type 8" 7 "Massage Type 7" 6 "Massage Type 6" 5 "Massage Type 5" 4 "Massage Type 4" 3 "Massage Type 3" 2 "Massage Type 2" 1 "Massage Type 1" 0 "Massage Off" ;
VAL_ 2155085824 DSCDS_Massg 2 "Selected Massage On" 1 "Selected Massage Off" 0 "Not Selected" ;
VAL_ 2152857600 ACCGrnMdStat 0 "Not Active" 1 "Ready to Assist" 2 "(Curve / Urban / Slope) Active" 3 "Temporarily not Available" ;
VAL_ 2152857600 ACCRteSpdAdaptStat 0 "Not Active" 1 "Ready to Assist" 2 "Active" 3 "Temporarily not Available" ;
VAL_ 2152857600 ACCRteSpdDrvIntvReq 0 "No Indication" 1 "Indication Level 1" 2 "Indication Level 2" 3 "Indication Level 3" ;
VAL_ 2152857600 ACCTrfcJamAstActStat 0 "Not Active" 1 "Timer Elapsed" 2 "Timer Active" 3 "Timer Retriggered" 4 "Timer Canceled" 5 "Temporarily Not Available" 6 "Traffic Jam Assist Failed" 7 "Vehicle Auto Go Notification" ;
VAL_ 2151489536 ACCLwVisbltyIO 1 "true" 0 "false" ;
VAL_ 2151489536 NVSysStat 7 "Needs Headlights" 6 "Temporarily Unavailable" 5 "Not Dark" 4 "Needs Service" 3 "Active" 2 "Inactive" 1 "Initializing" 0 "Unknown" ;
VAL_ 2151489536 RVBShtToPrkBfExtngVehIO 1 "true" 0 "false" ;
VAL_ 2151489536 RVBAutoBrkRlsIO 1 "true" 0 "false" ;
VAL_ 2152759296 PedWrnIndReq 3 "Reserved " 2 "Pedestrian alert" 1 "Pedestrian detected" 0 "None" ;
VAL_ 2152759296 FrtRdrFldIO 1 "true" 0 "false" ;
VAL_ 2152759296 FrtCmrFldIO 1 "true" 0 "false" ;
VAL_ 2152759296 FrtEOCMMdlFldIO 1 "true" 0 "false" ;
VAL_ 2152759296 FrtCmrBlckdIO 1 "true" 0 "false" ;
VAL_ 2152742912 ShrtRngRdrOffIO 1 "true" 0 "false" ;
VAL_ 2152742912 RrRdrFldIO 1 "true" 0 "false" ;
VAL_ 2152742912 RrRdrBlckdIO 1 "true" 0 "false" ;
VAL_ 2152742912 RrEOCMMdlFldIO 1 "true" 0 "false" ;
VAL_ 2154995712 HVHtrFldIO 1 "true" 0 "false" ;
VAL_ 2154995712 HVHtrOvrTmpIndOn 1 "true" 0 "false" ;
VAL_ 2150825984 PdstIntdProtSysDplyd 1 "true" 0 "false" ;
VAL_ 2150825984 PdstIntdProtSysDsbld 1 "true" 0 "false" ;
VAL_ 2150825984 SrvIntdPdstProtSysIO 1 "true" 0 "false" ;
VAL_ 2150825984 FstnThrdRwRtPsStbtInR 3 "Unbuckled information indication" 2 "Buckled Indication" 1 "Unbuckled Indication" 0 "No Indication" ;
VAL_ 2150825984 FstnThrdRwLtPsStbtInR 3 "Unbuckled information indication" 2 "Buckled Indication" 1 "Unbuckled Indication" 0 "No Indication" ;
VAL_ 2150825984 FstnThrdRwCtPsStbtInR 3 "Unbuckled information indication" 2 "Buckled Indication" 1 "Unbuckled Indication" 0 "No Indication" ;
VAL_ 2150825984 FPSIC_IndPer 15 "8.0 s" 14 "7.0 s" 13 "6.0 s" 12 "5.0 s" 11 "4.0 s" 10 "3.5 s" 9 "3.0 s" 8 "2.5 s" 7 "2.0 s" 6 "1.75 s" 5 "1.50 s" 4 "1.25 s" 3 "1.0 s" 2 "0.75 s" 1 "0.5 s" 0 "0.25 s" ;
VAL_ 2150825984 FPSIC_IO 1 "true" 0 "false" ;
VAL_ 2150825984 FDSIC_IndPer 15 "8.0 s" 14 "7.0 s" 13 "6.0 s" 12 "5.0 s" 11 "4.0 s" 10 "3.5 s" 9 "3.0 s" 8 "2.5 s" 7 "2.0 s" 6 "1.75 s" 5 "1.50 s" 4 "1.25 s" 3 "1.0 s" 2 "0.75 s" 1 "0.5 s" 0 "0.25 s" ;
VAL_ 2150825984 FDSIC_IO 1 "true" 0 "false" ;
VAL_ 2150825984 AirbgFldIO 1 "true" 0 "false" ;
VAL_ 2150825984 SndRwStbltRdIndMd 0 "No Indication" 1 "Information Indication" 2 "Warning Indication" ;
VAL_ 2150825984 AirbgICIndPer 15 "8.0 s" 14 "7.0 s" 13 "6.0 s" 12 "5.0 s" 11 "4.0 s" 10 "3.5 s" 9 "3.0 s" 8 "2.5 s" 7 "2.0 s" 6 "1.75" 5 "1.5 s" 4 "1.25 s" 3 "1.0 s" 2 ".75 s" 1 ".5 s" 0 "0.25 s" ;
VAL_ 2150825984 AirbgICIO 1 "true" 0 "false" ;
VAL_ 2150825984 FstnSndRwRtPsStbtInR 3 "Unbuckled information indication" 2 "Buckled Indication" 1 "Unbuckled Indication" 0 "No Indication" ;
VAL_ 2150825984 FstnSndRwLtPsStbtInR 3 "Unbuckled information indication" 2 "Buckled Indication" 1 "Unbuckled Indication" 0 "No Indication" ;
VAL_ 2150825984 FstnSndRwCtPsStbtInR 3 "Unbuckled information indication" 2 "Buckled Indication" 1 "Unbuckled Indication" 0 "No Indication" ;
VAL_ 2150825984 FsnDrStbAuxIR 2 "Warning Level 2" 1 "Warning Level 1" 0 "No Indication" ;
VAL_ 2150825984 FsnPsStbAuxIR 4 "Child Warning Level 2" 3 "Child Warning Level 1" 2 "Adult Warning Level 2" 1 "Adult Warning Level 1" 0 "No Indication" ;
VAL_ 2152046592 RmClmCtrlHMIActIndReq 1 "Active" 0 "Inactive" ;
VAL_ 2152046592 RmClmCtrlSyncSetReq 2 "Dual Zone Climate Control" 1 "Single Zone Climate Control" 0 "No Action" ;
VAL_ 2152046592 RmClmCtrlRrDfgSetReq 2 "Inactive" 1 "Active" 0 "No Action" ;
VAL_ 2152046592 RmClmCtrlRcrcSetReq 4 "Inactive" 3 "Auto Recirculation" 2 "Recirculation" 1 "Fresh" 0 "No Action" ;
VAL_ 2152046592 RmClmCtrlClmModSetReq 8 "Comfort Heat" 7 "Comfort AC" 6 "Battery AC On" 5 "Auto" 4 "Active" 3 "Fan Only" 2 "Economy" 1 "Comfort" 0 "No Action" ;
VAL_ 2152046592 RmClmCtrlACSetReq 6 "Battery AC On" 5 "ECO AC on" 4 "Comfort AC On" 3 "Auto AC On" 2 "Active" 1 "Inactive" 0 "No Action" ;
VAL_ 2152046592 RmClmCtrlFLAirDtStReq 15 "E TRI LEVEL" 14 "E PANEL" 13 "E DEFOG" 12 "E DEDFROST" 11 "TRI LEVEL" 10 "DEFOG" 9 "ECO" 8 "PURGE" 7 "AC" 6 "BI LEVEL" 5 "HEATER DEFROST" 4 "HEATER" 3 "DEFROST" 2 "AUTO" 1 "OFF" 0 "No Action" ;
VAL_ 2152046592 RmClmCtrlFrntFanStReq 20 "AUTO" 19 "MAN 18" 18 "MAN 17" 17 "MAN 16" 16 "MAN 15" 15 "MAN 14" 14 "MAN 13" 13 "MAN 12" 12 "MAN 11" 11 "MAN 10" 10 "MAN 9" 9 "MAN 8" 8 "MAN 7" 7 "MAN 6" 6 "MAN 5" 5 "MAN 4" 4 "MAN 3" 3 "MAN 2" 2 "MAN 1" 1 "OFF" 0 "No Action" ;
VAL_ 2152046592 RmClmCtrlRtSTempStReq 38 "14 CELCIUS" 37 "14.5 CELCIUS" 36 "15 CELCIUS" 35 "15.5 CELCIUS" 34 "16 CELCIUS" 33 "HI" 32 "LO" 31 "31.5 CELCIUS" 30 "31 CELCIUS" 29 "30.5 CELCIUS" 28 "30 CELCIUS" 27 "29.5 CELCIUS" 26 "29 CELCIUS" 25 "28.5 CELCIUS" 24 "28 CELCIUS" 23 "27.5 CELCIUS" 22 "27 CELCIUS" 21 "26.5 CELCIUS" 20 "26 CELCIUS" 19 "25.5 CELCIUS" 18 "25 CELCIUS" 17 "24.5 CELCIUS" 16 "24 CELCIUS" 15 "23.5 CELCIUS" 14 "23 CELCIUS" 13 "22.5 CELCIUS" 12 "22 CELCIUS" 11 "21.5 CELCIUS" 10 "21 CELCIUS" 9 "20.5 CELCIUS" 8 "20 CELCIUS" 7 "19.5 CELCIUS" 6 "19 CELCIUS" 5 "18.5 CELCIUS" 4 "18 CELCIUS" 3 "17.5 CELCIUS" 2 "17 CELCIUS" 1 "16.5 CELCIUS" 0 "No Action" ;
VAL_ 2152046592 RmClmCtrlLtSTempStReq 38 "14 CELCIUS" 37 "14.5 CELCIUS" 36 "15 CELCIUS" 35 "15.5 CELCIUS" 34 "16 CELCIUS" 33 "HI" 32 "LO" 31 "31.5 CELCIUS" 30 "31 CELCIUS" 29 "30.5 CELCIUS" 28 "30 CELCIUS" 27 "29.5 CELCIUS" 26 "29 CELCIUS" 25 "28.5 CELCIUS" 24 "28 CELCIUS" 23 "27.5 CELCIUS" 22 "27 CELCIUS" 21 "26.5 CELCIUS" 20 "26 CELCIUS" 19 "25.5 CELCIUS" 18 "25 CELCIUS" 17 "24.5 CELCIUS" 16 "24 CELCIUS" 15 "23.5 CELCIUS" 14 "23 CELCIUS" 13 "22.5 CELCIUS" 12 "22 CELCIUS" 11 "21.5 CELCIUS" 10 "21 CELCIUS" 9 "20.5 CELCIUS" 8 "20 CELCIUS" 7 "19.5 CELCIUS" 6 "19 CELCIUS" 5 "18.5 CELCIUS" 4 "18 CELCIUS" 3 "17.5 CELCIUS" 2 "17 CELCIUS" 1 "16.5 CELCIUS" 0 "No Action" ;
VAL_ 2150563840 PsStStatDispAct 1 "true" 0 "false" ;
VAL_ 2150563840 DrStStatDispAct 1 "true" 0 "false" ;
VAL_ 2150563840 RadAudQueStat 0 "Audio Queue NOT Available" 1 "Audio Queue Available" 2 "Welcome Active" 3 "CRANK Active" 4 "RUN Active" 5 "Good Bye Active" 6 "Reserved" 7 "Green Queue Active" ;
VAL_ 2150563840 RadAnmtStat 0 "Animation Not Available" 1 "Animation Available" 2 "Welcome Active" 3 "CRANK Active" 4 "RUN Active" 5 "Good Bye Active" ;
VAL_ 2151948288 RunBrdOpMdCstStReq 7 "Unused and Reserved 4" 6 "Unused and Reserved 3" 5 "Unused and Reserved 2" 4 "Unused and Reserved 1" 3 "Extended" 2 "On" 1 "Off" 0 "No Action" ;
VAL_ 2151948288 DrvDrowDetCstStRq 0 "No Action" 1 "Off" 2 "On" 3 "Reserved1" 4 "Reserved2" 5 "Reserved3" 6 "Reserved4" 7 "Reserved5" ;
VAL_ 2156806144 CellNtwrkDtTmAvl 1 "true" 0 "false" ;
VAL_ 2156806144 SecCmpstdValV 1 "Invalid" 0 "Valid" ;
VAL_ 2156806144 MinsCmpstdValV 1 "Invalid" 0 "Valid" ;
VAL_ 2156806144 HrsCmpstdValV 1 "Invalid" 0 "Valid" ;
VAL_ 2156806144 CldrMthCmpstdVal 0 "Unknown" 1 "January" 2 "February" 3 "March" 4 "April" 5 "May" 6 "June" 7 "July" 8 "August" 9 "September" 10 "October" 11 "November" 12 "December" ;
VAL_ 2158886912 ODDLI_WrpArnd 1 "true" 0 "false" ;
VAL_ 2158886912 ODDLI_ReqType 0 "Subscribe: FU sends DynData back and then on change) " 1 "Unsubscribe: cancel previous Subscribe" ;
VAL_ 2158886912 ODDLI_ReqDir 1 "true" 0 "false" ;
VAL_ 2158886912 ODDLI_DspMID 128 "Reserved" 64 "Reserved" 32 "OTIM" 16 "RearDisplayTwo" 8 "RearDisplayOne" 4 "AuxIP" 2 "CenterStack" 1 "IPC" ;
VAL_ 2158886912 ODDLI_BckgndFlag 1 "Background response" 0 "Immediate response required" ;
VAL_ 2159132672 ODIAR_DspMID 128 "Reserved" 64 "Reserved" 32 "OTIM" 16 "RearDisplayTwo" 8 "RearDisplayOne" 4 "AuxIP" 2 "CenterStack" 1 "IPC" ;
VAL_ 2159132672 ODIAR_DaTy 21 "Bitmap" 20 "DecimalShort" 19 "HoursOfDay" 18 "Character" 17 "Fuel Consumption Inverted" 16 "Fuel Consumption" 15 "Pressure" 14 "Temperature" 13 "Volume" 12 "DistanceShort" 11 "DistanceLong" 10 "BitmapId" 9 "TextId" 8 "Pictogram" 7 "List " 6 "Date" 5 "Time " 4 "Decimal" 3 "EnumerationValue" 2 "Integer" 1 "String" 0 "Speed" ;
VAL_ 2154692608 LgclAVChnl 0 "None" 1 "Unused and Reserved 1" 2 "Unused and Reserved 2" 3 "Asynchronous Message" 4 "Incoming Call" 5 "Phone" 6 "Synchronous Message" 7 "Speech Recognition" 8 "Emergency Phone Call" 9 "Short Mix Alert Message" 10 "Unused and Reserved 3" 11 "Unused and Reserved 4" 12 "Onstar Initiated Call" ;
VAL_ 2154692608 ASSAudSrcStatCode 5 "Producing Audio" 4 "Producing Silence" 3 "Reserved" 2 "Audio Not Available" 1 "Audio Available" 0 "Device Present" ;
VAL_ 2154692608 ASSAudSrcChType 4 "Mono Emergency" 3 "Mixed" 2 "Stereo" 1 "Mono" 0 "No Action" ;
VAL_ 2154692608 ASSAudSrcType 28 "Phone" 24 "Sat. Digital Audio Receiver System" 20 "Digital Audio Broadcast" 16 "Remote CD Changer" 12 "Remote Digital Video Disk" 8 "Auxiliary Device" 1 "Television Tuner" ;
VAL_ 2152054784 IntPnlClstrAnmtStat 0 "Animation Not Available" 1 "Animation Available" 2 "Welcome Active" 3 "CRANK Active" 4 "RUN Active" 5 "Good Bye Active" ;
VAL_ 2152054784 AnmStrtReq 0 "No Action" 1 "Welcome" 2 "CRANK" 3 "RUN" 4 "Good Bye" ;
VAL_ 2152054784 FuelEconMetDispUnts 0 "Kilometers per liter" 1 "Liters per 100 km" ;
VAL_ 2156281856 LftmEffDtRstRqd 1 "true" 0 "false" ;
VAL_ 2156281856 HTRCsStReq 4 "On Away" 3 "On Home" 2 "On" 1 "Off" 0 "No Action" ;
VAL_ 2156281856 TODCTmpImdtOvrdReq 2 "Active" 1 "Inactive" 0 "No Action" ;
VAL_ 2156281856 RtBsChrgCmplnTmPrfReq 2 "Latest Possible" 1 "Earliest Possible" 0 "No Action" ;
VAL_ 2156281856 TONPDTR_StTmpOvrAtv 0 "No Action" 1 "False (Inactive)" 2 "True (Active)" 3 "Unused and Reserved" ;
VAL_ 2156281856 TONPDTR_DyOfWk 0 "No Action" 1 "Unknown" 2 "Sunday" 3 "Monday" 4 "Tuesday" 5 "Wednesday" 6 "Thursday" 7 "Friday" 8 "Saturday" ;
VAL_ 2156281856 StTODChrgTmpOvrd 1 "true" 0 "false" ;
VAL_ 2156281856 HVBTBSCSR_SsnStReq 3 "Yearly" 0 "No Action" 1 "Summer" 2 "Winter" ;
VAL_ 2156281856 HVBTBSCSR_SsnSlStReq 0 "No Action" 1 "Selected Season" 2 "Start Season" 3 "End Season" ;
VAL_ 2156281856 HVBTBSCSR_SsnMthStReq 0 "No Action" 1 "January" 2 "February" 3 "Mars" 4 "April" 5 "May" 6 "June" 7 "July" 8 "August" 9 "September" 10 "October" 11 "November" 12 "December" ;
VAL_ 2156281856 HVBTBCRSR_ChRtSlStReq 0 "No Action" 1 "Low Rate" 2 "Medium Rate" 3 "High Rate" ;
VAL_ 2156281856 HVBTBCRSR_ChRtEnblStReq 0 "No Action" 1 "Enabled" 2 "Disabled" ;
VAL_ 2156281856 HVBTBCRSR_ChRtDStReq 0 "No Action" 1 "Sunday" 2 "Monday" 3 "Tuesday" 4 "Wednsday" 5 "Thursday" 6 "Friday" 7 "Saturday" 8 "All Days Same" 9 "Mon - Fri Same" 10 "Sat & Sun Same" ;
VAL_ 2156281856 HVBatTmBsChrgMdReq 0 "No Action" 1 "Charge Now" 2 "Delayed Charge" 3 "Rate Based Charge" ;
VAL_ 2156281856 HVChgSyChgLvlPrfSt 0 "No Action" 1 "No Reduction" 2 "Reduced Current Level 1" 3 "Reduced Current Level 2" 4 "Reduced Current Level 3" ;
VAL_ 2156265472 EngyUsgScrnMeasUtStat 15 "Unused and Reserved 9" 14 "Unused and Reserved 8" 13 "Unused and Reserved 7" 12 "Unused and Reserved 6" 11 "Unused and Reserved 5" 10 "Unused and Reserved 4" 9 "Unused and Reserved 3" 8 "Unused and Reserved 2" 7 "Unused and Reserved 1" 6 "km/L e Combined" 5 "km/L" 4 "L/100km e Combined" 3 "L/100km" 2 "MPGe Combined" 1 "MPG" 0 "No Action" ;
VAL_ 2156265472 OffBrdHVCVehCsChRq 1 "true" 0 "false" ;
VAL_ 2156265472 PrtyChrgRq 0 "No Action" 1 "False" 2 "True" ;
VAL_ 2156265472 HVBTBRCSR_RtChSlStReq 0 "No Action" 1 "Charge Start" 2 "Charge End" 3 "Charge Start Invalid" 4 "Charge End Invalid" ;
VAL_ 2156265472 HVBTBRCSR_RtChSlRtStReq 0 "No Action" 1 "Low Rate" 2 "Medium Rate" 3 "High Rate" 4 "Reserved 1" 5 "Invalid Rate" ;
VAL_ 2156265472 HVBTBRCSR_RtChSsnStReq 3 "Yearly" 0 "No Action" 1 "Summer" 2 "Winter" ;
VAL_ 2156265472 HVBTBRCSR_RtChDStReq 0 "No Action" 1 "Sunday" 2 "Monday" 3 "Tuesday" 4 "Wednsday" 5 "Thursday" 6 "Friday" 7 "Saturday" 8 "All Days Same" 9 "Mon - Fri Same" 10 "Sat & Sun Same" ;
VAL_ 2156265472 HVBTBDCSRQ_DlChSlStReq 0 "No Action" 1 "Departure Time 1" 2 "Reserved" 3 "Departure Time 1 Invalid" 4 "Reserved" 5 "Departure Time 2" 6 "Reserved" 7 "Departure Time 2 Invalid" 8 "Reserved" ;
VAL_ 2156265472 HVBTBDCSRQ_DlChSsnStReq 3 "Yearly" 0 "No Action" 1 "Summer" 2 "Winter" ;
VAL_ 2156265472 HVBTBDCSRQ_DlChDStReq 0 "No Action" 1 "Sunday" 2 "Monday" 3 "Tuesday" 4 "Wednsday" 5 "Thursday" 6 "Friday" 7 "Saturday" 8 "All Days Same" 9 "Mon - Fri Same" 10 "Sat & Sun Same" ;
VAL_ 2156265472 ChgPwLsAlCzStRq 0 "No Action" 1 "Off" 2 "On" 3 "Reserved 1" 4 "Reserved 2" 5 "Reserved 3" 6 "Reserved 4" 7 "Reserved 5" ;
VAL_ 2156265472 ChgCdTfAlCzStRq 0 "No Action" 1 "Off" 2 "On" 3 "Reserved 1" 4 "Reserved 2" 5 "Reserved 3" 6 "Reserved 4" 7 "Reserved 5" ;
VAL_ 2156265472 ChgSysAudInCsStReq 0 "No Action" 1 "Off" 2 "On" ;
SIG_GROUP_ 2155012096 SODRtIndCntl 1 : SODRIC_Ind3 SODRIC_Ind2 SODRIC_Ind1 SODRIC_IndReq;
SIG_GROUP_ 2155102208 DrvStMassgPrty 1 : DSMP_UnsdRsrvd DSMP_MaxDispVal DSMP_Type15 DSMP_Type14 DSMP_Type13 DSMP_Type12 DSMP_Type11 DSMP_Type10 DSMP_Type9 DSMP_Type8 DSMP_Type7 DSMP_Type6 DSMP_Type5 DSMP_Type4 DSMP_Type3 DSMP_Type2 DSMP_Type1;
SIG_GROUP_ 2155085824 DrvStCtlDispStat 1 : DSCDS_HdrstUpDn DSCDS_MassgIntsty DSCDS_MassgTyp DSCDS_Massg DSCDS_UnsdRsrvd DSCDS_DispReq DSCDS_DispSz DSCDS_CshLgAdjFdRr DSCDS_BkCshBlstInOt DSCDS_CshBlstrInOut DSCDS_BkBlstrInOut DSCDS_LmbrUDnFdRr DSCDS_LmbrFwdRr DSCDS_LmbrUpDwn DSCDS_UprShldrFdRr DSCDS_HdrstTltFwdRr DSCDS_HdrstWngInOt DSCDS_HdrstUDnFdRr DSCDS_HdrstFwdRrwd;
SIG_GROUP_ 2155069440 DrvStActPrty 1 : DSAP_UnsdRsrvd DSAP_DispSz DSAP_CshLgthAdjFdRr DSAP_BkCshBlstrInOut DSAP_CshBlstrInOut DSAP_BkBlstrInOut DSAP_LmbrUpDnFdRr DSAP_LmbrFwdRr DSAP_LmbrUpDwn DSAP_UprShldrFwdRr DSAP_HdrstTltFwdRr DSAP_HdrstWngsInOut DSAP_HdrstUpDnFdRr DSAP_HdrstFwdRrwd DSAP_HdrstUpDn DSAP_Massg;
SIG_GROUP_ 2150809600 ImpDltVlcSamp12 1 : IDVS12_Axis2 IDVS12_Axis1;
SIG_GROUP_ 2150809600 ImpDltVlcSamp13 1 : IDVS13_Axis2 IDVS13_Axis1;
SIG_GROUP_ 2150809600 ImpDltVlcSamp14 1 : IDVS14_Axis2 IDVS14_Axis1;
SIG_GROUP_ 2150809600 ImpDltVlcSamp15 1 : IDVS15_Axis2 IDVS15_Axis1;
SIG_GROUP_ 2150793216 ImpDltVlcSamp4 1 : IDVS4_Axis2 IDVS4_Axis1;
SIG_GROUP_ 2150793216 ImpDltVlcSamp5 1 : IDVS5_Axis2 IDVS5_Axis1;
SIG_GROUP_ 2150793216 ImpDltVlcSamp6 1 : IDVS6_Axis2 IDVS6_Axis1;
SIG_GROUP_ 2150793216 ImpDltVlcSamp7 1 : IDVS7_Axis2 IDVS7_Axis1;
SIG_GROUP_ 2150801408 ImpDltVlcSamp10 1 : IDVS10_Axis2 IDVS10_Axis1;
SIG_GROUP_ 2150801408 ImpDltVlcSamp11 1 : IDVS11_Axis2 IDVS11_Axis1;
SIG_GROUP_ 2150801408 ImpDltVlcSamp8 1 : IDVS8_Axis2 IDVS8_Axis1;
SIG_GROUP_ 2150801408 ImpDltVlcSamp9 1 : IDVS9_Axis2 IDVS9_Axis1;
SIG_GROUP_ 2150785024 ImpDltVlcSamp1 1 : IDVS1_Axis2 IDVS1_Axis1;
SIG_GROUP_ 2150785024 ImpDltVlcSamp2 1 : IDVS2_Axis2 IDVS2_Axis1;
SIG_GROUP_ 2150785024 ImpDltVlcSamp3 1 : IDVS3_Axis2 IDVS3_Axis1;
SIG_GROUP_ 2150825984 FsnPsngStbltIC 1 : FPSIC_IndPer FPSIC_IO FPSIC_IndDtCyc;
SIG_GROUP_ 2150825984 FsnDrvStbltIC 1 : FDSIC_IndPer FDSIC_IO FDSIC_IndDC;
SIG_GROUP_ 2150825984 AirbgIC 1 : AirbgICIndPer AirbgICDutCyc AirbgICIO;
SIG_GROUP_ 2158886912 ODIDynDataLstRq_IPC 1 : ODDLI_SubIdReqM ODDLI_WrpArnd ODDLI_ReqType ODDLI_ReqDir ODDLI_NmEntries ODDLI_Idx ODDLI_FUCID ODDLI_DspMID ODDLI_DataId ODDLI_BckgndFlag;
SIG_GROUP_ 2159132672 ODIActn_RSD 1 : ODIAR_FUCID ODIAR_DspMID ODIAR_DaTy ODIAR_ActnVal ODIAR_ActnID;
SIG_GROUP_ 2154692608 AudSrcStat 1 : ASSAudSrcStatCode ASSAudSrcChType ASSAudSrcType;
SIG_GROUP_ 2156281856 TmpOvdNxtPlnDptTmRq 1 : TONPDTR_StTmpOvrAtv TONPDTR_MntOfHr TONPDTR_HrOfDy TONPDTR_DyOfWk;
SIG_GROUP_ 2156281856 HVBatTmBsSsnChStReq 1 : HVBTBSCSR_SsnStReq HVBTBSCSR_SsnSlStReq HVBTBSCSR_SsnMthStReq HVBTBSCSR_SsnDayStReq;
SIG_GROUP_ 2156281856 HVBatTmBsChrgRtStReq 1 : HVBTBCRSR_ChRtSlStReq HVBTBCRSR_ChRtEnblStReq HVBTBCRSR_ChRtDStReq;
SIG_GROUP_ 2156265472 HVBatTmBsDlChStReq 1 : HVBTBDCSRQ_DlChMHStReq HVBTBDCSRQ_DlChHStReq HVBTBDCSRQ_DlChDStReq HVBTBDCSRQ_DlChSlStReq HVBTBDCSRQ_DlChSsnStReq;
SIG_GROUP_ 2156265472 HVBatTmBsRtChrgStReq 1 : HVBTBRCSR_RtChSlStReq HVBTBRCSR_RtChSlRtStReq HVBTBRCSR_RtChSsnStReq HVBTBRCSR_RtChMHStReq HVBTBRCSR_RtChHStReq HVBTBRCSR_RtChDStReq HVBTBRCSR_RtChSlTbRwReq;
